AUTOSAR XML (schema 4-2-2)
package /STELLANTIS/EPT/COMSWCs
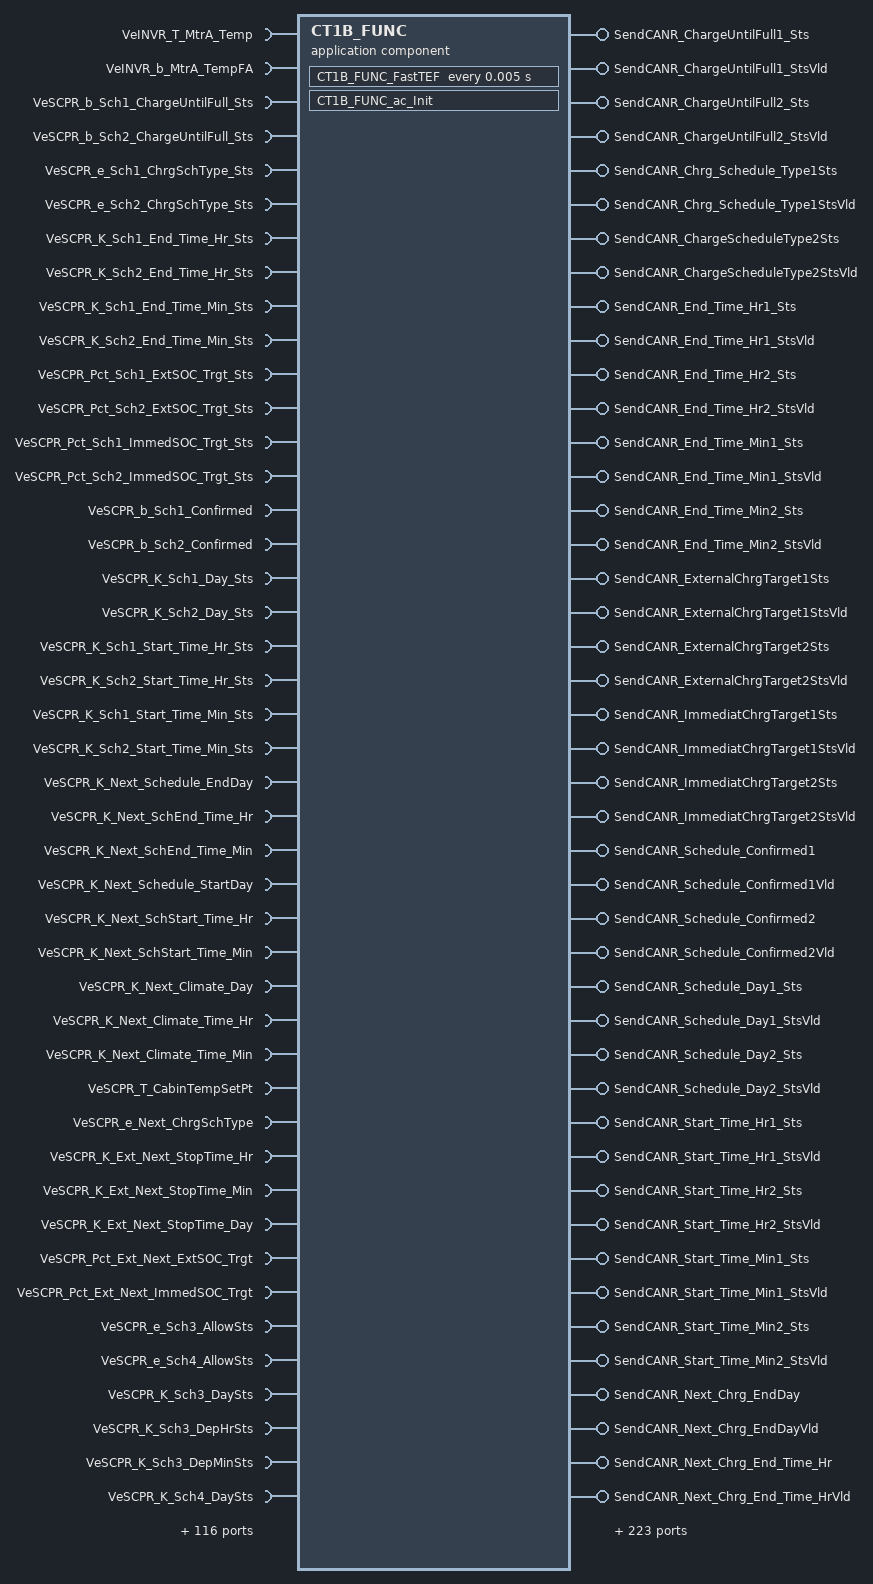
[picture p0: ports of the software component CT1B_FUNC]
  application sw component type CT1B_FUNC
    160 x require port:
      VeINVR_T_MtrA_Temp: variation-point={short-label=vpVeINVR_T_MtrA_Temp, sw-syscond=1}, nonqueued-receiver-com-spec{data-element=Value, init-value=0}, required-interface=VeINVR_T_MtrA_Temp
      VeINVR_b_MtrA_TempFA: variation-point={short-label=vpVeINVR_b_MtrA_TempFA, sw-syscond=1}, nonqueued-receiver-com-spec{data-element=Value, init-value=0}, required-interface=VeINVR_b_MtrA_TempFA
      VeSCPR_b_Sch1_ChargeUntilFull_Sts: nonqueued-receiver-com-spec{data-element=Value, init-value=0}, required-interface=VeSCPR_b_Sch1_ChargeUntilFull_Sts
      VeSCPR_b_Sch2_ChargeUntilFull_Sts: nonqueued-receiver-com-spec{data-element=Value, init-value=0}, required-interface=VeSCPR_b_Sch2_ChargeUntilFull_Sts
      VeSCPR_e_Sch1_ChrgSchType_Sts: nonqueued-receiver-com-spec{data-element=Value, init-value=CeCITR_e_No_Selection}, required-interface=VeSCPR_e_Sch1_ChrgSchType_Sts
      VeSCPR_e_Sch2_ChrgSchType_Sts: nonqueued-receiver-com-spec{data-element=Value, init-value=CeCITR_e_No_Selection}, required-interface=VeSCPR_e_Sch2_ChrgSchType_Sts
      VeSCPR_K_Sch1_End_Time_Hr_Sts: nonqueued-receiver-com-spec{data-element=Value, init-value=0}, required-interface=VeSCPR_K_Sch1_End_Time_Hr_Sts
      VeSCPR_K_Sch2_End_Time_Hr_Sts: nonqueued-receiver-com-spec{data-element=Value, init-value=0}, required-interface=VeSCPR_K_Sch2_End_Time_Hr_Sts
      VeSCPR_K_Sch1_End_Time_Min_Sts: nonqueued-receiver-com-spec{data-element=Value, init-value=0}, required-interface=VeSCPR_K_Sch1_End_Time_Min_Sts
      VeSCPR_K_Sch2_End_Time_Min_Sts: nonqueued-receiver-com-spec{data-element=Value, init-value=0}, required-interface=VeSCPR_K_Sch2_End_Time_Min_Sts
      VeSCPR_Pct_Sch1_ExtSOC_Trgt_Sts: nonqueued-receiver-com-spec{data-element=Value, init-value=0}, required-interface=VeSCPR_Pct_Sch1_ExtSOC_Trgt_Sts
      VeSCPR_Pct_Sch2_ExtSOC_Trgt_Sts: nonqueued-receiver-com-spec{data-element=Value, init-value=0}, required-interface=VeSCPR_Pct_Sch2_ExtSOC_Trgt_Sts
      VeSCPR_Pct_Sch1_ImmedSOC_Trgt_Sts: nonqueued-receiver-com-spec{data-element=Value, init-value=0}, required-interface=VeSCPR_Pct_Sch1_ImmedSOC_Trgt_Sts
      VeSCPR_Pct_Sch2_ImmedSOC_Trgt_Sts: nonqueued-receiver-com-spec{data-element=Value, init-value=0}, required-interface=VeSCPR_Pct_Sch2_ImmedSOC_Trgt_Sts
      VeSCPR_b_Sch1_Confirmed: nonqueued-receiver-com-spec{data-element=Value, init-value=0}, required-interface=VeSCPR_b_Sch1_Confirmed
      VeSCPR_b_Sch2_Confirmed: nonqueued-receiver-com-spec{data-element=Value, init-value=0}, required-interface=VeSCPR_b_Sch2_Confirmed
      VeSCPR_K_Sch1_Day_Sts: nonqueued-receiver-com-spec{data-element=Value, init-value=0}, required-interface=VeSCPR_K_Sch1_Day_Sts
      VeSCPR_K_Sch2_Day_Sts: nonqueued-receiver-com-spec{data-element=Value, init-value=0}, required-interface=VeSCPR_K_Sch2_Day_Sts
      VeSCPR_K_Sch1_Start_Time_Hr_Sts: nonqueued-receiver-com-spec{data-element=Value, init-value=0}, required-interface=VeSCPR_K_Sch1_Start_Time_Hr_Sts
      VeSCPR_K_Sch2_Start_Time_Hr_Sts: nonqueued-receiver-com-spec{data-element=Value, init-value=0}, required-interface=VeSCPR_K_Sch2_Start_Time_Hr_Sts
      VeSCPR_K_Sch1_Start_Time_Min_Sts: nonqueued-receiver-com-spec{data-element=Value, init-value=0}, required-interface=VeSCPR_K_Sch1_Start_Time_Min_Sts
      VeSCPR_K_Sch2_Start_Time_Min_Sts: nonqueued-receiver-com-spec{data-element=Value, init-value=0}, required-interface=VeSCPR_K_Sch2_Start_Time_Min_Sts
      VeSCPR_K_Next_Schedule_EndDay: nonqueued-receiver-com-spec{data-element=Value, init-value=0}, required-interface=VeSCPR_K_Next_Schedule_EndDay
      VeSCPR_K_Next_SchEnd_Time_Hr: nonqueued-receiver-com-spec{data-element=Value, init-value=0}, required-interface=VeSCPR_K_Next_SchEnd_Time_Hr
      VeSCPR_K_Next_SchEnd_Time_Min: nonqueued-receiver-com-spec{data-element=Value, init-value=0}, required-interface=VeSCPR_K_Next_SchEnd_Time_Min
      VeSCPR_K_Next_Schedule_StartDay: nonqueued-receiver-com-spec{data-element=Value, init-value=0}, required-interface=VeSCPR_K_Next_Schedule_StartDay
      VeSCPR_K_Next_SchStart_Time_Hr: nonqueued-receiver-com-spec{data-element=Value, init-value=0}, required-interface=VeSCPR_K_Next_SchStart_Time_Hr
      VeSCPR_K_Next_SchStart_Time_Min: nonqueued-receiver-com-spec{data-element=Value, init-value=0}, required-interface=VeSCPR_K_Next_SchStart_Time_Min
      VeSCPR_K_Next_Climate_Day: nonqueued-receiver-com-spec{data-element=Value, init-value=0}, required-interface=VeSCPR_K_Next_Climate_Day
      VeSCPR_K_Next_Climate_Time_Hr: nonqueued-receiver-com-spec{data-element=Value, init-value=0}, required-interface=VeSCPR_K_Next_Climate_Time_Hr
      VeSCPR_K_Next_Climate_Time_Min: nonqueued-receiver-com-spec{data-element=Value, init-value=0}, required-interface=VeSCPR_K_Next_Climate_Time_Min
      VeSCPR_T_CabinTempSetPt: nonqueued-receiver-com-spec{data-element=Value, init-value=0}, required-interface=VeSCPR_T_CabinTempSetPt
      VeSCPR_e_Next_ChrgSchType: nonqueued-receiver-com-spec{data-element=Value, init-value=CeSCPR_e_No_Selection}, required-interface=VeSCPR_e_Next_ChrgSchType
      VeSCPR_K_Ext_Next_StopTime_Hr: nonqueued-receiver-com-spec{data-element=Value, init-value=0}, required-interface=VeSCPR_K_Ext_Next_StopTime_Hr
      VeSCPR_K_Ext_Next_StopTime_Min: nonqueued-receiver-com-spec{data-element=Value, init-value=0}, required-interface=VeSCPR_K_Ext_Next_StopTime_Min
      VeSCPR_K_Ext_Next_StopTime_Day: nonqueued-receiver-com-spec{data-element=Value, init-value=0}, required-interface=VeSCPR_K_Ext_Next_StopTime_Day
      VeSCPR_Pct_Ext_Next_ExtSOC_Trgt: nonqueued-receiver-com-spec{data-element=Value, init-value=0}, required-interface=VeSCPR_Pct_Ext_Next_ExtSOC_Trgt
      VeSCPR_Pct_Ext_Next_ImmedSOC_Trgt: nonqueued-receiver-com-spec{data-element=Value, init-value=0}, required-interface=VeSCPR_Pct_Ext_Next_ImmedSOC_Trgt
      VeSCPR_e_Sch3_AllowSts: nonqueued-receiver-com-spec{data-element=Value, init-value=CeCITR_e_AnyTime}, required-interface=VeSCPR_e_Sch3_AllowSts
      VeSCPR_e_Sch4_AllowSts: nonqueued-receiver-com-spec{data-element=Value, init-value=CeCITR_e_AnyTime}, required-interface=VeSCPR_e_Sch4_AllowSts
      VeSCPR_K_Sch3_DaySts: nonqueued-receiver-com-spec{data-element=Value, init-value=0}, required-interface=VeSCPR_K_Sch3_DaySts
      VeSCPR_K_Sch3_DepHrSts: nonqueued-receiver-com-spec{data-element=Value, init-value=0}, required-interface=VeSCPR_K_Sch3_DepHrSts
      VeSCPR_K_Sch3_DepMinSts: nonqueued-receiver-com-spec{data-element=Value, init-value=0}, required-interface=VeSCPR_K_Sch3_DepMinSts
      VeSCPR_K_Sch4_DaySts: nonqueued-receiver-com-spec{data-element=Value, init-value=0}, required-interface=VeSCPR_K_Sch4_DaySts
      VeSCPR_K_Sch4_DepHrSts: nonqueued-receiver-com-spec{data-element=Value, init-value=0}, required-interface=VeSCPR_K_Sch4_DepHrSts
      VeSCPR_K_Sch4_DepMinSts: nonqueued-receiver-com-spec{data-element=Value, init-value=0}, required-interface=VeSCPR_K_Sch4_DepMinSts
      VeSCPR_T_Sch3_DepTempSts: nonqueued-receiver-com-spec{data-element=Value, init-value=0}, required-interface=VeSCPR_T_Sch3_DepTempSts
      VeSCPR_T_Sch4_DepTempSts: nonqueued-receiver-com-spec{data-element=Value, init-value=0}, required-interface=VeSCPR_T_Sch4_DepTempSts
      VeSCPR_b_Sch3_EnblSts: nonqueued-receiver-com-spec{data-element=Value, init-value=0}, required-interface=VeSCPR_b_Sch3_EnblSts
      VeSCPR_b_Sch4_EnblSts: nonqueued-receiver-com-spec{data-element=Value, init-value=0}, required-interface=VeSCPR_b_Sch4_EnblSts
      VeVTHR_e_FOTA_ReadySts: variation-point={short-label=vpVeVTHR_e_FOTA_ReadySts, sw-syscond=1}, nonqueued-receiver-com-spec{data-element=Value, init-value=CeVTHR_e_Eval_in_Progress}, required-interface=VeVTHR_e_FOTA_ReadySts
      VeOBCR_e_ChargeportLock_Sts: nonqueued-receiver-com-spec{data-element=Value, init-value=CeOBCR_e_PortLockSts_Default}, required-interface=VeOBCR_e_ChargeportLock_Sts
      VeSCPR_e_CoopChrgStatus: nonqueued-receiver-com-spec{data-element=Value, init-value=CeSCPR_e_DefaultSts}, required-interface=VeSCPR_e_CoopChrgStatus
      VeOBCR_P_EVSEPwr: variation-point={short-label=vpVeOBCR_P_EVSEPwr, sw-syscond=1}, nonqueued-receiver-com-spec{data-element=Value, init-value=0}, required-interface=VeOBCR_P_EVSEPwr
      VeOBCR_I_ChrgCrntReqDelta: variation-point={short-label=vpVeOBCR_I_ChrgCrntReqDelta, sw-syscond=1}, nonqueued-receiver-com-spec{data-element=Value, init-value=0}, required-interface=VeOBCR_I_ChrgCrntReqDelta
      VeOBCR_P_PowertoBattery: variation-point={short-label=vpVeOBCR_P_PowertoBattery, sw-syscond=1}, nonqueued-receiver-com-spec{data-element=Value, init-value=0}, required-interface=VeOBCR_P_PowertoBattery
      VeOBCR_q_BatteryAmpHrCap: variation-point={short-label=vpVeOBCR_q_BatteryAmpHrCap, sw-syscond=1}, nonqueued-receiver-com-spec{data-element=Value, init-value=0}, required-interface=VeOBCR_q_BatteryAmpHrCap
      VeVTLR_e_DschrgSysSts: nonqueued-receiver-com-spec{data-element=Value, init-value=CeVTLR_e_DschrgInactv}, required-interface=VeVTLR_e_DschrgSysSts
      VeTIMR_e_LaunchMdSwtchLED: variation-point={short-label=vpVeTIMR_e_LaunchMdSwtchLED, sw-syscond=1}, nonqueued-receiver-com-spec{data-element=Value, init-value=CeTIMR_e_LEDOff}, required-interface=VeTIMR_e_LaunchMdSwtchLED
      VeOBCR_b_PnCFailure: nonqueued-receiver-com-spec{data-element=Value, init-value=0}, required-interface=VeOBCR_b_PnCFailure
      VeOBCR_b_PnCRetryFail: nonqueued-receiver-com-spec{data-element=Value, init-value=0}, required-interface=VeOBCR_b_PnCRetryFail
      VeTPCR_b_RacePrepAmbCheck: variation-point={short-label=vpVeTPCR_b_RacePrepAmbCheck, sw-syscond=1}, nonqueued-receiver-com-spec{data-element=Value, init-value=0}, required-interface=VeTPCR_b_RacePrepAmbCheck
      VeOBCR_b_RacePrepBattLvlSts: variation-point={short-label=vpVeOBCR_b_RacePrepBattLvlSts, sw-syscond=1}, nonqueued-receiver-com-spec{data-element=Value, init-value=0}, required-interface=VeOBCR_b_RacePrepBattLvlSts
      VeTPCR_t_RacePrep_DeacTime: variation-point={short-label=vpVeTPCR_t_RacePrep_DeacTime, sw-syscond=1}, nonqueued-receiver-com-spec{data-element=Value, init-value=0}, required-interface=VeTPCR_t_RacePrep_DeacTime
      VeTPCR_b_RacePrepEVSysStatus: variation-point={short-label=vpVeTPCR_b_RacePrepEVSysStatus, sw-syscond=1}, nonqueued-receiver-com-spec{data-element=Value, init-value=0}, required-interface=VeTPCR_b_RacePrepEVSysStatus
      VeTPCR_T_RacePrep_SOCTrgt: variation-point={short-label=vpVeTPCR_T_RacePrep_SOCTrgt, sw-syscond=1}, nonqueued-receiver-com-spec{data-element=Value, init-value=0}, required-interface=VeTPCR_T_RacePrep_SOCTrgt
      VeTIMR_e_RacePrepRaceTypeSts: variation-point={short-label=vpVeTIMR_e_RacePrepRaceTypeSts, sw-syscond=1}, nonqueued-receiver-com-spec{data-element=Value, init-value=CeTIMR_e_RaceType_Drag}, required-interface=VeTIMR_e_RacePrepRaceTypeSts
      VeTPCR_T_RacePrep_ThrmlTrgt: variation-point={short-label=vpVeTPCR_T_RacePrep_ThrmlTrgt, sw-syscond=1}, nonqueued-receiver-com-spec{data-element=Value, init-value=0}, required-interface=VeTPCR_T_RacePrep_ThrmlTrgt
      VeERER_l_AC_Fan_Range: variation-point={short-label=vpVeERER_l_AC_Fan_Range, sw-syscond=1}, nonqueued-receiver-com-spec{data-element=Value, init-value=0}, required-interface=VeERER_l_AC_Fan_Range
      VeERER_b_ACFanRange_SNA: variation-point={short-label=vpVeERER_b_ACFanRange_SNA, sw-syscond=1}, nonqueued-receiver-com-spec{data-element=Value, init-value=0}, required-interface=VeERER_b_ACFanRange_SNA
      VeERER_l_Audio_Range: variation-point={short-label=vpVeERER_l_Audio_Range, sw-syscond=1}, nonqueued-receiver-com-spec{data-element=Value, init-value=0}, required-interface=VeERER_l_Audio_Range
      VeERER_b_AudioRange_SNA: variation-point={short-label=vpVeERER_b_AudioRange_SNA, sw-syscond=1}, nonqueued-receiver-com-spec{data-element=Value, init-value=0}, required-interface=VeERER_b_AudioRange_SNA
      VeERER_l_Defrost_Range: variation-point={short-label=vpVeERER_l_Defrost_Range, sw-syscond=1}, nonqueued-receiver-com-spec{data-element=Value, init-value=0}, required-interface=VeERER_l_Defrost_Range
      VeERER_b_DefrostRange_SNA: variation-point={short-label=vpVeERER_b_DefrostRange_SNA, sw-syscond=1}, nonqueued-receiver-com-spec{data-element=Value, init-value=0}, required-interface=VeERER_b_DefrostRange_SNA
      VeERER_l_Lights_Range: variation-point={short-label=vpVeERER_l_Lights_Range, sw-syscond=1}, nonqueued-receiver-com-spec{data-element=Value, init-value=0}, required-interface=VeERER_l_Lights_Range
      VeERER_b_LightsRange_SNA: variation-point={short-label=vpVeERER_b_LightsRange_SNA, sw-syscond=1}, nonqueued-receiver-com-spec{data-element=Value, init-value=0}, required-interface=VeERER_b_LightsRange_SNA
      VeERER_l_Other_Range: variation-point={short-label=vpVeERER_l_Other_Range, sw-syscond=1}, nonqueued-receiver-com-spec{data-element=Value, init-value=0}, required-interface=VeERER_l_Other_Range
      VeERER_b_OtherRange_SNA: variation-point={short-label=vpVeERER_b_OtherRange_SNA, sw-syscond=1}, nonqueued-receiver-com-spec{data-element=Value, init-value=0}, required-interface=VeERER_b_OtherRange_SNA
      VeERER_l_Seatswhl_Range: variation-point={short-label=vpVeERER_l_Seatswhl_Range, sw-syscond=1}, nonqueued-receiver-com-spec{data-element=Value, init-value=0}, required-interface=VeERER_l_Seatswhl_Range
      VeERER_b_SeatswhlRange_SNA: variation-point={short-label=vpVeERER_b_SeatswhlRange_SNA, sw-syscond=1}, nonqueued-receiver-com-spec{data-element=Value, init-value=0}, required-interface=VeERER_b_SeatswhlRange_SNA
      VeERER_l_Total_Range: variation-point={short-label=vpVeERER_l_Total_Range, sw-syscond=1}, nonqueued-receiver-com-spec{data-element=Value, init-value=0}, required-interface=VeERER_l_Total_Range
      VeERER_b_TotalRange_SNA: variation-point={short-label=vpVeERER_b_TotalRange_SNA, sw-syscond=1}, nonqueued-receiver-com-spec{data-element=Value, init-value=0}, required-interface=VeERER_b_TotalRange_SNA
      VeTIMR_e_RaceMdPopUp: nonqueued-receiver-com-spec{data-element=Value, init-value=CeTIMR_e_TM0}, required-interface=VeTIMR_e_RaceMdPopUp
      VeTHMR_e_CabinPreCondReqStat: nonqueued-receiver-com-spec{data-element=Value, init-value=0}, required-interface=VeTHMR_e_CabinPreCondReqStat
      VeTHMR_e_CabinPreCondReqMsg: nonqueued-receiver-com-spec{data-element=Value, init-value=0}, required-interface=VeTHMR_e_CabinPreCondReqMsg
      VeTAIR_e_CompStat: nonqueued-receiver-com-spec{data-element=Value, init-value=CeTAIR_e_NormalOp}, required-interface=VeTAIR_e_CompStat
      VeTMIR_T_ElecClntHtr_TmpIn: nonqueued-receiver-com-spec{data-element=Value, init-value=0}, required-interface=VeTMIR_T_ElecClntHtr_TmpIn
      VeTMIR_b_ElecClntHtr_TmpIn_FA: nonqueued-receiver-com-spec{data-element=Value, init-value=0}, required-interface=VeTMIR_b_ElecClntHtr_TmpIn_FA
      VeHTRR_P_HVC_HtrPwrAct: nonqueued-receiver-com-spec{data-element=Value, init-value=0}, required-interface=VeHTRR_P_HVC_HtrPwrAct
      VeRCVR_b_FtRfgtShtoff_VlvSts: nonqueued-receiver-com-spec{data-element=Value, init-value=0}, required-interface=VeRCVR_b_FtRfgtShtoff_VlvSts
      VePMIR_e_HTAuxPumpMntrRPM: nonqueued-receiver-com-spec{data-element=Value, init-value=CePMPR_e_TFSNA_False}, required-interface=VePMIR_e_HTAuxPumpMntrRPM
      VePMIR_b_HTAuxPumpMntrRPM_FA: nonqueued-receiver-com-spec{data-element=Value, init-value=0}, required-interface=VePMIR_b_HTAuxPumpMntrRPM_FA
      VePMIR_n_HTAuxPumpRPMAct: nonqueued-receiver-com-spec{data-element=Value, init-value=0}, required-interface=VePMIR_n_HTAuxPumpRPMAct
      VePMIR_b_HTAuxPumpRPMAct_FA: nonqueued-receiver-com-spec{data-element=Value, init-value=0}, required-interface=VePMIR_b_HTAuxPumpRPMAct_FA
      VeRCVR_b_HT_Shtoff_VlvCmd: nonqueued-receiver-com-spec{data-element=Value, init-value=0}, required-interface=VeRCVR_b_HT_Shtoff_VlvCmd
      VeTHMR_e_HV_Bat_CltLvlLo: nonqueued-receiver-com-spec{data-element=Value, init-value=CeBRDR_e_BatCltLvlNotLo}, required-interface=VeTHMR_e_HV_Bat_CltLvlLo
      VeTHMR_b_HV_BatTempCrit_Cond: nonqueued-receiver-com-spec{data-element=Value, init-value=0}, required-interface=VeTHMR_b_HV_BatTempCrit_Cond
      VeTRIR_T_HtrCorClnt_TmpIn: nonqueued-receiver-com-spec{data-element=Value, init-value=0}, required-interface=VeTRIR_T_HtrCorClnt_TmpIn
      VeTRIR_b_HtrCorClnt_TmpIn_FA: nonqueued-receiver-com-spec{data-element=Value, init-value=0}, required-interface=VeTRIR_b_HtrCorClnt_TmpIn_FA
      VeHTIR_T_Htr2CoreTemp: nonqueued-receiver-com-spec{data-element=Value, init-value=0}, required-interface=VeHTIR_T_Htr2CoreTemp
      VeHTIR_T_Htr2_PCBTemp: nonqueued-receiver-com-spec{data-element=Value, init-value=0}, required-interface=VeHTIR_T_Htr2_PCBTemp
      VeHTRR_Pct_HV_Htr2PwrAct: nonqueued-receiver-com-spec{data-element=Value, init-value=0}, required-interface=VeHTRR_Pct_HV_Htr2PwrAct
      VeTPCR_t_TimeToDeparture: nonqueued-receiver-com-spec{data-element=Value, init-value=0}, required-interface=VeTPCR_t_TimeToDeparture
      VeTHMR_e_SC_WkUp: nonqueued-receiver-com-spec{data-element=Value, init-value=CeTPCR_e_SC_NotAwake}, required-interface=VeTHMR_e_SC_WkUp
      VeVTHR_P_V2H_DschgCap: variation-point={short-label=vpVeVTHR_P_V2H_DschgCap, sw-syscond=1}, nonqueued-receiver-com-spec{data-element=Value, init-value=0}, required-interface=VeVTHR_P_V2H_DschgCap
      VeINVR_I_MtrA_DC_Crnt: variation-point={short-label=vpVeINVR_I_MtrA_DC_Crnt, sw-syscond=1}, nonqueued-receiver-com-spec{data-element=Value, init-value=0}, required-interface=VeINVR_I_MtrA_DC_Crnt
      VeINVR_b_MtrA_DC_CrntFA: variation-point={short-label=vpVeINVR_b_MtrA_DC_CrntFA, sw-syscond=1}, nonqueued-receiver-com-spec{data-element=Value, init-value=0}, required-interface=VeINVR_b_MtrA_DC_CrntFA
      VeINVR_U_MtrA_DC_Volt: variation-point={short-label=vpVeINVR_U_MtrA_DC_Volt, sw-syscond=1}, nonqueued-receiver-com-spec{data-element=Value, init-value=0}, required-interface=VeINVR_U_MtrA_DC_Volt
      VeINVR_b_MtrA_DC_VoltFA: variation-point={short-label=vpVeINVR_b_MtrA_DC_VoltFA, sw-syscond=1}, nonqueued-receiver-com-spec{data-element=Value, init-value=0}, required-interface=VeINVR_b_MtrA_DC_VoltFA
      VeINVR_e_MtrA_InvrtrSt: variation-point={short-label=vpVeINVR_e_MtrA_InvrtrSt, sw-syscond=1}, nonqueued-receiver-com-spec{data-element=Value, init-value=CeINVR_e_NormalPowerStageOff}, required-interface=VeINVR_e_MtrA_InvrtrSt
      VeINVR_T_MtrA_InvrtrTemp: variation-point={short-label=vpVeINVR_T_MtrA_InvrtrTemp, sw-syscond=1}, nonqueued-receiver-com-spec{data-element=Value, init-value=0}, required-interface=VeINVR_T_MtrA_InvrtrTemp
      VeINVR_b_MtrA_InvrtrTempFA: variation-point={short-label=vpVeINVR_b_MtrA_InvrtrTempFA, sw-syscond=1}, nonqueued-receiver-com-spec{data-element=Value, init-value=0}, required-interface=VeINVR_b_MtrA_InvrtrTempFA
      VeMSPR_n_MtrA_Spd: variation-point={short-label=vpVeMSPR_n_MtrA_Spd, sw-syscond=1}, nonqueued-receiver-com-spec{data-element=Value, init-value=0}, required-interface=VeMSPR_n_MtrA_Spd
      VeMSPR_b_MtrA_SpdFA: variation-point={short-label=vpVeMSPR_b_MtrA_SpdFA, sw-syscond=1}, nonqueued-receiver-com-spec{data-element=Value, init-value=0}, required-interface=VeMSPR_b_MtrA_SpdFA
      VeMTIR_M_MtrA_TorqAchieved: variation-point={short-label=vpVeMTIR_M_MtrA_TorqAchieved, sw-syscond=1}, nonqueued-receiver-com-spec{data-element=Value, init-value=0}, required-interface=VeMTIR_M_MtrA_TorqAchieved
      VeMTIR_b_MtrA_TorqAchievedFA: variation-point={short-label=vpVeMTIR_b_MtrA_TorqAchievedFA, sw-syscond=1}, nonqueued-receiver-com-spec{data-element=Value, init-value=0}, required-interface=VeMTIR_b_MtrA_TorqAchievedFA
      VeINVR_I_MtrB_DC_Crnt: nonqueued-receiver-com-spec{data-element=Value, init-value=0}, required-interface=VeINVR_I_MtrB_DC_Crnt
      VeINVR_b_MtrB_DC_CrntFA: nonqueued-receiver-com-spec{data-element=Value, init-value=0}, required-interface=VeINVR_b_MtrB_DC_CrntFA
      VeINVR_U_MtrB_DC_Volt: nonqueued-receiver-com-spec{data-element=Value, init-value=0}, required-interface=VeINVR_U_MtrB_DC_Volt
      VeINVR_b_MtrB_DC_VoltFA: nonqueued-receiver-com-spec{data-element=Value, init-value=0}, required-interface=VeINVR_b_MtrB_DC_VoltFA
      VeINVR_e_MtrB_InvrtrSt: nonqueued-receiver-com-spec{data-element=Value, init-value=CeINVR_e_NormalPowerStageOff}, required-interface=VeINVR_e_MtrB_InvrtrSt
      VeINVR_T_MtrB_InvrtrTemp: nonqueued-receiver-com-spec{data-element=Value, init-value=0}, required-interface=VeINVR_T_MtrB_InvrtrTemp
      VeINVR_b_MtrB_InvrtrTempFA: nonqueued-receiver-com-spec{data-element=Value, init-value=0}, required-interface=VeINVR_b_MtrB_InvrtrTempFA
      VeMSPR_n_MtrB_Spd: nonqueued-receiver-com-spec{data-element=Value, init-value=0}, required-interface=VeMSPR_n_MtrB_Spd
      VeMSPR_b_MtrB_SpdFA: nonqueued-receiver-com-spec{data-element=Value, init-value=0}, required-interface=VeMSPR_b_MtrB_SpdFA
      VeINVR_T_MtrB_Temp: nonqueued-receiver-com-spec{data-element=Value, init-value=0}, required-interface=VeINVR_T_MtrB_Temp
      VeINVR_b_MtrB_TempFA: nonqueued-receiver-com-spec{data-element=Value, init-value=0}, required-interface=VeINVR_b_MtrB_TempFA
      VeMTIR_M_MtrB_TorqAchieved: nonqueued-receiver-com-spec{data-element=Value, init-value=0}, required-interface=VeMTIR_M_MtrB_TorqAchieved
      VeMTIR_b_MtrB_TorqAchievedFA: nonqueued-receiver-com-spec{data-element=Value, init-value=0}, required-interface=VeMTIR_b_MtrB_TorqAchievedFA
      VeTHMR_Pct_AirFlowReq: nonqueued-receiver-com-spec{data-element=Value, init-value=0}, required-interface=VeTHMR_Pct_AirFlowReq
      VeTAIR_Pct_RadFanSts: nonqueued-receiver-com-spec{data-element=Value, init-value=0}, required-interface=VeTAIR_Pct_RadFanSts
      VeTAIR_b_RadFanSts_FA: nonqueued-receiver-com-spec{data-element=Value, init-value=0}, required-interface=VeTAIR_b_RadFanSts_FA
      VeOBCR_P_ActChargePowerLim: variation-point={short-label=vpVeOBCR_P_ActChargePowerLim, sw-syscond=1}, nonqueued-receiver-com-spec{data-element=Value, init-value=0}, required-interface=VeOBCR_P_ActChargePowerLim
      VeOBCR_b_ActChargePowerLimFA: variation-point={short-label=vpVeOBCR_b_ActChargePowerLimFA, sw-syscond=1}, nonqueued-receiver-com-spec{data-element=Value, init-value=0}, required-interface=VeOBCR_b_ActChargePowerLimFA
      VeOBCR_P_ActChargePower: variation-point={short-label=vpVeOBCR_P_ActChargePower, sw-syscond=1}, nonqueued-receiver-com-spec{data-element=Value, init-value=0}, required-interface=VeOBCR_P_ActChargePower
      VeOBCR_b_ActChargePowerFA: variation-point={short-label=vpVeOBCR_b_ActChargePowerFA, sw-syscond=1}, nonqueued-receiver-com-spec{data-element=Value, init-value=0}, required-interface=VeOBCR_b_ActChargePowerFA
      VeVTHR_P_V2H_InstPwrDraw: variation-point={short-label=vpVeVTHR_P_V2H_InstPwrDraw, sw-syscond=1}, nonqueued-receiver-com-spec{data-element=Value, init-value=0}, required-interface=VeVTHR_P_V2H_InstPwrDraw
      VeVTHR_Pct_V2H_ResrvBattSts: variation-point={short-label=vpVeVTHR_Pct_V2H_ResrvBattSts, sw-syscond=1}, nonqueued-receiver-com-spec{data-element=Value, init-value=0}, required-interface=VeVTHR_Pct_V2H_ResrvBattSts
      VeVTHR_e_V2H_Sts: variation-point={short-label=vpVeVTHR_e_V2H_Sts, sw-syscond=1}, nonqueued-receiver-com-spec{data-element=Value, init-value=CeVTHR_e_V2H_Inactive}, required-interface=VeVTHR_e_V2H_Sts
      VeVTHR_t_V2H_TotPwrDays: variation-point={short-label=vpVeVTHR_t_V2H_TotPwrDays, sw-syscond=1}, nonqueued-receiver-com-spec{data-element=Value, init-value=0}, required-interface=VeVTHR_t_V2H_TotPwrDays
      VeVTHR_t_V2H_TotPwrHrs: variation-point={short-label=vpVeVTHR_t_V2H_TotPwrHrs, sw-syscond=1}, nonqueued-receiver-com-spec{data-element=Value, init-value=0}, required-interface=VeVTHR_t_V2H_TotPwrHrs
      VeVTHR_t_V2H_TotPwrMin: variation-point={short-label=vpVeVTHR_t_V2H_TotPwrMin, sw-syscond=1}, nonqueued-receiver-com-spec{data-element=Value, init-value=0}, required-interface=VeVTHR_t_V2H_TotPwrMin
      VeVTHR_b_V2H_MdSts: variation-point={short-label=vpVeVTHR_b_V2H_MdSts, sw-syscond=1}, nonqueued-receiver-com-spec{data-element=Value, init-value=0}, required-interface=VeVTHR_b_V2H_MdSts
      VeVTLR_e_FrunkSts: nonqueued-receiver-com-spec{data-element=Value, init-value=CeVTLR_e_Inactive_Frunk}, required-interface=VeVTLR_e_FrunkSts
      VeVTLR_P_InstantPwr_PPIM: nonqueued-receiver-com-spec{data-element=Value, init-value=0}, required-interface=VeVTLR_P_InstantPwr_PPIM
      VeVTLR_P_InstantPwr_IDCM: nonqueued-receiver-com-spec{data-element=Value, init-value=0}, required-interface=VeVTLR_P_InstantPwr_IDCM
      VeVTLR_t_DschrgDays: nonqueued-receiver-com-spec{data-element=Value, init-value=0}, required-interface=VeVTLR_t_DschrgDays
      VeVTLR_t_DschrgHrs: nonqueued-receiver-com-spec{data-element=Value, init-value=0}, required-interface=VeVTLR_t_DschrgHrs
      VeVTLR_t_DschrgMins: nonqueued-receiver-com-spec{data-element=Value, init-value=0}, required-interface=VeVTLR_t_DschrgMins
      VeVTLR_e_TrunkSts: nonqueued-receiver-com-spec{data-element=Value, init-value=CeVTLR_e_Inactive}, required-interface=VeVTLR_e_TrunkSts
      VeVDVR_P_V2V_InstPwrDraw: nonqueued-receiver-com-spec{data-element=Value, init-value=0}, required-interface=VeVDVR_P_V2V_InstPwrDraw
      VeVDVR_e_V2V_Status: nonqueued-receiver-com-spec{data-element=Value, init-value=CeVDVR_e_Inctv}, required-interface=VeVDVR_e_V2V_Status
      VeVDVR_t_V2V_TotalPwrTimeDay: nonqueued-receiver-com-spec{data-element=Value, init-value=0}, required-interface=VeVDVR_t_V2V_TotalPwrTimeDay
      VeVDVR_t_V2V_TotalPwrTimeHs: nonqueued-receiver-com-spec{data-element=Value, init-value=0}, required-interface=VeVDVR_t_V2V_TotalPwrTimeHs
      VeVDVR_t_V2V_TotalPwrTimeMin: nonqueued-receiver-com-spec{data-element=Value, init-value=0}, required-interface=VeVDVR_t_V2V_TotalPwrTimeMin
      VeEBMR_t_PrepCntDwn: nonqueued-receiver-com-spec{data-element=Value, init-value=0}, required-interface=VeEBMR_t_PrepCntDwn
      VeEBMR_Pct_PwrSht_Prep: nonqueued-receiver-com-spec{data-element=Value, init-value=0}, required-interface=VeEBMR_Pct_PwrSht_Prep
      VeASLR_v_TurtleMdSpdLim: nonqueued-receiver-com-spec{data-element=Value, init-value=0}, required-interface=VeASLR_v_TurtleMdSpdLim
      VeTMIR_T_OnBrdChrg_ClntTmpIn: nonqueued-receiver-com-spec{data-element=Value, init-value=0}, required-interface=VeTMIR_T_OnBrdChrg_ClntTmpIn
      VeTMIR_b_OnBrdChrg_ClntTmpIn_FA: nonqueued-receiver-com-spec{data-element=Value, init-value=0}, required-interface=VeTMIR_b_OnBrdChrg_ClntTmpIn_FA
    267 x provide port:
      SendCANR_ChargeUntilFull1_Sts: nonqueued-sender-com-spec{data-element=SendCANR_ChargeUntilFull1_Sts, init-value=0}, provided-interface=SendCANR_ChargeUntilFull1_Sts
      SendCANR_ChargeUntilFull1_StsVld: nonqueued-sender-com-spec{data-element=SendCANR_ChargeUntilFull1_StsVld, init-value=0}, provided-interface=SendCANR_ChargeUntilFull1_StsVld
      SendCANR_ChargeUntilFull2_Sts: nonqueued-sender-com-spec{data-element=SendCANR_ChargeUntilFull2_Sts, init-value=0}, provided-interface=SendCANR_ChargeUntilFull2_Sts
      SendCANR_ChargeUntilFull2_StsVld: nonqueued-sender-com-spec{data-element=SendCANR_ChargeUntilFull2_StsVld, init-value=0}, provided-interface=SendCANR_ChargeUntilFull2_StsVld
      SendCANR_Chrg_Schedule_Type1Sts: nonqueued-sender-com-spec{data-element=SendCANR_Chrg_Schedule_Type1Sts, init-value=0}, provided-interface=SendCANR_Chrg_Schedule_Type1Sts
      SendCANR_Chrg_Schedule_Type1StsVld: nonqueued-sender-com-spec{data-element=SendCANR_Chrg_Schedule_Type1StsVld, init-value=0}, provided-interface=SendCANR_Chrg_Schedule_Type1StsVld
      SendCANR_ChargeScheduleType2Sts: nonqueued-sender-com-spec{data-element=SendCANR_ChargeScheduleType2Sts, init-value=0}, provided-interface=SendCANR_ChargeScheduleType2Sts
      SendCANR_ChargeScheduleType2StsVld: nonqueued-sender-com-spec{data-element=SendCANR_ChargeScheduleType2StsVld, init-value=0}, provided-interface=SendCANR_ChargeScheduleType2StsVld
      SendCANR_End_Time_Hr1_Sts: nonqueued-sender-com-spec{data-element=SendCANR_End_Time_Hr1_Sts, init-value=0}, provided-interface=SendCANR_End_Time_Hr1_Sts
      SendCANR_End_Time_Hr1_StsVld: nonqueued-sender-com-spec{data-element=SendCANR_End_Time_Hr1_StsVld, init-value=0}, provided-interface=SendCANR_End_Time_Hr1_StsVld
      SendCANR_End_Time_Hr2_Sts: nonqueued-sender-com-spec{data-element=SendCANR_End_Time_Hr2_Sts, init-value=0}, provided-interface=SendCANR_End_Time_Hr2_Sts
      SendCANR_End_Time_Hr2_StsVld: nonqueued-sender-com-spec{data-element=SendCANR_End_Time_Hr2_StsVld, init-value=0}, provided-interface=SendCANR_End_Time_Hr2_StsVld
      SendCANR_End_Time_Min1_Sts: nonqueued-sender-com-spec{data-element=SendCANR_End_Time_Min1_Sts, init-value=0}, provided-interface=SendCANR_End_Time_Min1_Sts
      SendCANR_End_Time_Min1_StsVld: nonqueued-sender-com-spec{data-element=SendCANR_End_Time_Min1_StsVld, init-value=0}, provided-interface=SendCANR_End_Time_Min1_StsVld
      SendCANR_End_Time_Min2_Sts: nonqueued-sender-com-spec{data-element=SendCANR_End_Time_Min2_Sts, init-value=0}, provided-interface=SendCANR_End_Time_Min2_Sts
      SendCANR_End_Time_Min2_StsVld: nonqueued-sender-com-spec{data-element=SendCANR_End_Time_Min2_StsVld, init-value=0}, provided-interface=SendCANR_End_Time_Min2_StsVld
      SendCANR_ExternalChrgTarget1Sts: nonqueued-sender-com-spec{data-element=SendCANR_ExternalChrgTarget1Sts, init-value=0}, provided-interface=SendCANR_ExternalChrgTarget1Sts
      SendCANR_ExternalChrgTarget1StsVld: nonqueued-sender-com-spec{data-element=SendCANR_ExternalChrgTarget1StsVld, init-value=0}, provided-interface=SendCANR_ExternalChrgTarget1StsVld
      SendCANR_ExternalChrgTarget2Sts: nonqueued-sender-com-spec{data-element=SendCANR_ExternalChrgTarget2Sts, init-value=0}, provided-interface=SendCANR_ExternalChrgTarget2Sts
      SendCANR_ExternalChrgTarget2StsVld: nonqueued-sender-com-spec{data-element=SendCANR_ExternalChrgTarget2StsVld, init-value=0}, provided-interface=SendCANR_ExternalChrgTarget2StsVld
      SendCANR_ImmediatChrgTarget1Sts: nonqueued-sender-com-spec{data-element=SendCANR_ImmediatChrgTarget1Sts, init-value=0}, provided-interface=SendCANR_ImmediatChrgTarget1Sts
      SendCANR_ImmediatChrgTarget1StsVld: nonqueued-sender-com-spec{data-element=SendCANR_ImmediatChrgTarget1StsVld, init-value=0}, provided-interface=SendCANR_ImmediatChrgTarget1StsVld
      SendCANR_ImmediatChrgTarget2Sts: nonqueued-sender-com-spec{data-element=SendCANR_ImmediatChrgTarget2Sts, init-value=0}, provided-interface=SendCANR_ImmediatChrgTarget2Sts
      SendCANR_ImmediatChrgTarget2StsVld: nonqueued-sender-com-spec{data-element=SendCANR_ImmediatChrgTarget2StsVld, init-value=0}, provided-interface=SendCANR_ImmediatChrgTarget2StsVld
      SendCANR_Schedule_Confirmed1: nonqueued-sender-com-spec{data-element=SendCANR_Schedule_Confirmed1, init-value=0}, provided-interface=SendCANR_Schedule_Confirmed1
      SendCANR_Schedule_Confirmed1Vld: nonqueued-sender-com-spec{data-element=SendCANR_Schedule_Confirmed1Vld, init-value=0}, provided-interface=SendCANR_Schedule_Confirmed1Vld
      SendCANR_Schedule_Confirmed2: nonqueued-sender-com-spec{data-element=SendCANR_Schedule_Confirmed2, init-value=0}, provided-interface=SendCANR_Schedule_Confirmed2
      SendCANR_Schedule_Confirmed2Vld: nonqueued-sender-com-spec{data-element=SendCANR_Schedule_Confirmed2Vld, init-value=0}, provided-interface=SendCANR_Schedule_Confirmed2Vld
      SendCANR_Schedule_Day1_Sts: nonqueued-sender-com-spec{data-element=SendCANR_Schedule_Day1_Sts, init-value=0}, provided-interface=SendCANR_Schedule_Day1_Sts
      SendCANR_Schedule_Day1_StsVld: nonqueued-sender-com-spec{data-element=SendCANR_Schedule_Day1_StsVld, init-value=0}, provided-interface=SendCANR_Schedule_Day1_StsVld
      SendCANR_Schedule_Day2_Sts: nonqueued-sender-com-spec{data-element=SendCANR_Schedule_Day2_Sts, init-value=0}, provided-interface=SendCANR_Schedule_Day2_Sts
      SendCANR_Schedule_Day2_StsVld: nonqueued-sender-com-spec{data-element=SendCANR_Schedule_Day2_StsVld, init-value=0}, provided-interface=SendCANR_Schedule_Day2_StsVld
      SendCANR_Start_Time_Hr1_Sts: nonqueued-sender-com-spec{data-element=SendCANR_Start_Time_Hr1_Sts, init-value=0}, provided-interface=SendCANR_Start_Time_Hr1_Sts
      SendCANR_Start_Time_Hr1_StsVld: nonqueued-sender-com-spec{data-element=SendCANR_Start_Time_Hr1_StsVld, init-value=0}, provided-interface=SendCANR_Start_Time_Hr1_StsVld
      SendCANR_Start_Time_Hr2_Sts: nonqueued-sender-com-spec{data-element=SendCANR_Start_Time_Hr2_Sts, init-value=0}, provided-interface=SendCANR_Start_Time_Hr2_Sts
      SendCANR_Start_Time_Hr2_StsVld: nonqueued-sender-com-spec{data-element=SendCANR_Start_Time_Hr2_StsVld, init-value=0}, provided-interface=SendCANR_Start_Time_Hr2_StsVld
      SendCANR_Start_Time_Min1_Sts: nonqueued-sender-com-spec{data-element=SendCANR_Start_Time_Min1_Sts, init-value=0}, provided-interface=SendCANR_Start_Time_Min1_Sts
      SendCANR_Start_Time_Min1_StsVld: nonqueued-sender-com-spec{data-element=SendCANR_Start_Time_Min1_StsVld, init-value=0}, provided-interface=SendCANR_Start_Time_Min1_StsVld
      SendCANR_Start_Time_Min2_Sts: nonqueued-sender-com-spec{data-element=SendCANR_Start_Time_Min2_Sts, init-value=0}, provided-interface=SendCANR_Start_Time_Min2_Sts
      SendCANR_Start_Time_Min2_StsVld: nonqueued-sender-com-spec{data-element=SendCANR_Start_Time_Min2_StsVld, init-value=0}, provided-interface=SendCANR_Start_Time_Min2_StsVld
      SendCANR_Next_Chrg_EndDay: nonqueued-sender-com-spec{data-element=SendCANR_Next_Chrg_EndDay, init-value=0}, provided-interface=SendCANR_Next_Chrg_EndDay
      SendCANR_Next_Chrg_EndDayVld: nonqueued-sender-com-spec{data-element=SendCANR_Next_Chrg_EndDayVld, init-value=0}, provided-interface=SendCANR_Next_Chrg_EndDayVld
      SendCANR_Next_Chrg_End_Time_Hr: nonqueued-sender-com-spec{data-element=SendCANR_Next_Chrg_End_Time_Hr, init-value=0}, provided-interface=SendCANR_Next_Chrg_End_Time_Hr
      SendCANR_Next_Chrg_End_Time_HrVld: nonqueued-sender-com-spec{data-element=SendCANR_Next_Chrg_End_Time_HrVld, init-value=0}, provided-interface=SendCANR_Next_Chrg_End_Time_HrVld
      SendCANR_Next_Chrg_End_Time_Min: nonqueued-sender-com-spec{data-element=SendCANR_Next_Chrg_End_Time_Min, init-value=0}, provided-interface=SendCANR_Next_Chrg_End_Time_Min
      SendCANR_Next_Chrg_End_Time_MinVld: nonqueued-sender-com-spec{data-element=SendCANR_Next_Chrg_End_Time_MinVld, init-value=0}, provided-interface=SendCANR_Next_Chrg_End_Time_MinVld
      SendCANR_Next_Charge_StartDay: nonqueued-sender-com-spec{data-element=SendCANR_Next_Charge_StartDay, init-value=0}, provided-interface=SendCANR_Next_Charge_StartDay
      SendCANR_Next_Charge_StartDayVld: nonqueued-sender-com-spec{data-element=SendCANR_Next_Charge_StartDayVld, init-value=0}, provided-interface=SendCANR_Next_Charge_StartDayVld
      SendCANR_Next_Chrg_Strt_Time_Hr: nonqueued-sender-com-spec{data-element=SendCANR_Next_Chrg_Strt_Time_Hr, init-value=0}, provided-interface=SendCANR_Next_Chrg_Strt_Time_Hr
      SendCANR_Next_Chrg_Strt_Time_HrVld: nonqueued-sender-com-spec{data-element=SendCANR_Next_Chrg_Strt_Time_HrVld, init-value=0}, provided-interface=SendCANR_Next_Chrg_Strt_Time_HrVld
      SendCANR_NextChrg_Strt_Time_Min: nonqueued-sender-com-spec{data-element=SendCANR_NextChrg_Strt_Time_Min, init-value=0}, provided-interface=SendCANR_NextChrg_Strt_Time_Min
      SendCANR_NextChrg_Strt_Time_MinVld: nonqueued-sender-com-spec{data-element=SendCANR_NextChrg_Strt_Time_MinVld, init-value=0}, provided-interface=SendCANR_NextChrg_Strt_Time_MinVld
      SendCANR_Next_Climate_Day: nonqueued-sender-com-spec{data-element=SendCANR_Next_Climate_Day, init-value=0}, provided-interface=SendCANR_Next_Climate_Day
      SendCANR_Next_Climate_DayVld: nonqueued-sender-com-spec{data-element=SendCANR_Next_Climate_DayVld, init-value=0}, provided-interface=SendCANR_Next_Climate_DayVld
      SendCANR_Next_Climate_Time_Hr: nonqueued-sender-com-spec{data-element=SendCANR_Next_Climate_Time_Hr, init-value=0}, provided-interface=SendCANR_Next_Climate_Time_Hr
      SendCANR_Next_Climate_Time_HrVld: nonqueued-sender-com-spec{data-element=SendCANR_Next_Climate_Time_HrVld, init-value=0}, provided-interface=SendCANR_Next_Climate_Time_HrVld
      SendCANR_Next_Climate_Time_Min: nonqueued-sender-com-spec{data-element=SendCANR_Next_Climate_Time_Min, init-value=0}, provided-interface=SendCANR_Next_Climate_Time_Min
      SendCANR_Next_Climate_Time_MinVld: nonqueued-sender-com-spec{data-element=SendCANR_Next_Climate_Time_MinVld, init-value=0}, provided-interface=SendCANR_Next_Climate_Time_MinVld
      SendCANR_Next_SchCabin_Temp: nonqueued-sender-com-spec{data-element=SendCANR_Next_SchCabin_Temp, init-value=0}, provided-interface=SendCANR_Next_SchCabin_Temp
      SendCANR_Next_SchCabin_TempVld: nonqueued-sender-com-spec{data-element=SendCANR_Next_SchCabin_TempVld, init-value=0}, provided-interface=SendCANR_Next_SchCabin_TempVld
      SendCANR_Nxt_ChargeScheduleType: nonqueued-sender-com-spec{data-element=SendCANR_Nxt_ChargeScheduleType, init-value=0}, provided-interface=SendCANR_Nxt_ChargeScheduleType
      SendCANR_Nxt_ChargeScheduleTypeVld: nonqueued-sender-com-spec{data-element=SendCANR_Nxt_ChargeScheduleTypeVld, init-value=0}, provided-interface=SendCANR_Nxt_ChargeScheduleTypeVld
      SendCANR_NxtExtChargEndTimeHr: nonqueued-sender-com-spec{data-element=SendCANR_NxtExtChargEndTimeHr, init-value=0}, provided-interface=SendCANR_NxtExtChargEndTimeHr
      SendCANR_NxtExtChargEndTimeHrVld: nonqueued-sender-com-spec{data-element=SendCANR_NxtExtChargEndTimeHrVld, init-value=0}, provided-interface=SendCANR_NxtExtChargEndTimeHrVld
      SendCANR_NxtExtChargeEndTimeMin: nonqueued-sender-com-spec{data-element=SendCANR_NxtExtChargeEndTimeMin, init-value=0}, provided-interface=SendCANR_NxtExtChargeEndTimeMin
      SendCANR_NxtExtChargeEndTimeMinVld: nonqueued-sender-com-spec{data-element=SendCANR_NxtExtChargeEndTimeMinVld, init-value=0}, provided-interface=SendCANR_NxtExtChargeEndTimeMinVld
      SendCANR_NxtExternalChargEndDay: nonqueued-sender-com-spec{data-element=SendCANR_NxtExternalChargEndDay, init-value=0}, provided-interface=SendCANR_NxtExternalChargEndDay
      SendCANR_NxtExternalChargEndDayVld: nonqueued-sender-com-spec{data-element=SendCANR_NxtExternalChargEndDayVld, init-value=0}, provided-interface=SendCANR_NxtExternalChargEndDayVld
      SendCANR_NxtExternlChrgExtnlTgt: nonqueued-sender-com-spec{data-element=SendCANR_NxtExternlChrgExtnlTgt, init-value=0}, provided-interface=SendCANR_NxtExternlChrgExtnlTgt
      SendCANR_NxtExternlChrgExtnlTgtVld: nonqueued-sender-com-spec{data-element=SendCANR_NxtExternlChrgExtnlTgtVld, init-value=0}, provided-interface=SendCANR_NxtExternlChrgExtnlTgtVld
      SendCANR_NxtExtnlChrgImediatTgt: nonqueued-sender-com-spec{data-element=SendCANR_NxtExtnlChrgImediatTgt, init-value=0}, provided-interface=SendCANR_NxtExtnlChrgImediatTgt
      SendCANR_NxtExtnlChrgImediatTgtVld: nonqueued-sender-com-spec{data-element=SendCANR_NxtExtnlChrgImediatTgtVld, init-value=0}, provided-interface=SendCANR_NxtExtnlChrgImediatTgtVld
      SendCANR_AllowClimateSchd1_Sts: nonqueued-sender-com-spec{data-element=SendCANR_AllowClimateSchd1_Sts, init-value=0}, provided-interface=SendCANR_AllowClimateSchd1_Sts
      SendCANR_AllowClimateSchd1_StsVld: nonqueued-sender-com-spec{data-element=SendCANR_AllowClimateSchd1_StsVld, init-value=0}, provided-interface=SendCANR_AllowClimateSchd1_StsVld
      SendCANR_AllowClimateSchd2_Sts: nonqueued-sender-com-spec{data-element=SendCANR_AllowClimateSchd2_Sts, init-value=0}, provided-interface=SendCANR_AllowClimateSchd2_Sts
      SendCANR_AllowClimateSchd2_StsVld: nonqueued-sender-com-spec{data-element=SendCANR_AllowClimateSchd2_StsVld, init-value=0}, provided-interface=SendCANR_AllowClimateSchd2_StsVld
      SendCANR_ClimateSchd1_Day_Sts: nonqueued-sender-com-spec{data-element=SendCANR_ClimateSchd1_Day_Sts, init-value=0}, provided-interface=SendCANR_ClimateSchd1_Day_Sts
      SendCANR_ClimateSchd1_Day_StsVld: nonqueued-sender-com-spec{data-element=SendCANR_ClimateSchd1_Day_StsVld, init-value=0}, provided-interface=SendCANR_ClimateSchd1_Day_StsVld
      SendCANR_ClimateSchd1DprtrHrSts: nonqueued-sender-com-spec{data-element=SendCANR_ClimateSchd1DprtrHrSts, init-value=0}, provided-interface=SendCANR_ClimateSchd1DprtrHrSts
      SendCANR_ClimateSchd1DprtrHrStsVld: nonqueued-sender-com-spec{data-element=SendCANR_ClimateSchd1DprtrHrStsVld, init-value=0}, provided-interface=SendCANR_ClimateSchd1DprtrHrStsVld
      SendCANR_ClimSchd1Dprtr_Min_Sts: nonqueued-sender-com-spec{data-element=SendCANR_ClimSchd1Dprtr_Min_Sts, init-value=0}, provided-interface=SendCANR_ClimSchd1Dprtr_Min_Sts
      SendCANR_ClimSchd1Dprtr_Min_StsVld: nonqueued-sender-com-spec{data-element=SendCANR_ClimSchd1Dprtr_Min_StsVld, init-value=0}, provided-interface=SendCANR_ClimSchd1Dprtr_Min_StsVld
      SendCANR_ClimateSchd2_Day_Sts: nonqueued-sender-com-spec{data-element=SendCANR_ClimateSchd2_Day_Sts, init-value=0}, provided-interface=SendCANR_ClimateSchd2_Day_Sts
      SendCANR_ClimateSchd2_Day_StsVld: nonqueued-sender-com-spec{data-element=SendCANR_ClimateSchd2_Day_StsVld, init-value=0}, provided-interface=SendCANR_ClimateSchd2_Day_StsVld
      SendCANR_ClimateSchd2DprtrHrSts: nonqueued-sender-com-spec{data-element=SendCANR_ClimateSchd2DprtrHrSts, init-value=0}, provided-interface=SendCANR_ClimateSchd2DprtrHrSts
      SendCANR_ClimateSchd2DprtrHrStsVld: nonqueued-sender-com-spec{data-element=SendCANR_ClimateSchd2DprtrHrStsVld, init-value=0}, provided-interface=SendCANR_ClimateSchd2DprtrHrStsVld
      SendCANR_ClimatSchd2DprtrMinSts: nonqueued-sender-com-spec{data-element=SendCANR_ClimatSchd2DprtrMinSts, init-value=0}, provided-interface=SendCANR_ClimatSchd2DprtrMinSts
      SendCANR_ClimatSchd2DprtrMinStsVld: nonqueued-sender-com-spec{data-element=SendCANR_ClimatSchd2DprtrMinStsVld, init-value=0}, provided-interface=SendCANR_ClimatSchd2DprtrMinStsVld
      SendCANR_Climate_Cabin_Temp1Sts: nonqueued-sender-com-spec{data-element=SendCANR_Climate_Cabin_Temp1Sts, init-value=0}, provided-interface=SendCANR_Climate_Cabin_Temp1Sts
      SendCANR_Climate_Cabin_Temp1StsVld: nonqueued-sender-com-spec{data-element=SendCANR_Climate_Cabin_Temp1StsVld, init-value=0}, provided-interface=SendCANR_Climate_Cabin_Temp1StsVld
      SendCANR_Climate_Cabin_Temp2Sts: nonqueued-sender-com-spec{data-element=SendCANR_Climate_Cabin_Temp2Sts, init-value=0}, provided-interface=SendCANR_Climate_Cabin_Temp2Sts
      SendCANR_Climate_Cabin_Temp2StsVld: nonqueued-sender-com-spec{data-element=SendCANR_Climate_Cabin_Temp2StsVld, init-value=0}, provided-interface=SendCANR_Climate_Cabin_Temp2StsVld
      SendCANR_Enbl_ClimateSchd1_Sts: nonqueued-sender-com-spec{data-element=SendCANR_Enbl_ClimateSchd1_Sts, init-value=0}, provided-interface=SendCANR_Enbl_ClimateSchd1_Sts
      SendCANR_Enbl_ClimateSchd1_StsVld: nonqueued-sender-com-spec{data-element=SendCANR_Enbl_ClimateSchd1_StsVld, init-value=0}, provided-interface=SendCANR_Enbl_ClimateSchd1_StsVld
      SendCANR_Enabl_ClimateSchd2_Sts: nonqueued-sender-com-spec{data-element=SendCANR_Enabl_ClimateSchd2_Sts, init-value=0}, provided-interface=SendCANR_Enabl_ClimateSchd2_Sts
      SendCANR_Enabl_ClimateSchd2_StsVld: nonqueued-sender-com-spec{data-element=SendCANR_Enabl_ClimateSchd2_StsVld, init-value=0}, provided-interface=SendCANR_Enabl_ClimateSchd2_StsVld
      SendCANR_Ready_Status_EVCU2: variation-point={short-label=vpSendCANR_Ready_Status_EVCU2, sw-syscond=1}, nonqueued-sender-com-spec{data-element=SendCANR_Ready_Status_EVCU2, init-value=0}, provided-interface=SendCANR_Ready_Status_EVCU2
      SendCANR_Ready_Status_EVCU2Vld: variation-point={short-label=vpSendCANR_Ready_Status_EVCU2Vld, sw-syscond=1}, nonqueued-sender-com-spec{data-element=SendCANR_Ready_Status_EVCU2Vld, init-value=0}, provided-interface=SendCANR_Ready_Status_EVCU2Vld
      SendCANR_Chargeport_Lock_Status: nonqueued-sender-com-spec{data-element=SendCANR_Chargeport_Lock_Status, init-value=0}, provided-interface=SendCANR_Chargeport_Lock_Status
      SendCANR_Chargeport_Lock_StatusVld: nonqueued-sender-com-spec{data-element=SendCANR_Chargeport_Lock_StatusVld, init-value=0}, provided-interface=SendCANR_Chargeport_Lock_StatusVld
      SendCANR_Cooperative_Status: nonqueued-sender-com-spec{data-element=SendCANR_Cooperative_Status, init-value=0}, provided-interface=SendCANR_Cooperative_Status
      SendCANR_Cooperative_StatusVld: nonqueued-sender-com-spec{data-element=SendCANR_Cooperative_StatusVld, init-value=0}, provided-interface=SendCANR_Cooperative_StatusVld
      SendCANR_EVSE_Power: variation-point={short-label=vpSendCANR_EVSE_Power, sw-syscond=1}, nonqueued-sender-com-spec{data-element=SendCANR_EVSE_Power, init-value=0}, provided-interface=SendCANR_EVSE_Power
      SendCANR_EVSE_PowerVld: variation-point={short-label=vpSendCANR_EVSE_PowerVld, sw-syscond=1}, nonqueued-sender-com-spec{data-element=SendCANR_EVSE_PowerVld, init-value=0}, provided-interface=SendCANR_EVSE_PowerVld
      SendCANR_EV_Charge_Current: variation-point={short-label=vpSendCANR_EV_Charge_Current, sw-syscond=1}, nonqueued-sender-com-spec{data-element=SendCANR_EV_Charge_Current, init-value=0}, provided-interface=SendCANR_EV_Charge_Current
      SendCANR_EV_Charge_CurrentVld: variation-point={short-label=vpSendCANR_EV_Charge_CurrentVld, sw-syscond=1}, nonqueued-sender-com-spec{data-element=SendCANR_EV_Charge_CurrentVld, init-value=0}, provided-interface=SendCANR_EV_Charge_CurrentVld
      SendCANR_Energy_to_Battery: variation-point={short-label=vpSendCANR_Energy_to_Battery, sw-syscond=1}, nonqueued-sender-com-spec{data-element=SendCANR_Energy_to_Battery, init-value=0}, provided-interface=SendCANR_Energy_to_Battery
      SendCANR_Energy_to_BatteryVld: variation-point={short-label=vpSendCANR_Energy_to_BatteryVld, sw-syscond=1}, nonqueued-sender-com-spec{data-element=SendCANR_Energy_to_BatteryVld, init-value=0}, provided-interface=SendCANR_Energy_to_BatteryVld
      SendCANR_Total_Battery_Capacity: variation-point={short-label=vpSendCANR_Total_Battery_Capacity, sw-syscond=1}, nonqueued-sender-com-spec{data-element=SendCANR_Total_Battery_Capacity, init-value=0}, provided-interface=SendCANR_Total_Battery_Capacity
      SendCANR_Total_Battery_CapacityVld: variation-point={short-label=vpSendCANR_Total_Battery_CapacityVld, sw-syscond=1}, nonqueued-sender-com-spec{data-element=SendCANR_Total_Battery_CapacityVld, init-value=0}, provided-interface=SendCANR_Total_Battery_CapacityVld
      SendCANR_DischrgingSysStatusFD3: nonqueued-sender-com-spec{data-element=SendCANR_DischrgingSysStatusFD3, init-value=0}, provided-interface=SendCANR_DischrgingSysStatusFD3
      SendCANR_DischrgingSysStatusFD3Vld: nonqueued-sender-com-spec{data-element=SendCANR_DischrgingSysStatusFD3Vld, init-value=0}, provided-interface=SendCANR_DischrgingSysStatusFD3Vld
      SendCANR_Launch_Hard_Btn_LED: variation-point={short-label=vpSendCANR_Launch_Hard_Btn_LED, sw-syscond=1}, nonqueued-sender-com-spec{data-element=SendCANR_Launch_Hard_Btn_LED, init-value=0}, provided-interface=SendCANR_Launch_Hard_Btn_LED
      SendCANR_Launch_Hard_Btn_LED_Vld: variation-point={short-label=vpSendCANR_Launch_Hard_Btn_LED_Vld, sw-syscond=1}, nonqueued-sender-com-spec{data-element=SendCANR_Launch_Hard_Btn_LED_Vld, init-value=0}, provided-interface=SendCANR_Launch_Hard_Btn_LED_Vld
      SendCANR_PnC_Failure: nonqueued-sender-com-spec{data-element=SendCANR_PnC_Failure, init-value=0}, provided-interface=SendCANR_PnC_Failure
      SendCANR_PnC_FailureVld: nonqueued-sender-com-spec{data-element=SendCANR_PnC_FailureVld, init-value=0}, provided-interface=SendCANR_PnC_FailureVld
      SendCANR_PnC_Reattepmt_Failure: nonqueued-sender-com-spec{data-element=SendCANR_PnC_Reattepmt_Failure, init-value=0}, provided-interface=SendCANR_PnC_Reattepmt_Failure
      SendCANR_PnC_Reattepmt_FailureVld: nonqueued-sender-com-spec{data-element=SendCANR_PnC_Reattepmt_FailureVld, init-value=0}, provided-interface=SendCANR_PnC_Reattepmt_FailureVld
      SendCANR_RACE_PREP_AMBIENT_TMP: variation-point={short-label=vpSendCANR_RACE_PREP_AMBIENT_TMP, sw-syscond=1}, nonqueued-sender-com-spec{data-element=SendCANR_RACE_PREP_AMBIENT_TMP, init-value=0}, provided-interface=SendCANR_RACE_PREP_AMBIENT_TMP
      SendCANR_RACE_PREP_AMBIENT_TMP_Vld: variation-point={short-label=vpSendCANR_RACE_PREP_AMBIENT_TMP_Vld, sw-syscond=1}, nonqueued-sender-com-spec{data-element=SendCANR_RACE_PREP_AMBIENT_TMP_Vld, init-value=0}, provided-interface=SendCANR_RACE_PREP_AMBIENT_TMP_Vld
      SendCANR_RACE_PREP_BATT_LVL_STS: variation-point={short-label=vpSendCANR_RACE_PREP_BATT_LVL_STS, sw-syscond=1}, nonqueued-sender-com-spec{data-element=SendCANR_RACE_PREP_BATT_LVL_STS, init-value=0}, provided-interface=SendCANR_RACE_PREP_BATT_LVL_STS
      SendCANR_RACE_PREP_BATT_LVL_STS_Vld: variation-point={short-label=vpSendCANR_RACE_PREP_BATT_LVL_STS_Vld, sw-syscond=1}, nonqueued-sender-com-spec{data-element=SendCANR_RACE_PREP_BATT_LVL_STS_Vld, init-value=0}, provided-interface=SendCANR_RACE_PREP_BATT_LVL_STS_Vld
      SendCANR_RACE_PREP_EV_DEAC_TIME: variation-point={short-label=vpSendCANR_RACE_PREP_EV_DEAC_TIME, sw-syscond=1}, nonqueued-sender-com-spec{data-element=SendCANR_RACE_PREP_EV_DEAC_TIME, init-value=0}, provided-interface=SendCANR_RACE_PREP_EV_DEAC_TIME
      SendCANR_RACE_PREP_EV_DEAC_TIME_Vld: variation-point={short-label=vpSendCANR_RACE_PREP_EV_DEAC_TIME_Vld, sw-syscond=1}, nonqueued-sender-com-spec{data-element=SendCANR_RACE_PREP_EV_DEAC_TIME_Vld, init-value=0}, provided-interface=SendCANR_RACE_PREP_EV_DEAC_TIME_Vld
      SendCANR_RACE_PREP_EV_SYS_STS: variation-point={short-label=vpSendCANR_RACE_PREP_EV_SYS_STS, sw-syscond=1}, nonqueued-sender-com-spec{data-element=SendCANR_RACE_PREP_EV_SYS_STS, init-value=0}, provided-interface=SendCANR_RACE_PREP_EV_SYS_STS
      SendCANR_RACE_PREP_EV_SYS_STS_Vld: variation-point={short-label=vpSendCANR_RACE_PREP_EV_SYS_STS_Vld, sw-syscond=1}, nonqueued-sender-com-spec{data-element=SendCANR_RACE_PREP_EV_SYS_STS_Vld, init-value=0}, provided-interface=SendCANR_RACE_PREP_EV_SYS_STS_Vld
      SendCANR_RACE_PRP_HVBTT_SOC_TGT: variation-point={short-label=vpSendCANR_RACE_PRP_HVBTT_SOC_TGT, sw-syscond=1}, nonqueued-sender-com-spec{data-element=SendCANR_RACE_PRP_HVBTT_SOC_TGT, init-value=0}, provided-interface=SendCANR_RACE_PRP_HVBTT_SOC_TGT
      SendCANR_RACE_PRP_HVBTT_SOC_TGT_Vld: variation-point={short-label=vpSendCANR_RACE_PRP_HVBTT_SOC_TGT_Vld, sw-syscond=1}, nonqueued-sender-com-spec{data-element=SendCANR_RACE_PRP_HVBTT_SOC_TGT_Vld, init-value=0}, provided-interface=SendCANR_RACE_PRP_HVBTT_SOC_TGT_Vld
      SendCANR_RACE_PREP_RCE_TYP_STS: variation-point={short-label=vpSendCANR_RACE_PREP_RCE_TYP_STS, sw-syscond=1}, nonqueued-sender-com-spec{data-element=SendCANR_RACE_PREP_RCE_TYP_STS, init-value=0}, provided-interface=SendCANR_RACE_PREP_RCE_TYP_STS
      SendCANR_RACE_PREP_RCE_TYP_STS_Vld: variation-point={short-label=vpSendCANR_RACE_PREP_RCE_TYP_STS_Vld, sw-syscond=1}, nonqueued-sender-com-spec{data-element=SendCANR_RACE_PREP_RCE_TYP_STS_Vld, init-value=0}, provided-interface=SendCANR_RACE_PREP_RCE_TYP_STS_Vld
      SendCANR_RACE_PREP_THERMAL_TGT: variation-point={short-label=vpSendCANR_RACE_PREP_THERMAL_TGT, sw-syscond=1}, nonqueued-sender-com-spec{data-element=SendCANR_RACE_PREP_THERMAL_TGT, init-value=0}, provided-interface=SendCANR_RACE_PREP_THERMAL_TGT
      SendCANR_RACE_PREP_THERMAL_TGT_Vld: variation-point={short-label=vpSendCANR_RACE_PREP_THERMAL_TGT_Vld, sw-syscond=1}, nonqueued-sender-com-spec{data-element=SendCANR_RACE_PREP_THERMAL_TGT_Vld, init-value=0}, provided-interface=SendCANR_RACE_PREP_THERMAL_TGT_Vld
      SendCANR_RI_AC_FAN_Range: variation-point={short-label=vpSendCANR_RI_AC_FAN_Range, sw-syscond=1}, nonqueued-sender-com-spec{data-element=SendCANR_RI_AC_FAN_Range, init-value=0}, provided-interface=SendCANR_RI_AC_FAN_Range
      SendCANR_RI_AC_FAN_RangeVld: variation-point={short-label=vpSendCANR_RI_AC_FAN_RangeVld, sw-syscond=1}, nonqueued-sender-com-spec{data-element=SendCANR_RI_AC_FAN_RangeVld, init-value=0}, provided-interface=SendCANR_RI_AC_FAN_RangeVld
      SendCANR_RI_AUDIO_Range: variation-point={short-label=vpSendCANR_RI_AUDIO_Range, sw-syscond=1}, nonqueued-sender-com-spec{data-element=SendCANR_RI_AUDIO_Range, init-value=0}, provided-interface=SendCANR_RI_AUDIO_Range
      SendCANR_RI_AUDIO_RangeVld: variation-point={short-label=vpSendCANR_RI_AUDIO_RangeVld, sw-syscond=1}, nonqueued-sender-com-spec{data-element=SendCANR_RI_AUDIO_RangeVld, init-value=0}, provided-interface=SendCANR_RI_AUDIO_RangeVld
      SendCANR_RI_DEFROST_Range: variation-point={short-label=vpSendCANR_RI_DEFROST_Range, sw-syscond=1}, nonqueued-sender-com-spec{data-element=SendCANR_RI_DEFROST_Range, init-value=0}, provided-interface=SendCANR_RI_DEFROST_Range
      SendCANR_RI_DEFROST_RangeVld: variation-point={short-label=vpSendCANR_RI_DEFROST_RangeVld, sw-syscond=1}, nonqueued-sender-com-spec{data-element=SendCANR_RI_DEFROST_RangeVld, init-value=0}, provided-interface=SendCANR_RI_DEFROST_RangeVld
      SendCANR_RI_LIGHTS_Range: variation-point={short-label=vpSendCANR_RI_LIGHTS_Range, sw-syscond=1}, nonqueued-sender-com-spec{data-element=SendCANR_RI_LIGHTS_Range, init-value=0}, provided-interface=SendCANR_RI_LIGHTS_Range
      SendCANR_RI_LIGHTS_RangeVld: variation-point={short-label=vpSendCANR_RI_LIGHTS_RangeVld, sw-syscond=1}, nonqueued-sender-com-spec{data-element=SendCANR_RI_LIGHTS_RangeVld, init-value=0}, provided-interface=SendCANR_RI_LIGHTS_RangeVld
      SendCANR_RI_OTHER_Range: variation-point={short-label=vpSendCANR_RI_OTHER_Range, sw-syscond=1}, nonqueued-sender-com-spec{data-element=SendCANR_RI_OTHER_Range, init-value=0}, provided-interface=SendCANR_RI_OTHER_Range
      SendCANR_RI_OTHER_RangeVld: variation-point={short-label=vpSendCANR_RI_OTHER_RangeVld, sw-syscond=1}, nonqueued-sender-com-spec{data-element=SendCANR_RI_OTHER_RangeVld, init-value=0}, provided-interface=SendCANR_RI_OTHER_RangeVld
      SendCANR_RI_SEATSWHL_Range: variation-point={short-label=vpSendCANR_RI_SEATSWHL_Range, sw-syscond=1}, nonqueued-sender-com-spec{data-element=SendCANR_RI_SEATSWHL_Range, init-value=0}, provided-interface=SendCANR_RI_SEATSWHL_Range
      SendCANR_RI_SEATSWHL_RangeVld: variation-point={short-label=vpSendCANR_RI_SEATSWHL_RangeVld, sw-syscond=1}, nonqueued-sender-com-spec{data-element=SendCANR_RI_SEATSWHL_RangeVld, init-value=0}, provided-interface=SendCANR_RI_SEATSWHL_RangeVld
      SendCANR_RI_TOTAL_Range_Add: variation-point={short-label=vpSendCANR_RI_TOTAL_Range_Add, sw-syscond=1}, nonqueued-sender-com-spec{data-element=SendCANR_RI_TOTAL_Range_Add, init-value=0}, provided-interface=SendCANR_RI_TOTAL_Range_Add
      SendCANR_RI_TOTAL_Range_AddVld: variation-point={short-label=vpSendCANR_RI_TOTAL_Range_AddVld, sw-syscond=1}, nonqueued-sender-com-spec{data-element=SendCANR_RI_TOTAL_Range_AddVld, init-value=0}, provided-interface=SendCANR_RI_TOTAL_Range_AddVld
      SendCANR_Racemode_Popup_PT: nonqueued-sender-com-spec{data-element=SendCANR_Racemode_Popup_PT, init-value=0}, provided-interface=SendCANR_Racemode_Popup_PT
      SendCANR_Racemode_Popup_PT_Vld: nonqueued-sender-com-spec{data-element=SendCANR_Racemode_Popup_PT_Vld, init-value=0}, provided-interface=SendCANR_Racemode_Popup_PT_Vld
      SendCANR_CabinConditioningSts: nonqueued-sender-com-spec{data-element=SendCANR_CabinConditioningSts, init-value=0}, provided-interface=SendCANR_CabinConditioningSts
      SendCANR_CabinConditioningStsVld: nonqueued-sender-com-spec{data-element=SendCANR_CabinConditioningStsVld, init-value=0}, provided-interface=SendCANR_CabinConditioningStsVld
      SendCANR_CbnPreconditionReqSts: nonqueued-sender-com-spec{data-element=SendCANR_CbnPreconditionReqSts, init-value=0}, provided-interface=SendCANR_CbnPreconditionReqSts
      SendCANR_CbnPreconditionReqStsVld: nonqueued-sender-com-spec{data-element=SendCANR_CbnPreconditionReqStsVld, init-value=0}, provided-interface=SendCANR_CbnPreconditionReqStsVld
      SendCANR_CompressorState: nonqueued-sender-com-spec{data-element=SendCANR_CompressorState, init-value=0}, provided-interface=SendCANR_CompressorState
      SendCANR_CompressorStateVld: nonqueued-sender-com-spec{data-element=SendCANR_CompressorStateVld, init-value=0}, provided-interface=SendCANR_CompressorStateVld
      SendCANR_ElecClntHtrInletTemp: nonqueued-sender-com-spec{data-element=SendCANR_ElecClntHtrInletTemp, init-value=0}, provided-interface=SendCANR_ElecClntHtrInletTemp
      SendCANR_ElecClntHtrInletTempVld: nonqueued-sender-com-spec{data-element=SendCANR_ElecClntHtrInletTempVld, init-value=0}, provided-interface=SendCANR_ElecClntHtrInletTempVld
      SendCANR_ElecCoolantHtrPwr: nonqueued-sender-com-spec{data-element=SendCANR_ElecCoolantHtrPwr, init-value=0}, provided-interface=SendCANR_ElecCoolantHtrPwr
      SendCANR_ElecCoolantHtrPwrVld: nonqueued-sender-com-spec{data-element=SendCANR_ElecCoolantHtrPwrVld, init-value=0}, provided-interface=SendCANR_ElecCoolantHtrPwrVld
      SendCANR_FRfShVlvSts: nonqueued-sender-com-spec{data-element=SendCANR_FRfShVlvSts, init-value=0}, provided-interface=SendCANR_FRfShVlvSts
      SendCANR_FRfShVlvStsVld: nonqueued-sender-com-spec{data-element=SendCANR_FRfShVlvStsVld, init-value=0}, provided-interface=SendCANR_FRfShVlvStsVld
      SendCANR_HTAuxPmpMontrngRPM: nonqueued-sender-com-spec{data-element=SendCANR_HTAuxPmpMontrngRPM, init-value=0}, provided-interface=SendCANR_HTAuxPmpMontrngRPM
      SendCANR_HTAuxPmpMontrngRPM_Vld: nonqueued-sender-com-spec{data-element=SendCANR_HTAuxPmpMontrngRPM_Vld, init-value=0}, provided-interface=SendCANR_HTAuxPmpMontrngRPM_Vld
      SendCANR_HTAuxPmpRPMAct: nonqueued-sender-com-spec{data-element=SendCANR_HTAuxPmpRPMAct, init-value=0}, provided-interface=SendCANR_HTAuxPmpRPMAct
      SendCANR_HTAuxPmpRPMActVld: nonqueued-sender-com-spec{data-element=SendCANR_HTAuxPmpRPMActVld, init-value=0}, provided-interface=SendCANR_HTAuxPmpRPMActVld
      SendCANR_HTShtOffVlvReq: nonqueued-sender-com-spec{data-element=SendCANR_HTShtOffVlvReq, init-value=0}, provided-interface=SendCANR_HTShtOffVlvReq
      SendCANR_HTShtOffVlvReqVld: nonqueued-sender-com-spec{data-element=SendCANR_HTShtOffVlvReqVld, init-value=0}, provided-interface=SendCANR_HTShtOffVlvReqVld
      SendCANR_HVBatCoolantLvlLo_DPT: nonqueued-sender-com-spec{data-element=SendCANR_HVBatCoolantLvlLo_DPT, init-value=0}, provided-interface=SendCANR_HVBatCoolantLvlLo_DPT
      SendCANR_HVBatCoolantLvlLo_DPT_Vld: nonqueued-sender-com-spec{data-element=SendCANR_HVBatCoolantLvlLo_DPT_Vld, init-value=0}, provided-interface=SendCANR_HVBatCoolantLvlLo_DPT_Vld
      SendCANR_HVBatCritCondT: nonqueued-sender-com-spec{data-element=SendCANR_HVBatCritCondT, init-value=0}, provided-interface=SendCANR_HVBatCritCondT
      SendCANR_HVBatCritCondT_Vld: nonqueued-sender-com-spec{data-element=SendCANR_HVBatCritCondT_Vld, init-value=0}, provided-interface=SendCANR_HVBatCritCondT_Vld
      SendCANR_HeaterCoreInletTemp: nonqueued-sender-com-spec{data-element=SendCANR_HeaterCoreInletTemp, init-value=0}, provided-interface=SendCANR_HeaterCoreInletTemp
      SendCANR_HeaterCoreInletTempVld: nonqueued-sender-com-spec{data-element=SendCANR_HeaterCoreInletTempVld, init-value=0}, provided-interface=SendCANR_HeaterCoreInletTempVld
      SendCANR_RearAirHtrCoreTemp: nonqueued-sender-com-spec{data-element=SendCANR_RearAirHtrCoreTemp, init-value=0}, provided-interface=SendCANR_RearAirHtrCoreTemp
      SendCANR_RearAirHtrCoreTempVld: nonqueued-sender-com-spec{data-element=SendCANR_RearAirHtrCoreTempVld, init-value=0}, provided-interface=SendCANR_RearAirHtrCoreTempVld
      SendCANR_RearAirHtrPCBTemp: nonqueued-sender-com-spec{data-element=SendCANR_RearAirHtrPCBTemp, init-value=0}, provided-interface=SendCANR_RearAirHtrPCBTemp
      SendCANR_RearAirHtrPCBTempVld: nonqueued-sender-com-spec{data-element=SendCANR_RearAirHtrPCBTempVld, init-value=0}, provided-interface=SendCANR_RearAirHtrPCBTempVld
      SendCANR_RearAirHtrPwrCnsAct: nonqueued-sender-com-spec{data-element=SendCANR_RearAirHtrPwrCnsAct, init-value=0}, provided-interface=SendCANR_RearAirHtrPwrCnsAct
      SendCANR_RearAirHtrPwrCnsActVld: nonqueued-sender-com-spec{data-element=SendCANR_RearAirHtrPwrCnsActVld, init-value=0}, provided-interface=SendCANR_RearAirHtrPwrCnsActVld
      SendCANR_SchCond_Time_Till_Dep: nonqueued-sender-com-spec{data-element=SendCANR_SchCond_Time_Till_Dep, init-value=0}, provided-interface=SendCANR_SchCond_Time_Till_Dep
      SendCANR_SchCond_Time_Till_DepVld: nonqueued-sender-com-spec{data-element=SendCANR_SchCond_Time_Till_DepVld, init-value=0}, provided-interface=SendCANR_SchCond_Time_Till_DepVld
      SendCANR_Sch_PreCondition_Sts: nonqueued-sender-com-spec{data-element=SendCANR_Sch_PreCondition_Sts, init-value=0}, provided-interface=SendCANR_Sch_PreCondition_Sts
      SendCANR_Sch_PreCondition_StsVld: nonqueued-sender-com-spec{data-element=SendCANR_Sch_PreCondition_StsVld, init-value=0}, provided-interface=SendCANR_Sch_PreCondition_StsVld
      SendCANR_V2H_Discharge_Capacity: variation-point={short-label=vpSendCANR_V2H_Discharge_Capacity, sw-syscond=1}, nonqueued-sender-com-spec{data-element=SendCANR_V2H_Discharge_Capacity, init-value=0}, provided-interface=SendCANR_V2H_Discharge_Capacity
      SendCANR_V2H_Discharge_CapacityVld: variation-point={short-label=vpSendCANR_V2H_Discharge_CapacityVld, sw-syscond=1}, nonqueued-sender-com-spec{data-element=SendCANR_V2H_Discharge_CapacityVld, init-value=0}, provided-interface=SendCANR_V2H_Discharge_CapacityVld
      SendCANR_MotorA_DC_Current: variation-point={short-label=vpSendCANR_MotorA_DC_Current, sw-syscond=1}, nonqueued-sender-com-spec{data-element=SendCANR_MotorA_DC_Current, init-value=0}, provided-interface=SendCANR_MotorA_DC_Current
      SendCANR_MotorA_DC_CurrentVld: variation-point={short-label=vpSendCANR_MotorA_DC_CurrentVld, sw-syscond=1}, nonqueued-sender-com-spec{data-element=SendCANR_MotorA_DC_CurrentVld, init-value=0}, provided-interface=SendCANR_MotorA_DC_CurrentVld
      SendCANR_MotorA_DC_Voltage: variation-point={short-label=vpSendCANR_MotorA_DC_Voltage, sw-syscond=1}, nonqueued-sender-com-spec{data-element=SendCANR_MotorA_DC_Voltage, init-value=0}, provided-interface=SendCANR_MotorA_DC_Voltage
      SendCANR_MotorA_DC_VoltageVld: variation-point={short-label=vpSendCANR_MotorA_DC_VoltageVld, sw-syscond=1}, nonqueued-sender-com-spec{data-element=SendCANR_MotorA_DC_VoltageVld, init-value=0}, provided-interface=SendCANR_MotorA_DC_VoltageVld
      SendCANR_MotorA_InverterState: variation-point={short-label=vpSendCANR_MotorA_InverterState, sw-syscond=1}, nonqueued-sender-com-spec{data-element=SendCANR_MotorA_InverterState, init-value=0}, provided-interface=SendCANR_MotorA_InverterState
      SendCANR_MotorA_InverterTemp: variation-point={short-label=vpSendCANR_MotorA_InverterTemp, sw-syscond=1}, nonqueued-sender-com-spec{data-element=SendCANR_MotorA_InverterTemp, init-value=0}, provided-interface=SendCANR_MotorA_InverterTemp
      SendCANR_MotorA_InverterTempVld: variation-point={short-label=vpSendCANR_MotorA_InverterTempVld, sw-syscond=1}, nonqueued-sender-com-spec{data-element=SendCANR_MotorA_InverterTempVld, init-value=0}, provided-interface=SendCANR_MotorA_InverterTempVld
      SendCANR_MotorA_RPM: variation-point={short-label=vpSendCANR_MotorA_RPM, sw-syscond=1}, nonqueued-sender-com-spec{data-element=SendCANR_MotorA_RPM, init-value=0}, provided-interface=SendCANR_MotorA_RPM
      SendCANR_MotorA_RPM_Vld: variation-point={short-label=vpSendCANR_MotorA_RPM_Vld, sw-syscond=1}, nonqueued-sender-com-spec{data-element=SendCANR_MotorA_RPM_Vld, init-value=0}, provided-interface=SendCANR_MotorA_RPM_Vld
      SendCANR_MotorA_Temperature: variation-point={short-label=vpSendCANR_MotorA_Temperature, sw-syscond=1}, nonqueued-sender-com-spec{data-element=SendCANR_MotorA_Temperature, init-value=0}, provided-interface=SendCANR_MotorA_Temperature
      SendCANR_MotorA_TemperatureVld: variation-point={short-label=vpSendCANR_MotorA_TemperatureVld, sw-syscond=1}, nonqueued-sender-com-spec{data-element=SendCANR_MotorA_TemperatureVld, init-value=0}, provided-interface=SendCANR_MotorA_TemperatureVld
      SendCANR_MotorA_TorqueAchieved: variation-point={short-label=vpSendCANR_MotorA_TorqueAchieved, sw-syscond=1}, nonqueued-sender-com-spec{data-element=SendCANR_MotorA_TorqueAchieved, init-value=0}, provided-interface=SendCANR_MotorA_TorqueAchieved
      SendCANR_MotorA_TorqueAchievedVld: variation-point={short-label=vpSendCANR_MotorA_TorqueAchievedVld, sw-syscond=1}, nonqueued-sender-com-spec{data-element=SendCANR_MotorA_TorqueAchievedVld, init-value=0}, provided-interface=SendCANR_MotorA_TorqueAchievedVld
      SendCANR_MotorB_DC_Current: nonqueued-sender-com-spec{data-element=SendCANR_MotorB_DC_Current, init-value=0}, provided-interface=SendCANR_MotorB_DC_Current
      SendCANR_MotorB_DC_CurrentVld: nonqueued-sender-com-spec{data-element=SendCANR_MotorB_DC_CurrentVld, init-value=0}, provided-interface=SendCANR_MotorB_DC_CurrentVld
      SendCANR_MotorB_DC_Voltage: nonqueued-sender-com-spec{data-element=SendCANR_MotorB_DC_Voltage, init-value=0}, provided-interface=SendCANR_MotorB_DC_Voltage
      SendCANR_MotorB_DC_VoltageVld: nonqueued-sender-com-spec{data-element=SendCANR_MotorB_DC_VoltageVld, init-value=0}, provided-interface=SendCANR_MotorB_DC_VoltageVld
      SendCANR_MotorB_InverterState: nonqueued-sender-com-spec{data-element=SendCANR_MotorB_InverterState, init-value=0}, provided-interface=SendCANR_MotorB_InverterState
      SendCANR_MotorB_InverterStateVld: nonqueued-sender-com-spec{data-element=SendCANR_MotorB_InverterStateVld, init-value=0}, provided-interface=SendCANR_MotorB_InverterStateVld
      SendCANR_MotorB_InverterTemp: nonqueued-sender-com-spec{data-element=SendCANR_MotorB_InverterTemp, init-value=0}, provided-interface=SendCANR_MotorB_InverterTemp
      SendCANR_MotorB_InverterTempVld: nonqueued-sender-com-spec{data-element=SendCANR_MotorB_InverterTempVld, init-value=0}, provided-interface=SendCANR_MotorB_InverterTempVld
      SendCANR_MotorB_RPM: nonqueued-sender-com-spec{data-element=SendCANR_MotorB_RPM, init-value=0}, provided-interface=SendCANR_MotorB_RPM
      SendCANR_MotorB_RPM_Vld: nonqueued-sender-com-spec{data-element=SendCANR_MotorB_RPM_Vld, init-value=0}, provided-interface=SendCANR_MotorB_RPM_Vld
      SendCANR_MotorB_Temperature: nonqueued-sender-com-spec{data-element=SendCANR_MotorB_Temperature, init-value=0}, provided-interface=SendCANR_MotorB_Temperature
      SendCANR_MotorB_TemperatureVld: nonqueued-sender-com-spec{data-element=SendCANR_MotorB_TemperatureVld, init-value=0}, provided-interface=SendCANR_MotorB_TemperatureVld
      SendCANR_MotorB_TorqueAchieved: nonqueued-sender-com-spec{data-element=SendCANR_MotorB_TorqueAchieved, init-value=0}, provided-interface=SendCANR_MotorB_TorqueAchieved
      SendCANR_MotorB_TorqueAchievedVld: nonqueued-sender-com-spec{data-element=SendCANR_MotorB_TorqueAchievedVld, init-value=0}, provided-interface=SendCANR_MotorB_TorqueAchievedVld
      SendCANR_AirflowRequest: nonqueued-sender-com-spec{data-element=SendCANR_AirflowRequest, init-value=0}, provided-interface=SendCANR_AirflowRequest
      SendCANR_AirflowRequestVld: nonqueued-sender-com-spec{data-element=SendCANR_AirflowRequestVld, init-value=0}, provided-interface=SendCANR_AirflowRequestVld
      SendCANR_RadiatorFanSts: nonqueued-sender-com-spec{data-element=SendCANR_RadiatorFanSts, init-value=0}, provided-interface=SendCANR_RadiatorFanSts
      SendCANR_RadiatorFanStsVld: nonqueued-sender-com-spec{data-element=SendCANR_RadiatorFanStsVld, init-value=0}, provided-interface=SendCANR_RadiatorFanStsVld
      SendCANR_Syst_Actual_Charge_Lim: variation-point={short-label=vpSendCANR_Syst_Actual_Charge_Lim, sw-syscond=1}, nonqueued-sender-com-spec{data-element=SendCANR_Syst_Actual_Charge_Lim, init-value=0}, provided-interface=SendCANR_Syst_Actual_Charge_Lim
      SendCANR_Syst_Actual_Charge_LimVld: variation-point={short-label=vpSendCANR_Syst_Actual_Charge_LimVld, sw-syscond=1}, nonqueued-sender-com-spec{data-element=SendCANR_Syst_Actual_Charge_LimVld, init-value=0}, provided-interface=SendCANR_Syst_Actual_Charge_LimVld
      SendCANR_Syst_Actual_Charge_Pwr: variation-point={short-label=vpSendCANR_Syst_Actual_Charge_Pwr, sw-syscond=1}, nonqueued-sender-com-spec{data-element=SendCANR_Syst_Actual_Charge_Pwr, init-value=0}, provided-interface=SendCANR_Syst_Actual_Charge_Pwr
      SendCANR_Syst_Actual_Charge_PwrVld: variation-point={short-label=vpSendCANR_Syst_Actual_Charge_PwrVld, sw-syscond=1}, nonqueued-sender-com-spec{data-element=SendCANR_Syst_Actual_Charge_PwrVld, init-value=0}, provided-interface=SendCANR_Syst_Actual_Charge_PwrVld
      SendCANR_MCPA_Temp_FD3: variation-point={short-label=vpSendCANR_MCPA_Temp_FD3, sw-syscond=1}, nonqueued-sender-com-spec{data-element=SendCANR_MCPA_Temp_FD3, init-value=0}, provided-interface=SendCANR_MCPA_Temp_FD3
      SendCANR_MCPA_Temp_FD3Vld: variation-point={short-label=vpSendCANR_MCPA_Temp_FD3Vld, sw-syscond=1}, nonqueued-sender-com-spec{data-element=SendCANR_MCPA_Temp_FD3Vld, init-value=0}, provided-interface=SendCANR_MCPA_Temp_FD3Vld
      SendCANR_V2H_Instant_Power_Draw: variation-point={short-label=vpSendCANR_V2H_Instant_Power_Draw, sw-syscond=1}, nonqueued-sender-com-spec{data-element=SendCANR_V2H_Instant_Power_Draw, init-value=0}, provided-interface=SendCANR_V2H_Instant_Power_Draw
      SendCANR_V2H_Instant_Power_DrawVld: variation-point={short-label=vpSendCANR_V2H_Instant_Power_DrawVld, sw-syscond=1}, nonqueued-sender-com-spec{data-element=SendCANR_V2H_Instant_Power_DrawVld, init-value=0}, provided-interface=SendCANR_V2H_Instant_Power_DrawVld
      SendCANR_V2H_Reserve_BatterySts: variation-point={short-label=vpSendCANR_V2H_Reserve_BatterySts, sw-syscond=1}, nonqueued-sender-com-spec{data-element=SendCANR_V2H_Reserve_BatterySts, init-value=0}, provided-interface=SendCANR_V2H_Reserve_BatterySts
      SendCANR_V2H_Reserve_BatteryStsVld: variation-point={short-label=vpSendCANR_V2H_Reserve_BatteryStsVld, sw-syscond=1}, nonqueued-sender-com-spec{data-element=SendCANR_V2H_Reserve_BatteryStsVld, init-value=0}, provided-interface=SendCANR_V2H_Reserve_BatteryStsVld
      SendCANR_V2H_Status: variation-point={short-label=vpSendCANR_V2H_Status, sw-syscond=1}, nonqueued-sender-com-spec{data-element=SendCANR_V2H_Status, init-value=0}, provided-interface=SendCANR_V2H_Status
      SendCANR_V2H_StatusVld: variation-point={short-label=vpSendCANR_V2H_StatusVld, sw-syscond=1}, nonqueued-sender-com-spec{data-element=SendCANR_V2H_StatusVld, init-value=0}, provided-interface=SendCANR_V2H_StatusVld
      SendCANR_V2H_TotalPowerTimedays: variation-point={short-label=vpSendCANR_V2H_TotalPowerTimedays, sw-syscond=1}, nonqueued-sender-com-spec{data-element=SendCANR_V2H_TotalPowerTimedays, init-value=0}, provided-interface=SendCANR_V2H_TotalPowerTimedays
      SendCANR_V2H_TotalPowerTimedaysVld: variation-point={short-label=vpSendCANR_V2H_TotalPowerTimedaysVld, sw-syscond=1}, nonqueued-sender-com-spec{data-element=SendCANR_V2H_TotalPowerTimedaysVld, init-value=0}, provided-interface=SendCANR_V2H_TotalPowerTimedaysVld
      SendCANR_V2HTotalPowerTimehours: variation-point={short-label=vpSendCANR_V2HTotalPowerTimehours, sw-syscond=1}, nonqueued-sender-com-spec{data-element=SendCANR_V2HTotalPowerTimehours, init-value=0}, provided-interface=SendCANR_V2HTotalPowerTimehours
      SendCANR_V2HTotalPowerTimehoursVld: variation-point={short-label=vpSendCANR_V2HTotalPowerTimehoursVld, sw-syscond=1}, nonqueued-sender-com-spec{data-element=SendCANR_V2HTotalPowerTimehoursVld, init-value=0}, provided-interface=SendCANR_V2HTotalPowerTimehoursVld
      SendCANR_V2HTotalPowerTimeminut: variation-point={short-label=vpSendCANR_V2HTotalPowerTimeminut, sw-syscond=1}, nonqueued-sender-com-spec{data-element=SendCANR_V2HTotalPowerTimeminut, init-value=0}, provided-interface=SendCANR_V2HTotalPowerTimeminut
      SendCANR_V2HTotalPowerTimeminutVld: variation-point={short-label=vpSendCANR_V2HTotalPowerTimeminutVld, sw-syscond=1}, nonqueued-sender-com-spec{data-element=SendCANR_V2HTotalPowerTimeminutVld, init-value=0}, provided-interface=SendCANR_V2HTotalPowerTimeminutVld
      SendCANR_V2H_mode_Sts: variation-point={short-label=vpSendCANR_V2H_mode_Sts, sw-syscond=1}, nonqueued-sender-com-spec{data-element=SendCANR_V2H_mode_Sts, init-value=0}, provided-interface=SendCANR_V2H_mode_Sts
      SendCANR_V2H_mode_StsVld: variation-point={short-label=vpSendCANR_V2H_mode_StsVld, sw-syscond=1}, nonqueued-sender-com-spec{data-element=SendCANR_V2H_mode_StsVld, init-value=0}, provided-interface=SendCANR_V2H_mode_StsVld
      SendCANR_V2L_Frunk_Status: nonqueued-sender-com-spec{data-element=SendCANR_V2L_Frunk_Status, init-value=0}, provided-interface=SendCANR_V2L_Frunk_Status
      SendCANR_V2L_Frunk_StatusVld: nonqueued-sender-com-spec{data-element=SendCANR_V2L_Frunk_StatusVld, init-value=0}, provided-interface=SendCANR_V2L_Frunk_StatusVld
      SendCANR_V2LInstantPwrDrawFrunk: nonqueued-sender-com-spec{data-element=SendCANR_V2LInstantPwrDrawFrunk, init-value=0}, provided-interface=SendCANR_V2LInstantPwrDrawFrunk
      SendCANR_V2LInstantPwrDrawFrunkVld: nonqueued-sender-com-spec{data-element=SendCANR_V2LInstantPwrDrawFrunkVld, init-value=0}, provided-interface=SendCANR_V2LInstantPwrDrawFrunkVld
      SendCANR_V2LInstantPwrDrawTrunk: nonqueued-sender-com-spec{data-element=SendCANR_V2LInstantPwrDrawTrunk, init-value=0}, provided-interface=SendCANR_V2LInstantPwrDrawTrunk
      SendCANR_V2LInstantPwrDrawTrunkVld: nonqueued-sender-com-spec{data-element=SendCANR_V2LInstantPwrDrawTrunkVld, init-value=0}, provided-interface=SendCANR_V2LInstantPwrDrawTrunkVld
      SendCANR_V2L_Total_PwrTimedays: nonqueued-sender-com-spec{data-element=SendCANR_V2L_Total_PwrTimedays, init-value=0}, provided-interface=SendCANR_V2L_Total_PwrTimedays
      SendCANR_V2L_Total_PwrTimedaysVld: nonqueued-sender-com-spec{data-element=SendCANR_V2L_Total_PwrTimedaysVld, init-value=0}, provided-interface=SendCANR_V2L_Total_PwrTimedaysVld
      SendCANR_V2LTotalPowerTimehours: nonqueued-sender-com-spec{data-element=SendCANR_V2LTotalPowerTimehours, init-value=0}, provided-interface=SendCANR_V2LTotalPowerTimehours
      SendCANR_V2LTotalPowerTimehoursVld: nonqueued-sender-com-spec{data-element=SendCANR_V2LTotalPowerTimehoursVld, init-value=0}, provided-interface=SendCANR_V2LTotalPowerTimehoursVld
      SendCANR_V2LTotalPowerTimeminut: nonqueued-sender-com-spec{data-element=SendCANR_V2LTotalPowerTimeminut, init-value=0}, provided-interface=SendCANR_V2LTotalPowerTimeminut
      SendCANR_V2LTotalPowerTimeminutVld: nonqueued-sender-com-spec{data-element=SendCANR_V2LTotalPowerTimeminutVld, init-value=0}, provided-interface=SendCANR_V2LTotalPowerTimeminutVld
      SendCANR_V2L_Trunk_Status: nonqueued-sender-com-spec{data-element=SendCANR_V2L_Trunk_Status, init-value=0}, provided-interface=SendCANR_V2L_Trunk_Status
      SendCANR_V2L_Trunk_StatusVld: nonqueued-sender-com-spec{data-element=SendCANR_V2L_Trunk_StatusVld, init-value=0}, provided-interface=SendCANR_V2L_Trunk_StatusVld
      SendCANR_V2V_Instant_Power_Draw: nonqueued-sender-com-spec{data-element=SendCANR_V2V_Instant_Power_Draw, init-value=0}, provided-interface=SendCANR_V2V_Instant_Power_Draw
      SendCANR_V2V_Instant_Power_DrawVld: nonqueued-sender-com-spec{data-element=SendCANR_V2V_Instant_Power_DrawVld, init-value=0}, provided-interface=SendCANR_V2V_Instant_Power_DrawVld
      SendCANR_V2V_Status: nonqueued-sender-com-spec{data-element=SendCANR_V2V_Status, init-value=0}, provided-interface=SendCANR_V2V_Status
      SendCANR_V2V_StatusVld: nonqueued-sender-com-spec{data-element=SendCANR_V2V_StatusVld, init-value=0}, provided-interface=SendCANR_V2V_StatusVld
      SendCANR_V2V_TotalPowerTimedays: nonqueued-sender-com-spec{data-element=SendCANR_V2V_TotalPowerTimedays, init-value=0}, provided-interface=SendCANR_V2V_TotalPowerTimedays
      SendCANR_V2V_TotalPowerTimedaysVld: nonqueued-sender-com-spec{data-element=SendCANR_V2V_TotalPowerTimedaysVld, init-value=0}, provided-interface=SendCANR_V2V_TotalPowerTimedaysVld
      SendCANR_V2VTotalPowerTimehours: nonqueued-sender-com-spec{data-element=SendCANR_V2VTotalPowerTimehours, init-value=0}, provided-interface=SendCANR_V2VTotalPowerTimehours
      SendCANR_V2VTotalPowerTimehoursVld: nonqueued-sender-com-spec{data-element=SendCANR_V2VTotalPowerTimehoursVld, init-value=0}, provided-interface=SendCANR_V2VTotalPowerTimehoursVld
      SendCANR_V2VTotalPowerTimeminut: nonqueued-sender-com-spec{data-element=SendCANR_V2VTotalPowerTimeminut, init-value=0}, provided-interface=SendCANR_V2VTotalPowerTimeminut
      SendCANR_V2VTotalPowerTimeminutVld: nonqueued-sender-com-spec{data-element=SendCANR_V2VTotalPowerTimeminutVld, init-value=0}, provided-interface=SendCANR_V2VTotalPowerTimeminutVld
      SendCANR_P2P_Timer: nonqueued-sender-com-spec{data-element=SendCANR_P2P_Timer, init-value=0}, provided-interface=SendCANR_P2P_Timer
      SendCANR_P2P_TimerVld: nonqueued-sender-com-spec{data-element=SendCANR_P2P_TimerVld, init-value=0}, provided-interface=SendCANR_P2P_TimerVld
      SendCANR_PwrSht_Prep_Prt_Cmplt: nonqueued-sender-com-spec{data-element=SendCANR_PwrSht_Prep_Prt_Cmplt, init-value=0}, provided-interface=SendCANR_PwrSht_Prep_Prt_Cmplt
      SendCANR_PwrSht_Prep_Prt_CmpltVld: nonqueued-sender-com-spec{data-element=SendCANR_PwrSht_Prep_Prt_CmpltVld, init-value=0}, provided-interface=SendCANR_PwrSht_Prep_Prt_CmpltVld
      SendCANR_Turtle_Speed_Limit: nonqueued-sender-com-spec{data-element=SendCANR_Turtle_Speed_Limit, init-value=0}, provided-interface=SendCANR_Turtle_Speed_Limit
      SendCANR_Turtle_Speed_LimitVld: nonqueued-sender-com-spec{data-element=SendCANR_Turtle_Speed_LimitVld, init-value=0}, provided-interface=SendCANR_Turtle_Speed_LimitVld
      SendCANR_T4_Sensor_Temp_FD3: nonqueued-sender-com-spec{data-element=SendCANR_T4_Sensor_Temp_FD3, init-value=0}, provided-interface=SendCANR_T4_Sensor_Temp_FD3
      SendCANR_T4_Sensor_Temp_FD3Vld: nonqueued-sender-com-spec{data-element=SendCANR_T4_Sensor_Temp_FD3Vld, init-value=0}, provided-interface=SendCANR_T4_Sensor_Temp_FD3Vld
    behavior IB_CT1B_FUNC: data-type-mapping=[msADTtoIDTMapping, ADTtoIDTMapping], handle-termination-and-restart=NO-SUPPORT
      timing event Event_FastTEF: start-on-event=CT1B_FUNC_FastTEF, period=0.005
      init event Event_CT1B_FUNC_ac_Init: start-on-event=CT1B_FUNC_ac_Init
      runnable CT1B_FUNC_ac_Init
      runnable CT1B_FUNC_FastTEF
        data-receive-point-by-arguments:
          160 x access:
            IN_VeASLR_v_TurtleMdSpdLim_Value: accessed-variable=VeASLR_v_TurtleMdSpdLim.Value
            IN_VeEBMR_Pct_PwrSht_Prep_Value: accessed-variable=VeEBMR_Pct_PwrSht_Prep.Value
            IN_VeEBMR_t_PrepCntDwn_Value: accessed-variable=VeEBMR_t_PrepCntDwn.Value
            IN_VeERER_b_ACFanRange_SNA_Value: accessed-variable=VeERER_b_ACFanRange_SNA.Value, variation-point={short-label=vpIN_VeERER_b_ACFanRange_SNA_Value, sw-syscond=1}
            IN_VeERER_b_AudioRange_SNA_Value: accessed-variable=VeERER_b_AudioRange_SNA.Value, variation-point={short-label=vpIN_VeERER_b_AudioRange_SNA_Value, sw-syscond=1}
            IN_VeERER_b_DefrostRange_SNA_Value: accessed-variable=VeERER_b_DefrostRange_SNA.Value, variation-point={short-label=vpIN_VeERER_b_DefrostRange_SNA_Value, sw-syscond=1}
            IN_VeERER_b_LightsRange_SNA_Value: accessed-variable=VeERER_b_LightsRange_SNA.Value, variation-point={short-label=vpIN_VeERER_b_LightsRange_SNA_Value, sw-syscond=1}
            IN_VeERER_b_OtherRange_SNA_Value: accessed-variable=VeERER_b_OtherRange_SNA.Value, variation-point={short-label=vpIN_VeERER_b_OtherRange_SNA_Value, sw-syscond=1}
            IN_VeERER_b_SeatswhlRange_SNA_Value: accessed-variable=VeERER_b_SeatswhlRange_SNA.Value, variation-point={short-label=vpIN_VeERER_b_SeatswhlRange_SNA_Value, sw-syscond=1}
            IN_VeERER_b_TotalRange_SNA_Value: accessed-variable=VeERER_b_TotalRange_SNA.Value, variation-point={short-label=vpIN_VeERER_b_TotalRange_SNA_Value, sw-syscond=1}
            IN_VeERER_l_AC_Fan_Range_Value: accessed-variable=VeERER_l_AC_Fan_Range.Value, variation-point={short-label=vpIN_VeERER_l_AC_Fan_Range_Value, sw-syscond=1}
            IN_VeERER_l_Audio_Range_Value: accessed-variable=VeERER_l_Audio_Range.Value, variation-point={short-label=vpIN_VeERER_l_Audio_Range_Value, sw-syscond=1}
            IN_VeERER_l_Defrost_Range_Value: accessed-variable=VeERER_l_Defrost_Range.Value, variation-point={short-label=vpIN_VeERER_l_Defrost_Range_Value, sw-syscond=1}
            IN_VeERER_l_Lights_Range_Value: accessed-variable=VeERER_l_Lights_Range.Value, variation-point={short-label=vpIN_VeERER_l_Lights_Range_Value, sw-syscond=1}
            IN_VeERER_l_Other_Range_Value: accessed-variable=VeERER_l_Other_Range.Value, variation-point={short-label=vpIN_VeERER_l_Other_Range_Value, sw-syscond=1}
            IN_VeERER_l_Seatswhl_Range_Value: accessed-variable=VeERER_l_Seatswhl_Range.Value, variation-point={short-label=vpIN_VeERER_l_Seatswhl_Range_Value, sw-syscond=1}
            IN_VeERER_l_Total_Range_Value: accessed-variable=VeERER_l_Total_Range.Value, variation-point={short-label=vpIN_VeERER_l_Total_Range_Value, sw-syscond=1}
            IN_VeHTIR_T_Htr2CoreTemp_Value: accessed-variable=VeHTIR_T_Htr2CoreTemp.Value
            IN_VeHTIR_T_Htr2_PCBTemp_Value: accessed-variable=VeHTIR_T_Htr2_PCBTemp.Value
            IN_VeHTRR_P_HVC_HtrPwrAct_Value: accessed-variable=VeHTRR_P_HVC_HtrPwrAct.Value
            IN_VeHTRR_Pct_HV_Htr2PwrAct_Value: accessed-variable=VeHTRR_Pct_HV_Htr2PwrAct.Value
            IN_VeINVR_I_MtrA_DC_Crnt_Value: accessed-variable=VeINVR_I_MtrA_DC_Crnt.Value, variation-point={short-label=vpIN_VeINVR_I_MtrA_DC_Crnt_Value, sw-syscond=1}
            IN_VeINVR_I_MtrB_DC_Crnt_Value: accessed-variable=VeINVR_I_MtrB_DC_Crnt.Value
            IN_VeINVR_T_MtrA_InvrtrTemp_Value: accessed-variable=VeINVR_T_MtrA_InvrtrTemp.Value, variation-point={short-label=vpIN_VeINVR_T_MtrA_InvrtrTemp_Value, sw-syscond=1}
            IN_VeINVR_T_MtrA_Temp_Value: accessed-variable=VeINVR_T_MtrA_Temp.Value, variation-point={short-label=vpIN_VeINVR_T_MtrA_Temp_Value, sw-syscond=1}
            IN_VeINVR_T_MtrB_InvrtrTemp_Value: accessed-variable=VeINVR_T_MtrB_InvrtrTemp.Value
            IN_VeINVR_T_MtrB_Temp_Value: accessed-variable=VeINVR_T_MtrB_Temp.Value
            IN_VeINVR_U_MtrA_DC_Volt_Value: accessed-variable=VeINVR_U_MtrA_DC_Volt.Value, variation-point={short-label=vpIN_VeINVR_U_MtrA_DC_Volt_Value, sw-syscond=1}
            IN_VeINVR_U_MtrB_DC_Volt_Value: accessed-variable=VeINVR_U_MtrB_DC_Volt.Value
            IN_VeINVR_b_MtrA_DC_CrntFA_Value: accessed-variable=VeINVR_b_MtrA_DC_CrntFA.Value, variation-point={short-label=vpIN_VeINVR_b_MtrA_DC_CrntFA_Value, sw-syscond=1}
            IN_VeINVR_b_MtrA_DC_VoltFA_Value: accessed-variable=VeINVR_b_MtrA_DC_VoltFA.Value, variation-point={short-label=vpIN_VeINVR_b_MtrA_DC_VoltFA_Value, sw-syscond=1}
            IN_VeINVR_b_MtrA_InvrtrTempFA_Value: accessed-variable=VeINVR_b_MtrA_InvrtrTempFA.Value, variation-point={short-label=vpIN_VeINVR_b_MtrA_InvrtrTempFA_Value, sw-syscond=1}
            IN_VeINVR_b_MtrA_TempFA_Value: accessed-variable=VeINVR_b_MtrA_TempFA.Value, variation-point={short-label=vpIN_VeINVR_b_MtrA_TempFA_Value, sw-syscond=1}
            IN_VeINVR_b_MtrB_DC_CrntFA_Value: accessed-variable=VeINVR_b_MtrB_DC_CrntFA.Value
            IN_VeINVR_b_MtrB_DC_VoltFA_Value: accessed-variable=VeINVR_b_MtrB_DC_VoltFA.Value
            IN_VeINVR_b_MtrB_InvrtrTempFA_Value: accessed-variable=VeINVR_b_MtrB_InvrtrTempFA.Value
            IN_VeINVR_b_MtrB_TempFA_Value: accessed-variable=VeINVR_b_MtrB_TempFA.Value
            IN_VeINVR_e_MtrA_InvrtrSt_Value: accessed-variable=VeINVR_e_MtrA_InvrtrSt.Value, variation-point={short-label=vpIN_VeINVR_e_MtrA_InvrtrSt_Value, sw-syscond=1}
            IN_VeINVR_e_MtrB_InvrtrSt_Value: accessed-variable=VeINVR_e_MtrB_InvrtrSt.Value
            IN_VeMSPR_b_MtrA_SpdFA_Value: accessed-variable=VeMSPR_b_MtrA_SpdFA.Value, variation-point={short-label=vpIN_VeMSPR_b_MtrA_SpdFA_Value, sw-syscond=1}
            IN_VeMSPR_b_MtrB_SpdFA_Value: accessed-variable=VeMSPR_b_MtrB_SpdFA.Value
            IN_VeMSPR_n_MtrA_Spd_Value: accessed-variable=VeMSPR_n_MtrA_Spd.Value, variation-point={short-label=vpIN_VeMSPR_n_MtrA_Spd_Value, sw-syscond=1}
            IN_VeMSPR_n_MtrB_Spd_Value: accessed-variable=VeMSPR_n_MtrB_Spd.Value
            IN_VeMTIR_M_MtrA_TorqAchieved_Value: accessed-variable=VeMTIR_M_MtrA_TorqAchieved.Value, variation-point={short-label=vpIN_VeMTIR_M_MtrA_TorqAchieved_Value, sw-syscond=1}
            IN_VeMTIR_M_MtrB_TorqAchieved_Value: accessed-variable=VeMTIR_M_MtrB_TorqAchieved.Value
            IN_VeMTIR_b_MtrA_TorqAchievedFA_Value: accessed-variable=VeMTIR_b_MtrA_TorqAchievedFA.Value, variation-point={short-label=vpIN_VeMTIR_b_MtrA_TorqAchievedFA_Value, sw-syscond=1}
            IN_VeMTIR_b_MtrB_TorqAchievedFA_Value: accessed-variable=VeMTIR_b_MtrB_TorqAchievedFA.Value
            IN_VeOBCR_I_ChrgCrntReqDelta_Value: accessed-variable=VeOBCR_I_ChrgCrntReqDelta.Value, variation-point={short-label=vpIN_VeOBCR_I_ChrgCrntReqDelta_Value, sw-syscond=1}
            IN_VeOBCR_P_ActChargePower_Value: accessed-variable=VeOBCR_P_ActChargePower.Value, variation-point={short-label=vpIN_VeOBCR_P_ActChargePower_Value, sw-syscond=1}
            IN_VeOBCR_P_ActChargePowerLim_Value: accessed-variable=VeOBCR_P_ActChargePowerLim.Value, variation-point={short-label=vpIN_VeOBCR_P_ActChargePowerLim_Value, sw-syscond=1}
            IN_VeOBCR_P_EVSEPwr_Value: accessed-variable=VeOBCR_P_EVSEPwr.Value, variation-point={short-label=vpIN_VeOBCR_P_EVSEPwr_Value, sw-syscond=1}
            IN_VeOBCR_P_PowertoBattery_Value: accessed-variable=VeOBCR_P_PowertoBattery.Value, variation-point={short-label=vpIN_VeOBCR_P_PowertoBattery_Value, sw-syscond=1}
            IN_VeOBCR_b_ActChargePowerFA_Value: accessed-variable=VeOBCR_b_ActChargePowerFA.Value, variation-point={short-label=vpIN_VeOBCR_b_ActChargePowerFA_Value, sw-syscond=1}
            IN_VeOBCR_b_ActChargePowerLimFA_Value: accessed-variable=VeOBCR_b_ActChargePowerLimFA.Value, variation-point={short-label=vpIN_VeOBCR_b_ActChargePowerLimFA_Value, sw-syscond=1}
            IN_VeOBCR_b_PnCFailure_Value: accessed-variable=VeOBCR_b_PnCFailure.Value
            IN_VeOBCR_b_PnCRetryFail_Value: accessed-variable=VeOBCR_b_PnCRetryFail.Value
            IN_VeOBCR_b_RacePrepBattLvlSts_Value: accessed-variable=VeOBCR_b_RacePrepBattLvlSts.Value, variation-point={short-label=vpIN_VeOBCR_b_RacePrepBattLvlSts_Value, sw-syscond=1}
            IN_VeOBCR_e_ChargeportLock_Sts_Value: accessed-variable=VeOBCR_e_ChargeportLock_Sts.Value
            IN_VeOBCR_q_BatteryAmpHrCap_Value: accessed-variable=VeOBCR_q_BatteryAmpHrCap.Value, variation-point={short-label=vpIN_VeOBCR_q_BatteryAmpHrCap_Value, sw-syscond=1}
            IN_VePMIR_b_HTAuxPumpMntrRPM_FA_Value: accessed-variable=VePMIR_b_HTAuxPumpMntrRPM_FA.Value
            IN_VePMIR_b_HTAuxPumpRPMAct_FA_Value: accessed-variable=VePMIR_b_HTAuxPumpRPMAct_FA.Value
            IN_VePMIR_e_HTAuxPumpMntrRPM_Value: accessed-variable=VePMIR_e_HTAuxPumpMntrRPM.Value
            IN_VePMIR_n_HTAuxPumpRPMAct_Value: accessed-variable=VePMIR_n_HTAuxPumpRPMAct.Value
            IN_VeRCVR_b_FtRfgtShtoff_VlvSts_Value: accessed-variable=VeRCVR_b_FtRfgtShtoff_VlvSts.Value
            IN_VeRCVR_b_HT_Shtoff_VlvCmd_Value: accessed-variable=VeRCVR_b_HT_Shtoff_VlvCmd.Value
            IN_VeSCPR_K_Ext_Next_StopTime_Day_Value: accessed-variable=VeSCPR_K_Ext_Next_StopTime_Day.Value
            IN_VeSCPR_K_Ext_Next_StopTime_Hr_Value: accessed-variable=VeSCPR_K_Ext_Next_StopTime_Hr.Value
            IN_VeSCPR_K_Ext_Next_StopTime_Min_Value: accessed-variable=VeSCPR_K_Ext_Next_StopTime_Min.Value
            IN_VeSCPR_K_Next_Climate_Day_Value: accessed-variable=VeSCPR_K_Next_Climate_Day.Value
            IN_VeSCPR_K_Next_Climate_Time_Hr_Value: accessed-variable=VeSCPR_K_Next_Climate_Time_Hr.Value
            IN_VeSCPR_K_Next_Climate_Time_Min_Value: accessed-variable=VeSCPR_K_Next_Climate_Time_Min.Value
            IN_VeSCPR_K_Next_SchEnd_Time_Hr_Value: accessed-variable=VeSCPR_K_Next_SchEnd_Time_Hr.Value
            IN_VeSCPR_K_Next_SchEnd_Time_Min_Value: accessed-variable=VeSCPR_K_Next_SchEnd_Time_Min.Value
            IN_VeSCPR_K_Next_SchStart_Time_Hr_Value: accessed-variable=VeSCPR_K_Next_SchStart_Time_Hr.Value
            IN_VeSCPR_K_Next_SchStart_Time_Min_Value: accessed-variable=VeSCPR_K_Next_SchStart_Time_Min.Value
            IN_VeSCPR_K_Next_Schedule_EndDay_Value: accessed-variable=VeSCPR_K_Next_Schedule_EndDay.Value
            IN_VeSCPR_K_Next_Schedule_StartDay_Value: accessed-variable=VeSCPR_K_Next_Schedule_StartDay.Value
            IN_VeSCPR_K_Sch1_Day_Sts_Value: accessed-variable=VeSCPR_K_Sch1_Day_Sts.Value
            IN_VeSCPR_K_Sch1_End_Time_Hr_Sts_Value: accessed-variable=VeSCPR_K_Sch1_End_Time_Hr_Sts.Value
            IN_VeSCPR_K_Sch1_End_Time_Min_Sts_Value: accessed-variable=VeSCPR_K_Sch1_End_Time_Min_Sts.Value
            IN_VeSCPR_K_Sch1_Start_Time_Hr_Sts_Value: accessed-variable=VeSCPR_K_Sch1_Start_Time_Hr_Sts.Value
            IN_VeSCPR_K_Sch1_Start_Time_Min_Sts_Value: accessed-variable=VeSCPR_K_Sch1_Start_Time_Min_Sts.Value
            IN_VeSCPR_K_Sch2_Day_Sts_Value: accessed-variable=VeSCPR_K_Sch2_Day_Sts.Value
            IN_VeSCPR_K_Sch2_End_Time_Hr_Sts_Value: accessed-variable=VeSCPR_K_Sch2_End_Time_Hr_Sts.Value
            IN_VeSCPR_K_Sch2_End_Time_Min_Sts_Value: accessed-variable=VeSCPR_K_Sch2_End_Time_Min_Sts.Value
            IN_VeSCPR_K_Sch2_Start_Time_Hr_Sts_Value: accessed-variable=VeSCPR_K_Sch2_Start_Time_Hr_Sts.Value
            IN_VeSCPR_K_Sch2_Start_Time_Min_Sts_Value: accessed-variable=VeSCPR_K_Sch2_Start_Time_Min_Sts.Value
            IN_VeSCPR_K_Sch3_DaySts_Value: accessed-variable=VeSCPR_K_Sch3_DaySts.Value
            IN_VeSCPR_K_Sch3_DepHrSts_Value: accessed-variable=VeSCPR_K_Sch3_DepHrSts.Value
            IN_VeSCPR_K_Sch3_DepMinSts_Value: accessed-variable=VeSCPR_K_Sch3_DepMinSts.Value
            IN_VeSCPR_K_Sch4_DaySts_Value: accessed-variable=VeSCPR_K_Sch4_DaySts.Value
            IN_VeSCPR_K_Sch4_DepHrSts_Value: accessed-variable=VeSCPR_K_Sch4_DepHrSts.Value
            IN_VeSCPR_K_Sch4_DepMinSts_Value: accessed-variable=VeSCPR_K_Sch4_DepMinSts.Value
            IN_VeSCPR_Pct_Ext_Next_ExtSOC_Trgt_Value: accessed-variable=VeSCPR_Pct_Ext_Next_ExtSOC_Trgt.Value
            IN_VeSCPR_Pct_Ext_Next_ImmedSOC_Trgt_Value: accessed-variable=VeSCPR_Pct_Ext_Next_ImmedSOC_Trgt.Value
            IN_VeSCPR_Pct_Sch1_ExtSOC_Trgt_Sts_Value: accessed-variable=VeSCPR_Pct_Sch1_ExtSOC_Trgt_Sts.Value
            IN_VeSCPR_Pct_Sch1_ImmedSOC_Trgt_Sts_Value: accessed-variable=VeSCPR_Pct_Sch1_ImmedSOC_Trgt_Sts.Value
            IN_VeSCPR_Pct_Sch2_ExtSOC_Trgt_Sts_Value: accessed-variable=VeSCPR_Pct_Sch2_ExtSOC_Trgt_Sts.Value
            IN_VeSCPR_Pct_Sch2_ImmedSOC_Trgt_Sts_Value: accessed-variable=VeSCPR_Pct_Sch2_ImmedSOC_Trgt_Sts.Value
            IN_VeSCPR_T_CabinTempSetPt_Value: accessed-variable=VeSCPR_T_CabinTempSetPt.Value
            IN_VeSCPR_T_Sch3_DepTempSts_Value: accessed-variable=VeSCPR_T_Sch3_DepTempSts.Value
            IN_VeSCPR_T_Sch4_DepTempSts_Value: accessed-variable=VeSCPR_T_Sch4_DepTempSts.Value
            IN_VeSCPR_b_Sch1_ChargeUntilFull_Sts_Value: accessed-variable=VeSCPR_b_Sch1_ChargeUntilFull_Sts.Value
            IN_VeSCPR_b_Sch1_Confirmed_Value: accessed-variable=VeSCPR_b_Sch1_Confirmed.Value
            IN_VeSCPR_b_Sch2_ChargeUntilFull_Sts_Value: accessed-variable=VeSCPR_b_Sch2_ChargeUntilFull_Sts.Value
            IN_VeSCPR_b_Sch2_Confirmed_Value: accessed-variable=VeSCPR_b_Sch2_Confirmed.Value
            IN_VeSCPR_b_Sch3_EnblSts_Value: accessed-variable=VeSCPR_b_Sch3_EnblSts.Value
            IN_VeSCPR_b_Sch4_EnblSts_Value: accessed-variable=VeSCPR_b_Sch4_EnblSts.Value
            IN_VeSCPR_e_CoopChrgStatus_Value: accessed-variable=VeSCPR_e_CoopChrgStatus.Value
            IN_VeSCPR_e_Next_ChrgSchType_Value: accessed-variable=VeSCPR_e_Next_ChrgSchType.Value
            IN_VeSCPR_e_Sch1_ChrgSchType_Sts_Value: accessed-variable=VeSCPR_e_Sch1_ChrgSchType_Sts.Value
            IN_VeSCPR_e_Sch2_ChrgSchType_Sts_Value: accessed-variable=VeSCPR_e_Sch2_ChrgSchType_Sts.Value
            IN_VeSCPR_e_Sch3_AllowSts_Value: accessed-variable=VeSCPR_e_Sch3_AllowSts.Value
            IN_VeSCPR_e_Sch4_AllowSts_Value: accessed-variable=VeSCPR_e_Sch4_AllowSts.Value
            IN_VeTAIR_Pct_RadFanSts_Value: accessed-variable=VeTAIR_Pct_RadFanSts.Value
            IN_VeTAIR_b_RadFanSts_FA_Value: accessed-variable=VeTAIR_b_RadFanSts_FA.Value
            IN_VeTAIR_e_CompStat_Value: accessed-variable=VeTAIR_e_CompStat.Value
            IN_VeTHMR_Pct_AirFlowReq_Value: accessed-variable=VeTHMR_Pct_AirFlowReq.Value
            IN_VeTHMR_b_HV_BatTempCrit_Cond_Value: accessed-variable=VeTHMR_b_HV_BatTempCrit_Cond.Value
            IN_VeTHMR_e_CabinPreCondReqMsg_Value: accessed-variable=VeTHMR_e_CabinPreCondReqMsg.Value
            IN_VeTHMR_e_CabinPreCondReqStat_Value: accessed-variable=VeTHMR_e_CabinPreCondReqStat.Value
            IN_VeTHMR_e_HV_Bat_CltLvlLo_Value: accessed-variable=VeTHMR_e_HV_Bat_CltLvlLo.Value
            IN_VeTHMR_e_SC_WkUp_Value: accessed-variable=VeTHMR_e_SC_WkUp.Value
            IN_VeTIMR_e_LaunchMdSwtchLED_Value: accessed-variable=VeTIMR_e_LaunchMdSwtchLED.Value, variation-point={short-label=vpIN_VeTIMR_e_LaunchMdSwtchLED_Value, sw-syscond=1}
            IN_VeTIMR_e_RaceMdPopUp_Value: accessed-variable=VeTIMR_e_RaceMdPopUp.Value
            IN_VeTIMR_e_RacePrepRaceTypeSts_Value: accessed-variable=VeTIMR_e_RacePrepRaceTypeSts.Value, variation-point={short-label=vpIN_VeTIMR_e_RacePrepRaceTypeSts_Value, sw-syscond=1}
            IN_VeTMIR_T_ElecClntHtr_TmpIn_Value: accessed-variable=VeTMIR_T_ElecClntHtr_TmpIn.Value
            IN_VeTMIR_T_OnBrdChrg_ClntTmpIn_Value: accessed-variable=VeTMIR_T_OnBrdChrg_ClntTmpIn.Value
            IN_VeTMIR_b_ElecClntHtr_TmpIn_FA_Value: accessed-variable=VeTMIR_b_ElecClntHtr_TmpIn_FA.Value
            IN_VeTMIR_b_OnBrdChrg_ClntTmpIn_FA_Value: accessed-variable=VeTMIR_b_OnBrdChrg_ClntTmpIn_FA.Value
            IN_VeTPCR_T_RacePrep_SOCTrgt_Value: accessed-variable=VeTPCR_T_RacePrep_SOCTrgt.Value, variation-point={short-label=vpIN_VeTPCR_T_RacePrep_SOCTrgt_Value, sw-syscond=1}
            IN_VeTPCR_T_RacePrep_ThrmlTrgt_Value: accessed-variable=VeTPCR_T_RacePrep_ThrmlTrgt.Value, variation-point={short-label=vpIN_VeTPCR_T_RacePrep_ThrmlTrgt_Value, sw-syscond=1}
            IN_VeTPCR_b_RacePrepAmbCheck_Value: accessed-variable=VeTPCR_b_RacePrepAmbCheck.Value, variation-point={short-label=vpIN_VeTPCR_b_RacePrepAmbCheck_Value, sw-syscond=1}
            IN_VeTPCR_b_RacePrepEVSysStatus_Value: accessed-variable=VeTPCR_b_RacePrepEVSysStatus.Value, variation-point={short-label=vpIN_VeTPCR_b_RacePrepEVSysStatus_Value, sw-syscond=1}
            IN_VeTPCR_t_RacePrep_DeacTime_Value: accessed-variable=VeTPCR_t_RacePrep_DeacTime.Value, variation-point={short-label=vpIN_VeTPCR_t_RacePrep_DeacTime_Value, sw-syscond=1}
            IN_VeTPCR_t_TimeToDeparture_Value: accessed-variable=VeTPCR_t_TimeToDeparture.Value
            IN_VeTRIR_T_HtrCorClnt_TmpIn_Value: accessed-variable=VeTRIR_T_HtrCorClnt_TmpIn.Value
            IN_VeTRIR_b_HtrCorClnt_TmpIn_FA_Value: accessed-variable=VeTRIR_b_HtrCorClnt_TmpIn_FA.Value
            IN_VeVDVR_P_V2V_InstPwrDraw_Value: accessed-variable=VeVDVR_P_V2V_InstPwrDraw.Value
            IN_VeVDVR_e_V2V_Status_Value: accessed-variable=VeVDVR_e_V2V_Status.Value
            IN_VeVDVR_t_V2V_TotalPwrTimeDay_Value: accessed-variable=VeVDVR_t_V2V_TotalPwrTimeDay.Value
            IN_VeVDVR_t_V2V_TotalPwrTimeHs_Value: accessed-variable=VeVDVR_t_V2V_TotalPwrTimeHs.Value
            IN_VeVDVR_t_V2V_TotalPwrTimeMin_Value: accessed-variable=VeVDVR_t_V2V_TotalPwrTimeMin.Value
            IN_VeVTHR_P_V2H_DschgCap_Value: accessed-variable=VeVTHR_P_V2H_DschgCap.Value, variation-point={short-label=vpIN_VeVTHR_P_V2H_DschgCap_Value, sw-syscond=1}
            IN_VeVTHR_P_V2H_InstPwrDraw_Value: accessed-variable=VeVTHR_P_V2H_InstPwrDraw.Value, variation-point={short-label=vpIN_VeVTHR_P_V2H_InstPwrDraw_Value, sw-syscond=1}
            IN_VeVTHR_Pct_V2H_ResrvBattSts_Value: accessed-variable=VeVTHR_Pct_V2H_ResrvBattSts.Value, variation-point={short-label=vpIN_VeVTHR_Pct_V2H_ResrvBattSts_Value, sw-syscond=1}
            IN_VeVTHR_b_V2H_MdSts_Value: accessed-variable=VeVTHR_b_V2H_MdSts.Value, variation-point={short-label=vpIN_VeVTHR_b_V2H_MdSts_Value, sw-syscond=1}
            IN_VeVTHR_e_FOTA_ReadySts_Value: accessed-variable=VeVTHR_e_FOTA_ReadySts.Value, variation-point={short-label=vpIN_VeVTHR_e_FOTA_ReadySts_Value, sw-syscond=1}
            IN_VeVTHR_e_V2H_Sts_Value: accessed-variable=VeVTHR_e_V2H_Sts.Value, variation-point={short-label=vpIN_VeVTHR_e_V2H_Sts_Value, sw-syscond=1}
            IN_VeVTHR_t_V2H_TotPwrDays_Value: accessed-variable=VeVTHR_t_V2H_TotPwrDays.Value, variation-point={short-label=vpIN_VeVTHR_t_V2H_TotPwrDays_Value, sw-syscond=1}
            IN_VeVTHR_t_V2H_TotPwrHrs_Value: accessed-variable=VeVTHR_t_V2H_TotPwrHrs.Value, variation-point={short-label=vpIN_VeVTHR_t_V2H_TotPwrHrs_Value, sw-syscond=1}
            IN_VeVTHR_t_V2H_TotPwrMin_Value: accessed-variable=VeVTHR_t_V2H_TotPwrMin.Value, variation-point={short-label=vpIN_VeVTHR_t_V2H_TotPwrMin_Value, sw-syscond=1}
            IN_VeVTLR_P_InstantPwr_IDCM_Value: accessed-variable=VeVTLR_P_InstantPwr_IDCM.Value
            IN_VeVTLR_P_InstantPwr_PPIM_Value: accessed-variable=VeVTLR_P_InstantPwr_PPIM.Value
            IN_VeVTLR_e_DschrgSysSts_Value: accessed-variable=VeVTLR_e_DschrgSysSts.Value
            IN_VeVTLR_e_FrunkSts_Value: accessed-variable=VeVTLR_e_FrunkSts.Value
            IN_VeVTLR_e_TrunkSts_Value: accessed-variable=VeVTLR_e_TrunkSts.Value
            IN_VeVTLR_t_DschrgDays_Value: accessed-variable=VeVTLR_t_DschrgDays.Value
            IN_VeVTLR_t_DschrgHrs_Value: accessed-variable=VeVTLR_t_DschrgHrs.Value
            IN_VeVTLR_t_DschrgMins_Value: accessed-variable=VeVTLR_t_DschrgMins.Value
        data-send-points:
          267 x access:
            OUT_SendCANR_ChargeUntilFull1_Sts_SendCANR_ChargeUntilFull1_Sts: accessed-variable=SendCANR_ChargeUntilFull1_Sts.SendCANR_ChargeUntilFull1_Sts
            OUT_SendCANR_ChargeUntilFull1_StsVld_SendCANR_ChargeUntilFull1_StsVld: accessed-variable=SendCANR_ChargeUntilFull1_StsVld.SendCANR_ChargeUntilFull1_StsVld
            OUT_SendCANR_ChargeUntilFull2_Sts_SendCANR_ChargeUntilFull2_Sts: accessed-variable=SendCANR_ChargeUntilFull2_Sts.SendCANR_ChargeUntilFull2_Sts
            OUT_SendCANR_ChargeUntilFull2_StsVld_SendCANR_ChargeUntilFull2_StsVld: accessed-variable=SendCANR_ChargeUntilFull2_StsVld.SendCANR_ChargeUntilFull2_StsVld
            OUT_SendCANR_Chrg_Schedule_Type1Sts_SendCANR_Chrg_Schedule_Type1Sts: accessed-variable=SendCANR_Chrg_Schedule_Type1Sts.SendCANR_Chrg_Schedule_Type1Sts
            OUT_SendCANR_Chrg_Schedule_Type1StsVld_SendCANR_Chrg_Schedule_Type1StsVld: accessed-variable=SendCANR_Chrg_Schedule_Type1StsVld.SendCANR_Chrg_Schedule_Type1StsVld
            OUT_SendCANR_ChargeScheduleType2Sts_SendCANR_ChargeScheduleType2Sts: accessed-variable=SendCANR_ChargeScheduleType2Sts.SendCANR_ChargeScheduleType2Sts
            OUT_SendCANR_ChargeScheduleType2StsVld_SendCANR_ChargeScheduleType2StsVld: accessed-variable=SendCANR_ChargeScheduleType2StsVld.SendCANR_ChargeScheduleType2StsVld
            OUT_SendCANR_End_Time_Hr1_Sts_SendCANR_End_Time_Hr1_Sts: accessed-variable=SendCANR_End_Time_Hr1_Sts.SendCANR_End_Time_Hr1_Sts
            OUT_SendCANR_End_Time_Hr1_StsVld_SendCANR_End_Time_Hr1_StsVld: accessed-variable=SendCANR_End_Time_Hr1_StsVld.SendCANR_End_Time_Hr1_StsVld
            OUT_SendCANR_End_Time_Hr2_Sts_SendCANR_End_Time_Hr2_Sts: accessed-variable=SendCANR_End_Time_Hr2_Sts.SendCANR_End_Time_Hr2_Sts
            OUT_SendCANR_End_Time_Hr2_StsVld_SendCANR_End_Time_Hr2_StsVld: accessed-variable=SendCANR_End_Time_Hr2_StsVld.SendCANR_End_Time_Hr2_StsVld
            OUT_SendCANR_End_Time_Min1_Sts_SendCANR_End_Time_Min1_Sts: accessed-variable=SendCANR_End_Time_Min1_Sts.SendCANR_End_Time_Min1_Sts
            OUT_SendCANR_End_Time_Min1_StsVld_SendCANR_End_Time_Min1_StsVld: accessed-variable=SendCANR_End_Time_Min1_StsVld.SendCANR_End_Time_Min1_StsVld
            OUT_SendCANR_End_Time_Min2_Sts_SendCANR_End_Time_Min2_Sts: accessed-variable=SendCANR_End_Time_Min2_Sts.SendCANR_End_Time_Min2_Sts
            OUT_SendCANR_End_Time_Min2_StsVld_SendCANR_End_Time_Min2_StsVld: accessed-variable=SendCANR_End_Time_Min2_StsVld.SendCANR_End_Time_Min2_StsVld
            OUT_SendCANR_ExternalChrgTarget1Sts_SendCANR_ExternalChrgTarget1Sts: accessed-variable=SendCANR_ExternalChrgTarget1Sts.SendCANR_ExternalChrgTarget1Sts
            OUT_SendCANR_ExternalChrgTarget1StsVld_SendCANR_ExternalChrgTarget1StsVld: accessed-variable=SendCANR_ExternalChrgTarget1StsVld.SendCANR_ExternalChrgTarget1StsVld
            OUT_SendCANR_ExternalChrgTarget2Sts_SendCANR_ExternalChrgTarget2Sts: accessed-variable=SendCANR_ExternalChrgTarget2Sts.SendCANR_ExternalChrgTarget2Sts
            OUT_SendCANR_ExternalChrgTarget2StsVld_SendCANR_ExternalChrgTarget2StsVld: accessed-variable=SendCANR_ExternalChrgTarget2StsVld.SendCANR_ExternalChrgTarget2StsVld
            OUT_SendCANR_ImmediatChrgTarget1Sts_SendCANR_ImmediatChrgTarget1Sts: accessed-variable=SendCANR_ImmediatChrgTarget1Sts.SendCANR_ImmediatChrgTarget1Sts
            OUT_SendCANR_ImmediatChrgTarget1StsVld_SendCANR_ImmediatChrgTarget1StsVld: accessed-variable=SendCANR_ImmediatChrgTarget1StsVld.SendCANR_ImmediatChrgTarget1StsVld
            OUT_SendCANR_ImmediatChrgTarget2Sts_SendCANR_ImmediatChrgTarget2Sts: accessed-variable=SendCANR_ImmediatChrgTarget2Sts.SendCANR_ImmediatChrgTarget2Sts
            OUT_SendCANR_ImmediatChrgTarget2StsVld_SendCANR_ImmediatChrgTarget2StsVld: accessed-variable=SendCANR_ImmediatChrgTarget2StsVld.SendCANR_ImmediatChrgTarget2StsVld
            OUT_SendCANR_Schedule_Confirmed1_SendCANR_Schedule_Confirmed1: accessed-variable=SendCANR_Schedule_Confirmed1.SendCANR_Schedule_Confirmed1
            OUT_SendCANR_Schedule_Confirmed1Vld_SendCANR_Schedule_Confirmed1Vld: accessed-variable=SendCANR_Schedule_Confirmed1Vld.SendCANR_Schedule_Confirmed1Vld
            OUT_SendCANR_Schedule_Confirmed2_SendCANR_Schedule_Confirmed2: accessed-variable=SendCANR_Schedule_Confirmed2.SendCANR_Schedule_Confirmed2
            OUT_SendCANR_Schedule_Confirmed2Vld_SendCANR_Schedule_Confirmed2Vld: accessed-variable=SendCANR_Schedule_Confirmed2Vld.SendCANR_Schedule_Confirmed2Vld
            OUT_SendCANR_Schedule_Day1_Sts_SendCANR_Schedule_Day1_Sts: accessed-variable=SendCANR_Schedule_Day1_Sts.SendCANR_Schedule_Day1_Sts
            OUT_SendCANR_Schedule_Day1_StsVld_SendCANR_Schedule_Day1_StsVld: accessed-variable=SendCANR_Schedule_Day1_StsVld.SendCANR_Schedule_Day1_StsVld
            OUT_SendCANR_Schedule_Day2_Sts_SendCANR_Schedule_Day2_Sts: accessed-variable=SendCANR_Schedule_Day2_Sts.SendCANR_Schedule_Day2_Sts
            OUT_SendCANR_Schedule_Day2_StsVld_SendCANR_Schedule_Day2_StsVld: accessed-variable=SendCANR_Schedule_Day2_StsVld.SendCANR_Schedule_Day2_StsVld
            OUT_SendCANR_Start_Time_Hr1_Sts_SendCANR_Start_Time_Hr1_Sts: accessed-variable=SendCANR_Start_Time_Hr1_Sts.SendCANR_Start_Time_Hr1_Sts
            OUT_SendCANR_Start_Time_Hr1_StsVld_SendCANR_Start_Time_Hr1_StsVld: accessed-variable=SendCANR_Start_Time_Hr1_StsVld.SendCANR_Start_Time_Hr1_StsVld
            OUT_SendCANR_Start_Time_Hr2_Sts_SendCANR_Start_Time_Hr2_Sts: accessed-variable=SendCANR_Start_Time_Hr2_Sts.SendCANR_Start_Time_Hr2_Sts
            OUT_SendCANR_Start_Time_Hr2_StsVld_SendCANR_Start_Time_Hr2_StsVld: accessed-variable=SendCANR_Start_Time_Hr2_StsVld.SendCANR_Start_Time_Hr2_StsVld
            OUT_SendCANR_Start_Time_Min1_Sts_SendCANR_Start_Time_Min1_Sts: accessed-variable=SendCANR_Start_Time_Min1_Sts.SendCANR_Start_Time_Min1_Sts
            OUT_SendCANR_Start_Time_Min1_StsVld_SendCANR_Start_Time_Min1_StsVld: accessed-variable=SendCANR_Start_Time_Min1_StsVld.SendCANR_Start_Time_Min1_StsVld
            OUT_SendCANR_Start_Time_Min2_Sts_SendCANR_Start_Time_Min2_Sts: accessed-variable=SendCANR_Start_Time_Min2_Sts.SendCANR_Start_Time_Min2_Sts
            OUT_SendCANR_Start_Time_Min2_StsVld_SendCANR_Start_Time_Min2_StsVld: accessed-variable=SendCANR_Start_Time_Min2_StsVld.SendCANR_Start_Time_Min2_StsVld
            OUT_SendCANR_Next_Chrg_EndDay_SendCANR_Next_Chrg_EndDay: accessed-variable=SendCANR_Next_Chrg_EndDay.SendCANR_Next_Chrg_EndDay
            OUT_SendCANR_Next_Chrg_EndDayVld_SendCANR_Next_Chrg_EndDayVld: accessed-variable=SendCANR_Next_Chrg_EndDayVld.SendCANR_Next_Chrg_EndDayVld
            OUT_SendCANR_Next_Chrg_End_Time_Hr_SendCANR_Next_Chrg_End_Time_Hr: accessed-variable=SendCANR_Next_Chrg_End_Time_Hr.SendCANR_Next_Chrg_End_Time_Hr
            OUT_SendCANR_Next_Chrg_End_Time_HrVld_SendCANR_Next_Chrg_End_Time_HrVld: accessed-variable=SendCANR_Next_Chrg_End_Time_HrVld.SendCANR_Next_Chrg_End_Time_HrVld
            OUT_SendCANR_Next_Chrg_End_Time_Min_SendCANR_Next_Chrg_End_Time_Min: accessed-variable=SendCANR_Next_Chrg_End_Time_Min.SendCANR_Next_Chrg_End_Time_Min
            OUT_SendCANR_Next_Chrg_End_Time_MinVld_SendCANR_Next_Chrg_End_Time_MinVld: accessed-variable=SendCANR_Next_Chrg_End_Time_MinVld.SendCANR_Next_Chrg_End_Time_MinVld
            OUT_SendCANR_Next_Charge_StartDay_SendCANR_Next_Charge_StartDay: accessed-variable=SendCANR_Next_Charge_StartDay.SendCANR_Next_Charge_StartDay
            OUT_SendCANR_Next_Charge_StartDayVld_SendCANR_Next_Charge_StartDayVld: accessed-variable=SendCANR_Next_Charge_StartDayVld.SendCANR_Next_Charge_StartDayVld
            OUT_SendCANR_Next_Chrg_Strt_Time_Hr_SendCANR_Next_Chrg_Strt_Time_Hr: accessed-variable=SendCANR_Next_Chrg_Strt_Time_Hr.SendCANR_Next_Chrg_Strt_Time_Hr
            OUT_SendCANR_Next_Chrg_Strt_Time_HrVld_SendCANR_Next_Chrg_Strt_Time_HrVld: accessed-variable=SendCANR_Next_Chrg_Strt_Time_HrVld.SendCANR_Next_Chrg_Strt_Time_HrVld
            OUT_SendCANR_NextChrg_Strt_Time_Min_SendCANR_NextChrg_Strt_Time_Min: accessed-variable=SendCANR_NextChrg_Strt_Time_Min.SendCANR_NextChrg_Strt_Time_Min
            OUT_SendCANR_NextChrg_Strt_Time_MinVld_SendCANR_NextChrg_Strt_Time_MinVld: accessed-variable=SendCANR_NextChrg_Strt_Time_MinVld.SendCANR_NextChrg_Strt_Time_MinVld
            OUT_SendCANR_Next_Climate_Day_SendCANR_Next_Climate_Day: accessed-variable=SendCANR_Next_Climate_Day.SendCANR_Next_Climate_Day
            OUT_SendCANR_Next_Climate_DayVld_SendCANR_Next_Climate_DayVld: accessed-variable=SendCANR_Next_Climate_DayVld.SendCANR_Next_Climate_DayVld
            OUT_SendCANR_Next_Climate_Time_Hr_SendCANR_Next_Climate_Time_Hr: accessed-variable=SendCANR_Next_Climate_Time_Hr.SendCANR_Next_Climate_Time_Hr
            OUT_SendCANR_Next_Climate_Time_HrVld_SendCANR_Next_Climate_Time_HrVld: accessed-variable=SendCANR_Next_Climate_Time_HrVld.SendCANR_Next_Climate_Time_HrVld
            OUT_SendCANR_Next_Climate_Time_Min_SendCANR_Next_Climate_Time_Min: accessed-variable=SendCANR_Next_Climate_Time_Min.SendCANR_Next_Climate_Time_Min
            OUT_SendCANR_Next_Climate_Time_MinVld_SendCANR_Next_Climate_Time_MinVld: accessed-variable=SendCANR_Next_Climate_Time_MinVld.SendCANR_Next_Climate_Time_MinVld
            OUT_SendCANR_Next_SchCabin_Temp_SendCANR_Next_SchCabin_Temp: accessed-variable=SendCANR_Next_SchCabin_Temp.SendCANR_Next_SchCabin_Temp
            OUT_SendCANR_Next_SchCabin_TempVld_SendCANR_Next_SchCabin_TempVld: accessed-variable=SendCANR_Next_SchCabin_TempVld.SendCANR_Next_SchCabin_TempVld
            OUT_SendCANR_Nxt_ChargeScheduleType_SendCANR_Nxt_ChargeScheduleType: accessed-variable=SendCANR_Nxt_ChargeScheduleType.SendCANR_Nxt_ChargeScheduleType
            OUT_SendCANR_Nxt_ChargeScheduleTypeVld_SendCANR_Nxt_ChargeScheduleTypeVld: accessed-variable=SendCANR_Nxt_ChargeScheduleTypeVld.SendCANR_Nxt_ChargeScheduleTypeVld
            OUT_SendCANR_NxtExtChargEndTimeHr_SendCANR_NxtExtChargEndTimeHr: accessed-variable=SendCANR_NxtExtChargEndTimeHr.SendCANR_NxtExtChargEndTimeHr
            OUT_SendCANR_NxtExtChargEndTimeHrVld_SendCANR_NxtExtChargEndTimeHrVld: accessed-variable=SendCANR_NxtExtChargEndTimeHrVld.SendCANR_NxtExtChargEndTimeHrVld
            OUT_SendCANR_NxtExtChargeEndTimeMin_SendCANR_NxtExtChargeEndTimeMin: accessed-variable=SendCANR_NxtExtChargeEndTimeMin.SendCANR_NxtExtChargeEndTimeMin
            OUT_SendCANR_NxtExtChargeEndTimeMinVld_SendCANR_NxtExtChargeEndTimeMinVld: accessed-variable=SendCANR_NxtExtChargeEndTimeMinVld.SendCANR_NxtExtChargeEndTimeMinVld
            OUT_SendCANR_NxtExternalChargEndDay_SendCANR_NxtExternalChargEndDay: accessed-variable=SendCANR_NxtExternalChargEndDay.SendCANR_NxtExternalChargEndDay
            OUT_SendCANR_NxtExternalChargEndDayVld_SendCANR_NxtExternalChargEndDayVld: accessed-variable=SendCANR_NxtExternalChargEndDayVld.SendCANR_NxtExternalChargEndDayVld
            OUT_SendCANR_NxtExternlChrgExtnlTgt_SendCANR_NxtExternlChrgExtnlTgt: accessed-variable=SendCANR_NxtExternlChrgExtnlTgt.SendCANR_NxtExternlChrgExtnlTgt
            OUT_SendCANR_NxtExternlChrgExtnlTgtVld_SendCANR_NxtExternlChrgExtnlTgtVld: accessed-variable=SendCANR_NxtExternlChrgExtnlTgtVld.SendCANR_NxtExternlChrgExtnlTgtVld
            OUT_SendCANR_NxtExtnlChrgImediatTgt_SendCANR_NxtExtnlChrgImediatTgt: accessed-variable=SendCANR_NxtExtnlChrgImediatTgt.SendCANR_NxtExtnlChrgImediatTgt
            OUT_SendCANR_NxtExtnlChrgImediatTgtVld_SendCANR_NxtExtnlChrgImediatTgtVld: accessed-variable=SendCANR_NxtExtnlChrgImediatTgtVld.SendCANR_NxtExtnlChrgImediatTgtVld
            OUT_SendCANR_AllowClimateSchd1_Sts_SendCANR_AllowClimateSchd1_Sts: accessed-variable=SendCANR_AllowClimateSchd1_Sts.SendCANR_AllowClimateSchd1_Sts
            OUT_SendCANR_AllowClimateSchd1_StsVld_SendCANR_AllowClimateSchd1_StsVld: accessed-variable=SendCANR_AllowClimateSchd1_StsVld.SendCANR_AllowClimateSchd1_StsVld
            OUT_SendCANR_AllowClimateSchd2_Sts_SendCANR_AllowClimateSchd2_Sts: accessed-variable=SendCANR_AllowClimateSchd2_Sts.SendCANR_AllowClimateSchd2_Sts
            OUT_SendCANR_AllowClimateSchd2_StsVld_SendCANR_AllowClimateSchd2_StsVld: accessed-variable=SendCANR_AllowClimateSchd2_StsVld.SendCANR_AllowClimateSchd2_StsVld
            OUT_SendCANR_ClimateSchd1_Day_Sts_SendCANR_ClimateSchd1_Day_Sts: accessed-variable=SendCANR_ClimateSchd1_Day_Sts.SendCANR_ClimateSchd1_Day_Sts
            OUT_SendCANR_ClimateSchd1_Day_StsVld_SendCANR_ClimateSchd1_Day_StsVld: accessed-variable=SendCANR_ClimateSchd1_Day_StsVld.SendCANR_ClimateSchd1_Day_StsVld
            OUT_SendCANR_ClimateSchd1DprtrHrSts_SendCANR_ClimateSchd1DprtrHrSts: accessed-variable=SendCANR_ClimateSchd1DprtrHrSts.SendCANR_ClimateSchd1DprtrHrSts
            OUT_SendCANR_ClimateSchd1DprtrHrStsVld_SendCANR_ClimateSchd1DprtrHrStsVld: accessed-variable=SendCANR_ClimateSchd1DprtrHrStsVld.SendCANR_ClimateSchd1DprtrHrStsVld
            OUT_SendCANR_ClimSchd1Dprtr_Min_Sts_SendCANR_ClimSchd1Dprtr_Min_Sts: accessed-variable=SendCANR_ClimSchd1Dprtr_Min_Sts.SendCANR_ClimSchd1Dprtr_Min_Sts
            OUT_SendCANR_ClimSchd1Dprtr_Min_StsVld_SendCANR_ClimSchd1Dprtr_Min_StsVld: accessed-variable=SendCANR_ClimSchd1Dprtr_Min_StsVld.SendCANR_ClimSchd1Dprtr_Min_StsVld
            OUT_SendCANR_ClimateSchd2_Day_Sts_SendCANR_ClimateSchd2_Day_Sts: accessed-variable=SendCANR_ClimateSchd2_Day_Sts.SendCANR_ClimateSchd2_Day_Sts
            OUT_SendCANR_ClimateSchd2_Day_StsVld_SendCANR_ClimateSchd2_Day_StsVld: accessed-variable=SendCANR_ClimateSchd2_Day_StsVld.SendCANR_ClimateSchd2_Day_StsVld
            OUT_SendCANR_ClimateSchd2DprtrHrSts_SendCANR_ClimateSchd2DprtrHrSts: accessed-variable=SendCANR_ClimateSchd2DprtrHrSts.SendCANR_ClimateSchd2DprtrHrSts
            OUT_SendCANR_ClimateSchd2DprtrHrStsVld_SendCANR_ClimateSchd2DprtrHrStsVld: accessed-variable=SendCANR_ClimateSchd2DprtrHrStsVld.SendCANR_ClimateSchd2DprtrHrStsVld
            OUT_SendCANR_ClimatSchd2DprtrMinSts_SendCANR_ClimatSchd2DprtrMinSts: accessed-variable=SendCANR_ClimatSchd2DprtrMinSts.SendCANR_ClimatSchd2DprtrMinSts
            OUT_SendCANR_ClimatSchd2DprtrMinStsVld_SendCANR_ClimatSchd2DprtrMinStsVld: accessed-variable=SendCANR_ClimatSchd2DprtrMinStsVld.SendCANR_ClimatSchd2DprtrMinStsVld
            OUT_SendCANR_Climate_Cabin_Temp1Sts_SendCANR_Climate_Cabin_Temp1Sts: accessed-variable=SendCANR_Climate_Cabin_Temp1Sts.SendCANR_Climate_Cabin_Temp1Sts
            OUT_SendCANR_Climate_Cabin_Temp1StsVld_SendCANR_Climate_Cabin_Temp1StsVld: accessed-variable=SendCANR_Climate_Cabin_Temp1StsVld.SendCANR_Climate_Cabin_Temp1StsVld
            OUT_SendCANR_Climate_Cabin_Temp2Sts_SendCANR_Climate_Cabin_Temp2Sts: accessed-variable=SendCANR_Climate_Cabin_Temp2Sts.SendCANR_Climate_Cabin_Temp2Sts
            OUT_SendCANR_Climate_Cabin_Temp2StsVld_SendCANR_Climate_Cabin_Temp2StsVld: accessed-variable=SendCANR_Climate_Cabin_Temp2StsVld.SendCANR_Climate_Cabin_Temp2StsVld
            OUT_SendCANR_Enbl_ClimateSchd1_Sts_SendCANR_Enbl_ClimateSchd1_Sts: accessed-variable=SendCANR_Enbl_ClimateSchd1_Sts.SendCANR_Enbl_ClimateSchd1_Sts
            OUT_SendCANR_Enbl_ClimateSchd1_StsVld_SendCANR_Enbl_ClimateSchd1_StsVld: accessed-variable=SendCANR_Enbl_ClimateSchd1_StsVld.SendCANR_Enbl_ClimateSchd1_StsVld
            OUT_SendCANR_Enabl_ClimateSchd2_Sts_SendCANR_Enabl_ClimateSchd2_Sts: accessed-variable=SendCANR_Enabl_ClimateSchd2_Sts.SendCANR_Enabl_ClimateSchd2_Sts
            OUT_SendCANR_Enabl_ClimateSchd2_StsVld_SendCANR_Enabl_ClimateSchd2_StsVld: accessed-variable=SendCANR_Enabl_ClimateSchd2_StsVld.SendCANR_Enabl_ClimateSchd2_StsVld
            OUT_SendCANR_Ready_Status_EVCU2_SendCANR_Ready_Status_EVCU2: accessed-variable=SendCANR_Ready_Status_EVCU2.SendCANR_Ready_Status_EVCU2, variation-point={short-label=vpOUT_SendCANR_Ready_Status_EVCU2_SendCANR_Ready_Status_EVCU2, sw-syscond=1}
            OUT_SendCANR_Ready_Status_EVCU2Vld_SendCANR_Ready_Status_EVCU2Vld: accessed-variable=SendCANR_Ready_Status_EVCU2Vld.SendCANR_Ready_Status_EVCU2Vld, variation-point={short-label=vpOUT_SendCANR_Ready_Status_EVCU2Vld_SendCANR_Ready_Status_EVCU2Vld, sw-syscond=1}
            OUT_SendCANR_Chargeport_Lock_Status_SendCANR_Chargeport_Lock_Status: accessed-variable=SendCANR_Chargeport_Lock_Status.SendCANR_Chargeport_Lock_Status
            OUT_SendCANR_Chargeport_Lock_StatusVld_SendCANR_Chargeport_Lock_StatusVld: accessed-variable=SendCANR_Chargeport_Lock_StatusVld.SendCANR_Chargeport_Lock_StatusVld
            OUT_SendCANR_Cooperative_Status_SendCANR_Cooperative_Status: accessed-variable=SendCANR_Cooperative_Status.SendCANR_Cooperative_Status
            OUT_SendCANR_Cooperative_StatusVld_SendCANR_Cooperative_StatusVld: accessed-variable=SendCANR_Cooperative_StatusVld.SendCANR_Cooperative_StatusVld
            OUT_SendCANR_EVSE_Power_SendCANR_EVSE_Power: accessed-variable=SendCANR_EVSE_Power.SendCANR_EVSE_Power, variation-point={short-label=vpOUT_SendCANR_EVSE_Power_SendCANR_EVSE_Power, sw-syscond=1}
            OUT_SendCANR_EVSE_PowerVld_SendCANR_EVSE_PowerVld: accessed-variable=SendCANR_EVSE_PowerVld.SendCANR_EVSE_PowerVld, variation-point={short-label=vpOUT_SendCANR_EVSE_PowerVld_SendCANR_EVSE_PowerVld, sw-syscond=1}
            OUT_SendCANR_EV_Charge_Current_SendCANR_EV_Charge_Current: accessed-variable=SendCANR_EV_Charge_Current.SendCANR_EV_Charge_Current, variation-point={short-label=vpOUT_SendCANR_EV_Charge_Current_SendCANR_EV_Charge_Current, sw-syscond=1}
            OUT_SendCANR_EV_Charge_CurrentVld_SendCANR_EV_Charge_CurrentVld: accessed-variable=SendCANR_EV_Charge_CurrentVld.SendCANR_EV_Charge_CurrentVld, variation-point={short-label=vpOUT_SendCANR_EV_Charge_CurrentVld_SendCANR_EV_Charge_CurrentVld, sw-syscond=1}
            OUT_SendCANR_Energy_to_Battery_SendCANR_Energy_to_Battery: accessed-variable=SendCANR_Energy_to_Battery.SendCANR_Energy_to_Battery, variation-point={short-label=vpOUT_SendCANR_Energy_to_Battery_SendCANR_Energy_to_Battery, sw-syscond=1}
            OUT_SendCANR_Energy_to_BatteryVld_SendCANR_Energy_to_BatteryVld: accessed-variable=SendCANR_Energy_to_BatteryVld.SendCANR_Energy_to_BatteryVld, variation-point={short-label=vpOUT_SendCANR_Energy_to_BatteryVld_SendCANR_Energy_to_BatteryVld, sw-syscond=1}
            OUT_SendCANR_Total_Battery_Capacity_SendCANR_Total_Battery_Capacity: accessed-variable=SendCANR_Total_Battery_Capacity.SendCANR_Total_Battery_Capacity, variation-point={short-label=vpOUT_SendCANR_Total_Battery_Capacity_SendCANR_Total_Battery_Capacity, sw-syscond=1}
            OUT_SendCANR_Total_Battery_CapacityVld_SendCANR_Total_Battery_CapacityVld: accessed-variable=SendCANR_Total_Battery_CapacityVld.SendCANR_Total_Battery_CapacityVld, variation-point={short-label=vpOUT_SendCANR_Total_Battery_CapacityVld_SendCANR_Total_Battery_CapacityVld, sw-syscond=1}
            OUT_SendCANR_DischrgingSysStatusFD3_SendCANR_DischrgingSysStatusFD3: accessed-variable=SendCANR_DischrgingSysStatusFD3.SendCANR_DischrgingSysStatusFD3
            OUT_SendCANR_DischrgingSysStatusFD3Vld_SendCANR_DischrgingSysStatusFD3Vld: accessed-variable=SendCANR_DischrgingSysStatusFD3Vld.SendCANR_DischrgingSysStatusFD3Vld
            OUT_SendCANR_Launch_Hard_Btn_LED_SendCANR_Launch_Hard_Btn_LED: accessed-variable=SendCANR_Launch_Hard_Btn_LED.SendCANR_Launch_Hard_Btn_LED, variation-point={short-label=vpOUT_SendCANR_Launch_Hard_Btn_LED_SendCANR_Launch_Hard_Btn_LED, sw-syscond=1}
            OUT_SendCANR_Launch_Hard_Btn_LED_Vld_SendCANR_Launch_Hard_Btn_LED_Vld: accessed-variable=SendCANR_Launch_Hard_Btn_LED_Vld.SendCANR_Launch_Hard_Btn_LED_Vld, variation-point={short-label=vpOUT_SendCANR_Launch_Hard_Btn_LED_Vld_SendCANR_Launch_Hard_Btn_LED_Vld, sw-syscond=1}
            OUT_SendCANR_PnC_Failure_SendCANR_PnC_Failure: accessed-variable=SendCANR_PnC_Failure.SendCANR_PnC_Failure
            OUT_SendCANR_PnC_FailureVld_SendCANR_PnC_FailureVld: accessed-variable=SendCANR_PnC_FailureVld.SendCANR_PnC_FailureVld
            OUT_SendCANR_PnC_Reattepmt_Failure_SendCANR_PnC_Reattepmt_Failure: accessed-variable=SendCANR_PnC_Reattepmt_Failure.SendCANR_PnC_Reattepmt_Failure
            OUT_SendCANR_PnC_Reattepmt_FailureVld_SendCANR_PnC_Reattepmt_FailureVld: accessed-variable=SendCANR_PnC_Reattepmt_FailureVld.SendCANR_PnC_Reattepmt_FailureVld
            OUT_SendCANR_RACE_PREP_AMBIENT_TMP_SendCANR_RACE_PREP_AMBIENT_TMP: accessed-variable=SendCANR_RACE_PREP_AMBIENT_TMP.SendCANR_RACE_PREP_AMBIENT_TMP, variation-point={short-label=vpOUT_SendCANR_RACE_PREP_AMBIENT_TMP_SendCANR_RACE_PREP_AMBIENT_TMP, sw-syscond=1}
            OUT_SendCANR_RACE_PREP_AMBIENT_TMP_Vld_SendCANR_RACE_PREP_AMBIENT_TMP_Vld: accessed-variable=SendCANR_RACE_PREP_AMBIENT_TMP_Vld.SendCANR_RACE_PREP_AMBIENT_TMP_Vld, variation-point={short-label=vpOUT_SendCANR_RACE_PREP_AMBIENT_TMP_Vld_SendCANR_RACE_PREP_AMBIENT_TMP_Vld, sw-syscond=1}
            OUT_SendCANR_RACE_PREP_BATT_LVL_STS_SendCANR_RACE_PREP_BATT_LVL_STS: accessed-variable=SendCANR_RACE_PREP_BATT_LVL_STS.SendCANR_RACE_PREP_BATT_LVL_STS, variation-point={short-label=vpOUT_SendCANR_RACE_PREP_BATT_LVL_STS_SendCANR_RACE_PREP_BATT_LVL_STS, sw-syscond=1}
            OUT_SendCANR_RACE_PREP_BATT_LVL_STS_Vld_SendCANR_RACE_PREP_BATT_LVL_STS_Vld: accessed-variable=SendCANR_RACE_PREP_BATT_LVL_STS_Vld.SendCANR_RACE_PREP_BATT_LVL_STS_Vld, variation-point={short-label=vpOUT_SendCANR_RACE_PREP_BATT_LVL_STS_Vld_SendCANR_RACE_PREP_BATT_LVL_STS_Vld, sw-syscond=1}
            OUT_SendCANR_RACE_PREP_EV_DEAC_TIME_SendCANR_RACE_PREP_EV_DEAC_TIME: accessed-variable=SendCANR_RACE_PREP_EV_DEAC_TIME.SendCANR_RACE_PREP_EV_DEAC_TIME, variation-point={short-label=vpOUT_SendCANR_RACE_PREP_EV_DEAC_TIME_SendCANR_RACE_PREP_EV_DEAC_TIME, sw-syscond=1}
            OUT_SendCANR_RACE_PREP_EV_DEAC_TIME_Vld_SendCANR_RACE_PREP_EV_DEAC_TIME_Vld: accessed-variable=SendCANR_RACE_PREP_EV_DEAC_TIME_Vld.SendCANR_RACE_PREP_EV_DEAC_TIME_Vld, variation-point={short-label=vpOUT_SendCANR_RACE_PREP_EV_DEAC_TIME_Vld_SendCANR_RACE_PREP_EV_DEAC_TIME_Vld, sw-syscond=1}
            OUT_SendCANR_RACE_PREP_EV_SYS_STS_SendCANR_RACE_PREP_EV_SYS_STS: accessed-variable=SendCANR_RACE_PREP_EV_SYS_STS.SendCANR_RACE_PREP_EV_SYS_STS, variation-point={short-label=vpOUT_SendCANR_RACE_PREP_EV_SYS_STS_SendCANR_RACE_PREP_EV_SYS_STS, sw-syscond=1}
            OUT_SendCANR_RACE_PREP_EV_SYS_STS_Vld_SendCANR_RACE_PREP_EV_SYS_STS_Vld: accessed-variable=SendCANR_RACE_PREP_EV_SYS_STS_Vld.SendCANR_RACE_PREP_EV_SYS_STS_Vld, variation-point={short-label=vpOUT_SendCANR_RACE_PREP_EV_SYS_STS_Vld_SendCANR_RACE_PREP_EV_SYS_STS_Vld, sw-syscond=1}
            OUT_SendCANR_RACE_PRP_HVBTT_SOC_TGT_SendCANR_RACE_PRP_HVBTT_SOC_TGT: accessed-variable=SendCANR_RACE_PRP_HVBTT_SOC_TGT.SendCANR_RACE_PRP_HVBTT_SOC_TGT, variation-point={short-label=vpOUT_SendCANR_RACE_PRP_HVBTT_SOC_TGT_SendCANR_RACE_PRP_HVBTT_SOC_TGT, sw-syscond=1}
            OUT_SendCANR_RACE_PRP_HVBTT_SOC_TGT_Vld_SendCANR_RACE_PRP_HVBTT_SOC_TGT_Vld: accessed-variable=SendCANR_RACE_PRP_HVBTT_SOC_TGT_Vld.SendCANR_RACE_PRP_HVBTT_SOC_TGT_Vld, variation-point={short-label=vpOUT_SendCANR_RACE_PRP_HVBTT_SOC_TGT_Vld_SendCANR_RACE_PRP_HVBTT_SOC_TGT_Vld, sw-syscond=1}
            OUT_SendCANR_RACE_PREP_RCE_TYP_STS_SendCANR_RACE_PREP_RCE_TYP_STS: accessed-variable=SendCANR_RACE_PREP_RCE_TYP_STS.SendCANR_RACE_PREP_RCE_TYP_STS, variation-point={short-label=vpOUT_SendCANR_RACE_PREP_RCE_TYP_STS_SendCANR_RACE_PREP_RCE_TYP_STS, sw-syscond=1}
            OUT_SendCANR_RACE_PREP_RCE_TYP_STS_Vld_SendCANR_RACE_PREP_RCE_TYP_STS_Vld: accessed-variable=SendCANR_RACE_PREP_RCE_TYP_STS_Vld.SendCANR_RACE_PREP_RCE_TYP_STS_Vld, variation-point={short-label=vpOUT_SendCANR_RACE_PREP_RCE_TYP_STS_Vld_SendCANR_RACE_PREP_RCE_TYP_STS_Vld, sw-syscond=1}
            OUT_SendCANR_RACE_PREP_THERMAL_TGT_SendCANR_RACE_PREP_THERMAL_TGT: accessed-variable=SendCANR_RACE_PREP_THERMAL_TGT.SendCANR_RACE_PREP_THERMAL_TGT, variation-point={short-label=vpOUT_SendCANR_RACE_PREP_THERMAL_TGT_SendCANR_RACE_PREP_THERMAL_TGT, sw-syscond=1}
            OUT_SendCANR_RACE_PREP_THERMAL_TGT_Vld_SendCANR_RACE_PREP_THERMAL_TGT_Vld: accessed-variable=SendCANR_RACE_PREP_THERMAL_TGT_Vld.SendCANR_RACE_PREP_THERMAL_TGT_Vld, variation-point={short-label=vpOUT_SendCANR_RACE_PREP_THERMAL_TGT_Vld_SendCANR_RACE_PREP_THERMAL_TGT_Vld, sw-syscond=1}
            OUT_SendCANR_RI_AC_FAN_Range_SendCANR_RI_AC_FAN_Range: accessed-variable=SendCANR_RI_AC_FAN_Range.SendCANR_RI_AC_FAN_Range, variation-point={short-label=vpOUT_SendCANR_RI_AC_FAN_Range_SendCANR_RI_AC_FAN_Range, sw-syscond=1}
            OUT_SendCANR_RI_AC_FAN_RangeVld_SendCANR_RI_AC_FAN_RangeVld: accessed-variable=SendCANR_RI_AC_FAN_RangeVld.SendCANR_RI_AC_FAN_RangeVld, variation-point={short-label=vpOUT_SendCANR_RI_AC_FAN_RangeVld_SendCANR_RI_AC_FAN_RangeVld, sw-syscond=1}
            OUT_SendCANR_RI_AUDIO_Range_SendCANR_RI_AUDIO_Range: accessed-variable=SendCANR_RI_AUDIO_Range.SendCANR_RI_AUDIO_Range, variation-point={short-label=vpOUT_SendCANR_RI_AUDIO_Range_SendCANR_RI_AUDIO_Range, sw-syscond=1}
            OUT_SendCANR_RI_AUDIO_RangeVld_SendCANR_RI_AUDIO_RangeVld: accessed-variable=SendCANR_RI_AUDIO_RangeVld.SendCANR_RI_AUDIO_RangeVld, variation-point={short-label=vpOUT_SendCANR_RI_AUDIO_RangeVld_SendCANR_RI_AUDIO_RangeVld, sw-syscond=1}
            OUT_SendCANR_RI_DEFROST_Range_SendCANR_RI_DEFROST_Range: accessed-variable=SendCANR_RI_DEFROST_Range.SendCANR_RI_DEFROST_Range, variation-point={short-label=vpOUT_SendCANR_RI_DEFROST_Range_SendCANR_RI_DEFROST_Range, sw-syscond=1}
            OUT_SendCANR_RI_DEFROST_RangeVld_SendCANR_RI_DEFROST_RangeVld: accessed-variable=SendCANR_RI_DEFROST_RangeVld.SendCANR_RI_DEFROST_RangeVld, variation-point={short-label=vpOUT_SendCANR_RI_DEFROST_RangeVld_SendCANR_RI_DEFROST_RangeVld, sw-syscond=1}
            OUT_SendCANR_RI_LIGHTS_Range_SendCANR_RI_LIGHTS_Range: accessed-variable=SendCANR_RI_LIGHTS_Range.SendCANR_RI_LIGHTS_Range, variation-point={short-label=vpOUT_SendCANR_RI_LIGHTS_Range_SendCANR_RI_LIGHTS_Range, sw-syscond=1}
            OUT_SendCANR_RI_LIGHTS_RangeVld_SendCANR_RI_LIGHTS_RangeVld: accessed-variable=SendCANR_RI_LIGHTS_RangeVld.SendCANR_RI_LIGHTS_RangeVld, variation-point={short-label=vpOUT_SendCANR_RI_LIGHTS_RangeVld_SendCANR_RI_LIGHTS_RangeVld, sw-syscond=1}
            OUT_SendCANR_RI_OTHER_Range_SendCANR_RI_OTHER_Range: accessed-variable=SendCANR_RI_OTHER_Range.SendCANR_RI_OTHER_Range, variation-point={short-label=vpOUT_SendCANR_RI_OTHER_Range_SendCANR_RI_OTHER_Range, sw-syscond=1}
            OUT_SendCANR_RI_OTHER_RangeVld_SendCANR_RI_OTHER_RangeVld: accessed-variable=SendCANR_RI_OTHER_RangeVld.SendCANR_RI_OTHER_RangeVld, variation-point={short-label=vpOUT_SendCANR_RI_OTHER_RangeVld_SendCANR_RI_OTHER_RangeVld, sw-syscond=1}
            OUT_SendCANR_RI_SEATSWHL_Range_SendCANR_RI_SEATSWHL_Range: accessed-variable=SendCANR_RI_SEATSWHL_Range.SendCANR_RI_SEATSWHL_Range, variation-point={short-label=vpOUT_SendCANR_RI_SEATSWHL_Range_SendCANR_RI_SEATSWHL_Range, sw-syscond=1}
            OUT_SendCANR_RI_SEATSWHL_RangeVld_SendCANR_RI_SEATSWHL_RangeVld: accessed-variable=SendCANR_RI_SEATSWHL_RangeVld.SendCANR_RI_SEATSWHL_RangeVld, variation-point={short-label=vpOUT_SendCANR_RI_SEATSWHL_RangeVld_SendCANR_RI_SEATSWHL_RangeVld, sw-syscond=1}
            OUT_SendCANR_RI_TOTAL_Range_Add_SendCANR_RI_TOTAL_Range_Add: accessed-variable=SendCANR_RI_TOTAL_Range_Add.SendCANR_RI_TOTAL_Range_Add, variation-point={short-label=vpOUT_SendCANR_RI_TOTAL_Range_Add_SendCANR_RI_TOTAL_Range_Add, sw-syscond=1}
            OUT_SendCANR_RI_TOTAL_Range_AddVld_SendCANR_RI_TOTAL_Range_AddVld: accessed-variable=SendCANR_RI_TOTAL_Range_AddVld.SendCANR_RI_TOTAL_Range_AddVld, variation-point={short-label=vpOUT_SendCANR_RI_TOTAL_Range_AddVld_SendCANR_RI_TOTAL_Range_AddVld, sw-syscond=1}
            OUT_SendCANR_Racemode_Popup_PT_SendCANR_Racemode_Popup_PT: accessed-variable=SendCANR_Racemode_Popup_PT.SendCANR_Racemode_Popup_PT
            OUT_SendCANR_Racemode_Popup_PT_Vld_SendCANR_Racemode_Popup_PT_Vld: accessed-variable=SendCANR_Racemode_Popup_PT_Vld.SendCANR_Racemode_Popup_PT_Vld
            OUT_SendCANR_CabinConditioningSts_SendCANR_CabinConditioningSts: accessed-variable=SendCANR_CabinConditioningSts.SendCANR_CabinConditioningSts
            OUT_SendCANR_CabinConditioningStsVld_SendCANR_CabinConditioningStsVld: accessed-variable=SendCANR_CabinConditioningStsVld.SendCANR_CabinConditioningStsVld
            OUT_SendCANR_CbnPreconditionReqSts_SendCANR_CbnPreconditionReqSts: accessed-variable=SendCANR_CbnPreconditionReqSts.SendCANR_CbnPreconditionReqSts
            OUT_SendCANR_CbnPreconditionReqStsVld_SendCANR_CbnPreconditionReqStsVld: accessed-variable=SendCANR_CbnPreconditionReqStsVld.SendCANR_CbnPreconditionReqStsVld
            OUT_SendCANR_CompressorState_SendCANR_CompressorState: accessed-variable=SendCANR_CompressorState.SendCANR_CompressorState
            OUT_SendCANR_CompressorStateVld_SendCANR_CompressorStateVld: accessed-variable=SendCANR_CompressorStateVld.SendCANR_CompressorStateVld
            OUT_SendCANR_ElecClntHtrInletTemp_SendCANR_ElecClntHtrInletTemp: accessed-variable=SendCANR_ElecClntHtrInletTemp.SendCANR_ElecClntHtrInletTemp
            OUT_SendCANR_ElecClntHtrInletTempVld_SendCANR_ElecClntHtrInletTempVld: accessed-variable=SendCANR_ElecClntHtrInletTempVld.SendCANR_ElecClntHtrInletTempVld
            OUT_SendCANR_ElecCoolantHtrPwr_SendCANR_ElecCoolantHtrPwr: accessed-variable=SendCANR_ElecCoolantHtrPwr.SendCANR_ElecCoolantHtrPwr
            OUT_SendCANR_ElecCoolantHtrPwrVld_SendCANR_ElecCoolantHtrPwrVld: accessed-variable=SendCANR_ElecCoolantHtrPwrVld.SendCANR_ElecCoolantHtrPwrVld
            OUT_SendCANR_FRfShVlvSts_SendCANR_FRfShVlvSts: accessed-variable=SendCANR_FRfShVlvSts.SendCANR_FRfShVlvSts
            OUT_SendCANR_FRfShVlvStsVld_SendCANR_FRfShVlvStsVld: accessed-variable=SendCANR_FRfShVlvStsVld.SendCANR_FRfShVlvStsVld
            OUT_SendCANR_HTAuxPmpMontrngRPM_SendCANR_HTAuxPmpMontrngRPM: accessed-variable=SendCANR_HTAuxPmpMontrngRPM.SendCANR_HTAuxPmpMontrngRPM
            OUT_SendCANR_HTAuxPmpMontrngRPM_Vld_SendCANR_HTAuxPmpMontrngRPM_Vld: accessed-variable=SendCANR_HTAuxPmpMontrngRPM_Vld.SendCANR_HTAuxPmpMontrngRPM_Vld
            OUT_SendCANR_HTAuxPmpRPMAct_SendCANR_HTAuxPmpRPMAct: accessed-variable=SendCANR_HTAuxPmpRPMAct.SendCANR_HTAuxPmpRPMAct
            OUT_SendCANR_HTAuxPmpRPMActVld_SendCANR_HTAuxPmpRPMActVld: accessed-variable=SendCANR_HTAuxPmpRPMActVld.SendCANR_HTAuxPmpRPMActVld
            OUT_SendCANR_HTShtOffVlvReq_SendCANR_HTShtOffVlvReq: accessed-variable=SendCANR_HTShtOffVlvReq.SendCANR_HTShtOffVlvReq
            OUT_SendCANR_HTShtOffVlvReqVld_SendCANR_HTShtOffVlvReqVld: accessed-variable=SendCANR_HTShtOffVlvReqVld.SendCANR_HTShtOffVlvReqVld
            OUT_SendCANR_HVBatCoolantLvlLo_DPT_SendCANR_HVBatCoolantLvlLo_DPT: accessed-variable=SendCANR_HVBatCoolantLvlLo_DPT.SendCANR_HVBatCoolantLvlLo_DPT
            OUT_SendCANR_HVBatCoolantLvlLo_DPT_Vld_SendCANR_HVBatCoolantLvlLo_DPT_Vld: accessed-variable=SendCANR_HVBatCoolantLvlLo_DPT_Vld.SendCANR_HVBatCoolantLvlLo_DPT_Vld
            OUT_SendCANR_HVBatCritCondT_SendCANR_HVBatCritCondT: accessed-variable=SendCANR_HVBatCritCondT.SendCANR_HVBatCritCondT
            OUT_SendCANR_HVBatCritCondT_Vld_SendCANR_HVBatCritCondT_Vld: accessed-variable=SendCANR_HVBatCritCondT_Vld.SendCANR_HVBatCritCondT_Vld
            OUT_SendCANR_HeaterCoreInletTemp_SendCANR_HeaterCoreInletTemp: accessed-variable=SendCANR_HeaterCoreInletTemp.SendCANR_HeaterCoreInletTemp
            OUT_SendCANR_HeaterCoreInletTempVld_SendCANR_HeaterCoreInletTempVld: accessed-variable=SendCANR_HeaterCoreInletTempVld.SendCANR_HeaterCoreInletTempVld
            OUT_SendCANR_RearAirHtrCoreTemp_SendCANR_RearAirHtrCoreTemp: accessed-variable=SendCANR_RearAirHtrCoreTemp.SendCANR_RearAirHtrCoreTemp
            OUT_SendCANR_RearAirHtrCoreTempVld_SendCANR_RearAirHtrCoreTempVld: accessed-variable=SendCANR_RearAirHtrCoreTempVld.SendCANR_RearAirHtrCoreTempVld
            OUT_SendCANR_RearAirHtrPCBTemp_SendCANR_RearAirHtrPCBTemp: accessed-variable=SendCANR_RearAirHtrPCBTemp.SendCANR_RearAirHtrPCBTemp
            OUT_SendCANR_RearAirHtrPCBTempVld_SendCANR_RearAirHtrPCBTempVld: accessed-variable=SendCANR_RearAirHtrPCBTempVld.SendCANR_RearAirHtrPCBTempVld
            OUT_SendCANR_RearAirHtrPwrCnsAct_SendCANR_RearAirHtrPwrCnsAct: accessed-variable=SendCANR_RearAirHtrPwrCnsAct.SendCANR_RearAirHtrPwrCnsAct
            OUT_SendCANR_RearAirHtrPwrCnsActVld_SendCANR_RearAirHtrPwrCnsActVld: accessed-variable=SendCANR_RearAirHtrPwrCnsActVld.SendCANR_RearAirHtrPwrCnsActVld
            OUT_SendCANR_SchCond_Time_Till_Dep_SendCANR_SchCond_Time_Till_Dep: accessed-variable=SendCANR_SchCond_Time_Till_Dep.SendCANR_SchCond_Time_Till_Dep
            OUT_SendCANR_SchCond_Time_Till_DepVld_SendCANR_SchCond_Time_Till_DepVld: accessed-variable=SendCANR_SchCond_Time_Till_DepVld.SendCANR_SchCond_Time_Till_DepVld
            OUT_SendCANR_Sch_PreCondition_Sts_SendCANR_Sch_PreCondition_Sts: accessed-variable=SendCANR_Sch_PreCondition_Sts.SendCANR_Sch_PreCondition_Sts
            OUT_SendCANR_Sch_PreCondition_StsVld_SendCANR_Sch_PreCondition_StsVld: accessed-variable=SendCANR_Sch_PreCondition_StsVld.SendCANR_Sch_PreCondition_StsVld
            OUT_SendCANR_V2H_Discharge_Capacity_SendCANR_V2H_Discharge_Capacity: accessed-variable=SendCANR_V2H_Discharge_Capacity.SendCANR_V2H_Discharge_Capacity, variation-point={short-label=vpOUT_SendCANR_V2H_Discharge_Capacity_SendCANR_V2H_Discharge_Capacity, sw-syscond=1}
            OUT_SendCANR_V2H_Discharge_CapacityVld_SendCANR_V2H_Discharge_CapacityVld: accessed-variable=SendCANR_V2H_Discharge_CapacityVld.SendCANR_V2H_Discharge_CapacityVld, variation-point={short-label=vpOUT_SendCANR_V2H_Discharge_CapacityVld_SendCANR_V2H_Discharge_CapacityVld, sw-syscond=1}
            OUT_SendCANR_MotorA_DC_Current_SendCANR_MotorA_DC_Current: accessed-variable=SendCANR_MotorA_DC_Current.SendCANR_MotorA_DC_Current, variation-point={short-label=vpOUT_SendCANR_MotorA_DC_Current_SendCANR_MotorA_DC_Current, sw-syscond=1}
            OUT_SendCANR_MotorA_DC_CurrentVld_SendCANR_MotorA_DC_CurrentVld: accessed-variable=SendCANR_MotorA_DC_CurrentVld.SendCANR_MotorA_DC_CurrentVld, variation-point={short-label=vpOUT_SendCANR_MotorA_DC_CurrentVld_SendCANR_MotorA_DC_CurrentVld, sw-syscond=1}
            OUT_SendCANR_MotorA_DC_Voltage_SendCANR_MotorA_DC_Voltage: accessed-variable=SendCANR_MotorA_DC_Voltage.SendCANR_MotorA_DC_Voltage, variation-point={short-label=vpOUT_SendCANR_MotorA_DC_Voltage_SendCANR_MotorA_DC_Voltage, sw-syscond=1}
            OUT_SendCANR_MotorA_DC_VoltageVld_SendCANR_MotorA_DC_VoltageVld: accessed-variable=SendCANR_MotorA_DC_VoltageVld.SendCANR_MotorA_DC_VoltageVld, variation-point={short-label=vpOUT_SendCANR_MotorA_DC_VoltageVld_SendCANR_MotorA_DC_VoltageVld, sw-syscond=1}
            OUT_SendCANR_MotorA_InverterState_SendCANR_MotorA_InverterState: accessed-variable=SendCANR_MotorA_InverterState.SendCANR_MotorA_InverterState, variation-point={short-label=vpOUT_SendCANR_MotorA_InverterState_SendCANR_MotorA_InverterState, sw-syscond=1}
            OUT_SendCANR_MotorA_InverterTemp_SendCANR_MotorA_InverterTemp: accessed-variable=SendCANR_MotorA_InverterTemp.SendCANR_MotorA_InverterTemp, variation-point={short-label=vpOUT_SendCANR_MotorA_InverterTemp_SendCANR_MotorA_InverterTemp, sw-syscond=1}
            OUT_SendCANR_MotorA_InverterTempVld_SendCANR_MotorA_InverterTempVld: accessed-variable=SendCANR_MotorA_InverterTempVld.SendCANR_MotorA_InverterTempVld, variation-point={short-label=vpOUT_SendCANR_MotorA_InverterTempVld_SendCANR_MotorA_InverterTempVld, sw-syscond=1}
            OUT_SendCANR_MotorA_RPM_SendCANR_MotorA_RPM: accessed-variable=SendCANR_MotorA_RPM.SendCANR_MotorA_RPM, variation-point={short-label=vpOUT_SendCANR_MotorA_RPM_SendCANR_MotorA_RPM, sw-syscond=1}
            OUT_SendCANR_MotorA_RPM_Vld_SendCANR_MotorA_RPM_Vld: accessed-variable=SendCANR_MotorA_RPM_Vld.SendCANR_MotorA_RPM_Vld, variation-point={short-label=vpOUT_SendCANR_MotorA_RPM_Vld_SendCANR_MotorA_RPM_Vld, sw-syscond=1}
            OUT_SendCANR_MotorA_Temperature_SendCANR_MotorA_Temperature: accessed-variable=SendCANR_MotorA_Temperature.SendCANR_MotorA_Temperature, variation-point={short-label=vpOUT_SendCANR_MotorA_Temperature_SendCANR_MotorA_Temperature, sw-syscond=1}
            OUT_SendCANR_MotorA_TemperatureVld_SendCANR_MotorA_TemperatureVld: accessed-variable=SendCANR_MotorA_TemperatureVld.SendCANR_MotorA_TemperatureVld, variation-point={short-label=vpOUT_SendCANR_MotorA_TemperatureVld_SendCANR_MotorA_TemperatureVld, sw-syscond=1}
            OUT_SendCANR_MotorA_TorqueAchieved_SendCANR_MotorA_TorqueAchieved: accessed-variable=SendCANR_MotorA_TorqueAchieved.SendCANR_MotorA_TorqueAchieved, variation-point={short-label=vpOUT_SendCANR_MotorA_TorqueAchieved_SendCANR_MotorA_TorqueAchieved, sw-syscond=1}
            OUT_SendCANR_MotorA_TorqueAchievedVld_SendCANR_MotorA_TorqueAchievedVld: accessed-variable=SendCANR_MotorA_TorqueAchievedVld.SendCANR_MotorA_TorqueAchievedVld, variation-point={short-label=vpOUT_SendCANR_MotorA_TorqueAchievedVld_SendCANR_MotorA_TorqueAchievedVld, sw-syscond=1}
            OUT_SendCANR_MotorB_DC_Current_SendCANR_MotorB_DC_Current: accessed-variable=SendCANR_MotorB_DC_Current.SendCANR_MotorB_DC_Current
            OUT_SendCANR_MotorB_DC_CurrentVld_SendCANR_MotorB_DC_CurrentVld: accessed-variable=SendCANR_MotorB_DC_CurrentVld.SendCANR_MotorB_DC_CurrentVld
            OUT_SendCANR_MotorB_DC_Voltage_SendCANR_MotorB_DC_Voltage: accessed-variable=SendCANR_MotorB_DC_Voltage.SendCANR_MotorB_DC_Voltage
            OUT_SendCANR_MotorB_DC_VoltageVld_SendCANR_MotorB_DC_VoltageVld: accessed-variable=SendCANR_MotorB_DC_VoltageVld.SendCANR_MotorB_DC_VoltageVld
            OUT_SendCANR_MotorB_InverterState_SendCANR_MotorB_InverterState: accessed-variable=SendCANR_MotorB_InverterState.SendCANR_MotorB_InverterState
            OUT_SendCANR_MotorB_InverterStateVld_SendCANR_MotorB_InverterStateVld: accessed-variable=SendCANR_MotorB_InverterStateVld.SendCANR_MotorB_InverterStateVld
            OUT_SendCANR_MotorB_InverterTemp_SendCANR_MotorB_InverterTemp: accessed-variable=SendCANR_MotorB_InverterTemp.SendCANR_MotorB_InverterTemp
            OUT_SendCANR_MotorB_InverterTempVld_SendCANR_MotorB_InverterTempVld: accessed-variable=SendCANR_MotorB_InverterTempVld.SendCANR_MotorB_InverterTempVld
            OUT_SendCANR_MotorB_RPM_SendCANR_MotorB_RPM: accessed-variable=SendCANR_MotorB_RPM.SendCANR_MotorB_RPM
            OUT_SendCANR_MotorB_RPM_Vld_SendCANR_MotorB_RPM_Vld: accessed-variable=SendCANR_MotorB_RPM_Vld.SendCANR_MotorB_RPM_Vld
            OUT_SendCANR_MotorB_Temperature_SendCANR_MotorB_Temperature: accessed-variable=SendCANR_MotorB_Temperature.SendCANR_MotorB_Temperature
            OUT_SendCANR_MotorB_TemperatureVld_SendCANR_MotorB_TemperatureVld: accessed-variable=SendCANR_MotorB_TemperatureVld.SendCANR_MotorB_TemperatureVld
            OUT_SendCANR_MotorB_TorqueAchieved_SendCANR_MotorB_TorqueAchieved: accessed-variable=SendCANR_MotorB_TorqueAchieved.SendCANR_MotorB_TorqueAchieved
            OUT_SendCANR_MotorB_TorqueAchievedVld_SendCANR_MotorB_TorqueAchievedVld: accessed-variable=SendCANR_MotorB_TorqueAchievedVld.SendCANR_MotorB_TorqueAchievedVld
            OUT_SendCANR_AirflowRequest_SendCANR_AirflowRequest: accessed-variable=SendCANR_AirflowRequest.SendCANR_AirflowRequest
            OUT_SendCANR_AirflowRequestVld_SendCANR_AirflowRequestVld: accessed-variable=SendCANR_AirflowRequestVld.SendCANR_AirflowRequestVld
            OUT_SendCANR_RadiatorFanSts_SendCANR_RadiatorFanSts: accessed-variable=SendCANR_RadiatorFanSts.SendCANR_RadiatorFanSts
            OUT_SendCANR_RadiatorFanStsVld_SendCANR_RadiatorFanStsVld: accessed-variable=SendCANR_RadiatorFanStsVld.SendCANR_RadiatorFanStsVld
            OUT_SendCANR_Syst_Actual_Charge_Lim_SendCANR_Syst_Actual_Charge_Lim: accessed-variable=SendCANR_Syst_Actual_Charge_Lim.SendCANR_Syst_Actual_Charge_Lim, variation-point={short-label=vpOUT_SendCANR_Syst_Actual_Charge_Lim_SendCANR_Syst_Actual_Charge_Lim, sw-syscond=1}
            OUT_SendCANR_Syst_Actual_Charge_LimVld_SendCANR_Syst_Actual_Charge_LimVld: accessed-variable=SendCANR_Syst_Actual_Charge_LimVld.SendCANR_Syst_Actual_Charge_LimVld, variation-point={short-label=vpOUT_SendCANR_Syst_Actual_Charge_LimVld_SendCANR_Syst_Actual_Charge_LimVld, sw-syscond=1}
            OUT_SendCANR_Syst_Actual_Charge_Pwr_SendCANR_Syst_Actual_Charge_Pwr: accessed-variable=SendCANR_Syst_Actual_Charge_Pwr.SendCANR_Syst_Actual_Charge_Pwr, variation-point={short-label=vpOUT_SendCANR_Syst_Actual_Charge_Pwr_SendCANR_Syst_Actual_Charge_Pwr, sw-syscond=1}
            OUT_SendCANR_Syst_Actual_Charge_PwrVld_SendCANR_Syst_Actual_Charge_PwrVld: accessed-variable=SendCANR_Syst_Actual_Charge_PwrVld.SendCANR_Syst_Actual_Charge_PwrVld, variation-point={short-label=vpOUT_SendCANR_Syst_Actual_Charge_PwrVld_SendCANR_Syst_Actual_Charge_PwrVld, sw-syscond=1}
            OUT_SendCANR_MCPA_Temp_FD3_SendCANR_MCPA_Temp_FD3: accessed-variable=SendCANR_MCPA_Temp_FD3.SendCANR_MCPA_Temp_FD3, variation-point={short-label=vpOUT_SendCANR_MCPA_Temp_FD3_SendCANR_MCPA_Temp_FD3, sw-syscond=1}
            OUT_SendCANR_MCPA_Temp_FD3Vld_SendCANR_MCPA_Temp_FD3Vld: accessed-variable=SendCANR_MCPA_Temp_FD3Vld.SendCANR_MCPA_Temp_FD3Vld, variation-point={short-label=vpOUT_SendCANR_MCPA_Temp_FD3Vld_SendCANR_MCPA_Temp_FD3Vld, sw-syscond=1}
            OUT_SendCANR_V2H_Instant_Power_Draw_SendCANR_V2H_Instant_Power_Draw: accessed-variable=SendCANR_V2H_Instant_Power_Draw.SendCANR_V2H_Instant_Power_Draw, variation-point={short-label=vpOUT_SendCANR_V2H_Instant_Power_Draw_SendCANR_V2H_Instant_Power_Draw, sw-syscond=1}
            OUT_SendCANR_V2H_Instant_Power_DrawVld_SendCANR_V2H_Instant_Power_DrawVld: accessed-variable=SendCANR_V2H_Instant_Power_DrawVld.SendCANR_V2H_Instant_Power_DrawVld, variation-point={short-label=vpOUT_SendCANR_V2H_Instant_Power_DrawVld_SendCANR_V2H_Instant_Power_DrawVld, sw-syscond=1}
            OUT_SendCANR_V2H_Reserve_BatterySts_SendCANR_V2H_Reserve_BatterySts: accessed-variable=SendCANR_V2H_Reserve_BatterySts.SendCANR_V2H_Reserve_BatterySts, variation-point={short-label=vpOUT_SendCANR_V2H_Reserve_BatterySts_SendCANR_V2H_Reserve_BatterySts, sw-syscond=1}
            OUT_SendCANR_V2H_Reserve_BatteryStsVld_SendCANR_V2H_Reserve_BatteryStsVld: accessed-variable=SendCANR_V2H_Reserve_BatteryStsVld.SendCANR_V2H_Reserve_BatteryStsVld, variation-point={short-label=vpOUT_SendCANR_V2H_Reserve_BatteryStsVld_SendCANR_V2H_Reserve_BatteryStsVld, sw-syscond=1}
            OUT_SendCANR_V2H_Status_SendCANR_V2H_Status: accessed-variable=SendCANR_V2H_Status.SendCANR_V2H_Status, variation-point={short-label=vpOUT_SendCANR_V2H_Status_SendCANR_V2H_Status, sw-syscond=1}
            OUT_SendCANR_V2H_StatusVld_SendCANR_V2H_StatusVld: accessed-variable=SendCANR_V2H_StatusVld.SendCANR_V2H_StatusVld, variation-point={short-label=vpOUT_SendCANR_V2H_StatusVld_SendCANR_V2H_StatusVld, sw-syscond=1}
            OUT_SendCANR_V2H_TotalPowerTimedays_SendCANR_V2H_TotalPowerTimedays: accessed-variable=SendCANR_V2H_TotalPowerTimedays.SendCANR_V2H_TotalPowerTimedays, variation-point={short-label=vpOUT_SendCANR_V2H_TotalPowerTimedays_SendCANR_V2H_TotalPowerTimedays, sw-syscond=1}
            OUT_SendCANR_V2H_TotalPowerTimedaysVld_SendCANR_V2H_TotalPowerTimedaysVld: accessed-variable=SendCANR_V2H_TotalPowerTimedaysVld.SendCANR_V2H_TotalPowerTimedaysVld, variation-point={short-label=vpOUT_SendCANR_V2H_TotalPowerTimedaysVld_SendCANR_V2H_TotalPowerTimedaysVld, sw-syscond=1}
            OUT_SendCANR_V2HTotalPowerTimehours_SendCANR_V2HTotalPowerTimehours: accessed-variable=SendCANR_V2HTotalPowerTimehours.SendCANR_V2HTotalPowerTimehours, variation-point={short-label=vpOUT_SendCANR_V2HTotalPowerTimehours_SendCANR_V2HTotalPowerTimehours, sw-syscond=1}
            OUT_SendCANR_V2HTotalPowerTimehoursVld_SendCANR_V2HTotalPowerTimehoursVld: accessed-variable=SendCANR_V2HTotalPowerTimehoursVld.SendCANR_V2HTotalPowerTimehoursVld, variation-point={short-label=vpOUT_SendCANR_V2HTotalPowerTimehoursVld_SendCANR_V2HTotalPowerTimehoursVld, sw-syscond=1}
            OUT_SendCANR_V2HTotalPowerTimeminut_SendCANR_V2HTotalPowerTimeminut: accessed-variable=SendCANR_V2HTotalPowerTimeminut.SendCANR_V2HTotalPowerTimeminut, variation-point={short-label=vpOUT_SendCANR_V2HTotalPowerTimeminut_SendCANR_V2HTotalPowerTimeminut, sw-syscond=1}
            OUT_SendCANR_V2HTotalPowerTimeminutVld_SendCANR_V2HTotalPowerTimeminutVld: accessed-variable=SendCANR_V2HTotalPowerTimeminutVld.SendCANR_V2HTotalPowerTimeminutVld, variation-point={short-label=vpOUT_SendCANR_V2HTotalPowerTimeminutVld_SendCANR_V2HTotalPowerTimeminutVld, sw-syscond=1}
            OUT_SendCANR_V2H_mode_Sts_SendCANR_V2H_mode_Sts: accessed-variable=SendCANR_V2H_mode_Sts.SendCANR_V2H_mode_Sts, variation-point={short-label=vpOUT_SendCANR_V2H_mode_Sts_SendCANR_V2H_mode_Sts, sw-syscond=1}
            OUT_SendCANR_V2H_mode_StsVld_SendCANR_V2H_mode_StsVld: accessed-variable=SendCANR_V2H_mode_StsVld.SendCANR_V2H_mode_StsVld, variation-point={short-label=vpOUT_SendCANR_V2H_mode_StsVld_SendCANR_V2H_mode_StsVld, sw-syscond=1}
            OUT_SendCANR_V2L_Frunk_Status_SendCANR_V2L_Frunk_Status: accessed-variable=SendCANR_V2L_Frunk_Status.SendCANR_V2L_Frunk_Status
            OUT_SendCANR_V2L_Frunk_StatusVld_SendCANR_V2L_Frunk_StatusVld: accessed-variable=SendCANR_V2L_Frunk_StatusVld.SendCANR_V2L_Frunk_StatusVld
            OUT_SendCANR_V2LInstantPwrDrawFrunk_SendCANR_V2LInstantPwrDrawFrunk: accessed-variable=SendCANR_V2LInstantPwrDrawFrunk.SendCANR_V2LInstantPwrDrawFrunk
            OUT_SendCANR_V2LInstantPwrDrawFrunkVld_SendCANR_V2LInstantPwrDrawFrunkVld: accessed-variable=SendCANR_V2LInstantPwrDrawFrunkVld.SendCANR_V2LInstantPwrDrawFrunkVld
            OUT_SendCANR_V2LInstantPwrDrawTrunk_SendCANR_V2LInstantPwrDrawTrunk: accessed-variable=SendCANR_V2LInstantPwrDrawTrunk.SendCANR_V2LInstantPwrDrawTrunk
            OUT_SendCANR_V2LInstantPwrDrawTrunkVld_SendCANR_V2LInstantPwrDrawTrunkVld: accessed-variable=SendCANR_V2LInstantPwrDrawTrunkVld.SendCANR_V2LInstantPwrDrawTrunkVld
            OUT_SendCANR_V2L_Total_PwrTimedays_SendCANR_V2L_Total_PwrTimedays: accessed-variable=SendCANR_V2L_Total_PwrTimedays.SendCANR_V2L_Total_PwrTimedays
            OUT_SendCANR_V2L_Total_PwrTimedaysVld_SendCANR_V2L_Total_PwrTimedaysVld: accessed-variable=SendCANR_V2L_Total_PwrTimedaysVld.SendCANR_V2L_Total_PwrTimedaysVld
            OUT_SendCANR_V2LTotalPowerTimehours_SendCANR_V2LTotalPowerTimehours: accessed-variable=SendCANR_V2LTotalPowerTimehours.SendCANR_V2LTotalPowerTimehours
            OUT_SendCANR_V2LTotalPowerTimehoursVld_SendCANR_V2LTotalPowerTimehoursVld: accessed-variable=SendCANR_V2LTotalPowerTimehoursVld.SendCANR_V2LTotalPowerTimehoursVld
            OUT_SendCANR_V2LTotalPowerTimeminut_SendCANR_V2LTotalPowerTimeminut: accessed-variable=SendCANR_V2LTotalPowerTimeminut.SendCANR_V2LTotalPowerTimeminut
            OUT_SendCANR_V2LTotalPowerTimeminutVld_SendCANR_V2LTotalPowerTimeminutVld: accessed-variable=SendCANR_V2LTotalPowerTimeminutVld.SendCANR_V2LTotalPowerTimeminutVld
            OUT_SendCANR_V2L_Trunk_Status_SendCANR_V2L_Trunk_Status: accessed-variable=SendCANR_V2L_Trunk_Status.SendCANR_V2L_Trunk_Status
            OUT_SendCANR_V2L_Trunk_StatusVld_SendCANR_V2L_Trunk_StatusVld: accessed-variable=SendCANR_V2L_Trunk_StatusVld.SendCANR_V2L_Trunk_StatusVld
            OUT_SendCANR_V2V_Instant_Power_Draw_SendCANR_V2V_Instant_Power_Draw: accessed-variable=SendCANR_V2V_Instant_Power_Draw.SendCANR_V2V_Instant_Power_Draw
            OUT_SendCANR_V2V_Instant_Power_DrawVld_SendCANR_V2V_Instant_Power_DrawVld: accessed-variable=SendCANR_V2V_Instant_Power_DrawVld.SendCANR_V2V_Instant_Power_DrawVld
            OUT_SendCANR_V2V_Status_SendCANR_V2V_Status: accessed-variable=SendCANR_V2V_Status.SendCANR_V2V_Status
            OUT_SendCANR_V2V_StatusVld_SendCANR_V2V_StatusVld: accessed-variable=SendCANR_V2V_StatusVld.SendCANR_V2V_StatusVld
            OUT_SendCANR_V2V_TotalPowerTimedays_SendCANR_V2V_TotalPowerTimedays: accessed-variable=SendCANR_V2V_TotalPowerTimedays.SendCANR_V2V_TotalPowerTimedays
            OUT_SendCANR_V2V_TotalPowerTimedaysVld_SendCANR_V2V_TotalPowerTimedaysVld: accessed-variable=SendCANR_V2V_TotalPowerTimedaysVld.SendCANR_V2V_TotalPowerTimedaysVld
            OUT_SendCANR_V2VTotalPowerTimehours_SendCANR_V2VTotalPowerTimehours: accessed-variable=SendCANR_V2VTotalPowerTimehours.SendCANR_V2VTotalPowerTimehours
            OUT_SendCANR_V2VTotalPowerTimehoursVld_SendCANR_V2VTotalPowerTimehoursVld: accessed-variable=SendCANR_V2VTotalPowerTimehoursVld.SendCANR_V2VTotalPowerTimehoursVld
            OUT_SendCANR_V2VTotalPowerTimeminut_SendCANR_V2VTotalPowerTimeminut: accessed-variable=SendCANR_V2VTotalPowerTimeminut.SendCANR_V2VTotalPowerTimeminut
            OUT_SendCANR_V2VTotalPowerTimeminutVld_SendCANR_V2VTotalPowerTimeminutVld: accessed-variable=SendCANR_V2VTotalPowerTimeminutVld.SendCANR_V2VTotalPowerTimeminutVld
            OUT_SendCANR_P2P_Timer_SendCANR_P2P_Timer: accessed-variable=SendCANR_P2P_Timer.SendCANR_P2P_Timer
            OUT_SendCANR_P2P_TimerVld_SendCANR_P2P_TimerVld: accessed-variable=SendCANR_P2P_TimerVld.SendCANR_P2P_TimerVld
            OUT_SendCANR_PwrSht_Prep_Prt_Cmplt_SendCANR_PwrSht_Prep_Prt_Cmplt: accessed-variable=SendCANR_PwrSht_Prep_Prt_Cmplt.SendCANR_PwrSht_Prep_Prt_Cmplt
            OUT_SendCANR_PwrSht_Prep_Prt_CmpltVld_SendCANR_PwrSht_Prep_Prt_CmpltVld: accessed-variable=SendCANR_PwrSht_Prep_Prt_CmpltVld.SendCANR_PwrSht_Prep_Prt_CmpltVld
            OUT_SendCANR_Turtle_Speed_Limit_SendCANR_Turtle_Speed_Limit: accessed-variable=SendCANR_Turtle_Speed_Limit.SendCANR_Turtle_Speed_Limit
            OUT_SendCANR_Turtle_Speed_LimitVld_SendCANR_Turtle_Speed_LimitVld: accessed-variable=SendCANR_Turtle_Speed_LimitVld.SendCANR_Turtle_Speed_LimitVld
            OUT_SendCANR_T4_Sensor_Temp_FD3_SendCANR_T4_Sensor_Temp_FD3: accessed-variable=SendCANR_T4_Sensor_Temp_FD3.SendCANR_T4_Sensor_Temp_FD3
            OUT_SendCANR_T4_Sensor_Temp_FD3Vld_SendCANR_T4_Sensor_Temp_FD3Vld: accessed-variable=SendCANR_T4_Sensor_Temp_FD3Vld.SendCANR_T4_Sensor_Temp_FD3Vld
      51 x variation point proxy, all with category=CONDITION:
        VrntCT1B_EVChargeCurrent_OBCRIChrgCrntReqDelta: condition-access=1
        VrntCT1B_EVSEPower_OBCRPEVSEPwr: condition-access=1
        VrntCT1B_EnergytoBattery_OBCRPPowertoBattery: condition-access=1
        VrntCT1B_EstRangeFuel_ERERlEstRangeFuel: condition-access=0
        VrntCT1B_EstRangeTotal_ERERlEstRangeTotal: condition-access=0
        VrntCT1B_LaunchHardBtnLED_TIMReLaunchMdSwtchLED: condition-access=1
        VrntCT1B_MCPATemp_INVRTMtrATemp: condition-access=1
        VrntCT1B_MCPATemp_INVRTMtrCTemp: condition-access=0
        VrntCT1B_MotorADCCurrent_INVRIMtrADCCrnt: condition-access=1
        VrntCT1B_MotorADCCurrent_INVRIMtrCDCCrnt: condition-access=0
        VrntCT1B_MotorADCVoltage_INVRUMtrADCVolt: condition-access=1
        VrntCT1B_MotorADCVoltage_INVRUMtrCDCVolt: condition-access=0
        VrntCT1B_MotorAInverterState_INVReMtrAInvrtrSt: condition-access=1
        VrntCT1B_MotorAInverterState_INVReMtrCInvrtrSt: condition-access=0
        VrntCT1B_MotorAInverterTemp_INVRTMtrAInvrtrTemp: condition-access=1
        VrntCT1B_MotorAInverterTemp_INVRTMtrCInvrtrTemp: condition-access=0
        VrntCT1B_MotorARPM_MSPRnMtrASpd: condition-access=1
        VrntCT1B_MotorARPM_MSPRnMtrCSpd: condition-access=0
        VrntCT1B_MotorATemperature_INVRTMtrATemp: condition-access=1
        VrntCT1B_MotorATemperature_INVRTMtrCTemp: condition-access=0
        VrntCT1B_MotorATorqueAchieved_MTIRMMtrATorqAchieved: condition-access=1
        VrntCT1B_MotorATorqueAchieved_MTIRMMtrCTorqAchieved: condition-access=0
        VrntCT1B_RACEPREPAMBIENTTMP_TPCRbRacePrepAmbCheck: condition-access=1
        VrntCT1B_RACEPREPBATTLVLSTS_OBCRbRacePrepBattLvlSts: condition-access=1
        VrntCT1B_RACEPREPEVDEACTIME_TPCRtRacePrepDeacTime: condition-access=1
        VrntCT1B_RACEPREPEVSYSTEMSTATUS_TPCRbRacePrepEVSysStatus: condition-access=1
        VrntCT1B_RACEPREPHVBATTSOCTGT_TPCRTRacePrepSOCTrgt: condition-access=1
        VrntCT1B_RACEPREPRACETYPESTS_TIMReRacePrepRaceTypeSts: condition-access=1
        VrntCT1B_RACEPREPTHERMALTGT_TPCRTRacePrepThrmlTrgt: condition-access=1
        VrntCT1B_RELSDFailureSts_SABRyRELSDFailureSts: condition-access=0
        VrntCT1B_RELSDStatus_SABRyRELSDStatus: condition-access=0
        VrntCT1B_RELSDTgtTrq_SABRMRELSDTgtTrq: condition-access=0
        VrntCT1B_RIACFANRange_ERERlACFanRange: condition-access=1
        VrntCT1B_RIAUDIORange_ERERlAudioRange: condition-access=1
        VrntCT1B_RIDEFROSTRange_ERERlDefrostRange: condition-access=1
        VrntCT1B_RILIGHTSRange_ERERlLightsRange: condition-access=1
        VrntCT1B_RIOTHERRange_ERERlOtherRange: condition-access=1
        VrntCT1B_RISEATSWHLRange_ERERlSeatswhlRange: condition-access=1
        VrntCT1B_RITOTALRangeAdd_ERERlTotalRange: condition-access=1
        VrntCT1B_ReadyStatusEVCU2_VTHReFOTAReadySts: condition-access=1
        VrntCT1B_SystActualChargeLim_OBCRPActChargePowerLim: condition-access=1
        VrntCT1B_SystActualChargePwr_OBCRPActChargePower: condition-access=1
        VrntCT1B_TotalBatteryCapacity_OBCRqBatteryAmpHrCap: condition-access=1
        VrntCT1B_V2HDischargeCapacity_VTHRPV2HDschgCap: condition-access=1
        VrntCT1B_V2HInstantPowerDraw_VTHRPV2HInstPwrDraw: condition-access=1
        VrntCT1B_V2HReserveBatterySts_VTHRPctV2HResrvBattSts: condition-access=1
        VrntCT1B_V2HStatus_VTHReV2HSts: condition-access=1
        VrntCT1B_V2HTotalPowerTimedays_VTHRtV2HTotPwrDays: condition-access=1
        VrntCT1B_V2HTotalPowerTimehours_VTHRtV2HTotPwrHrs: condition-access=1
        VrntCT1B_V2HTotalPowerTimeminutes_VTHRtV2HTotPwrMin: condition-access=1
        VrntCT1B_V2HmodeSts_VTHRbV2HMdSts: condition-access=1
